VERSION ""

NS_ :

BS_:

BU_: TBox

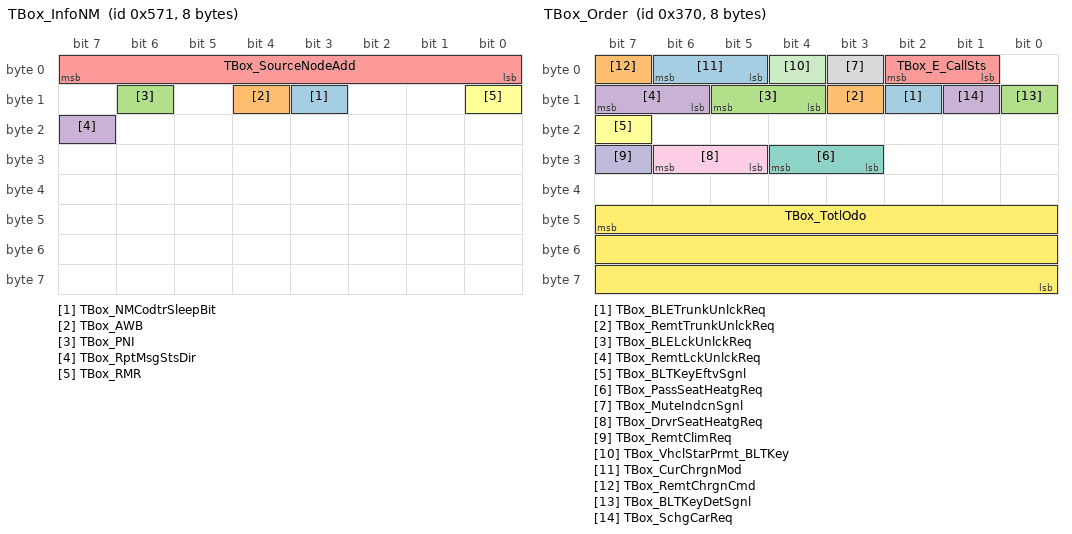
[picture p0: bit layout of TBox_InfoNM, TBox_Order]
BO_ 1393 TBox_InfoNM: 8 TBox
 SG_ TBox_NMCodtrSleepBit : 11|1@0+ (1,0) [0|1] "" HU,AMP,CGW
 SG_ TBox_AWB : 12|1@0+ (1,0) [0|1] "" HU,AMP,CGW
 SG_ TBox_PNI : 14|1@0+ (1,0) [0|1] "" HU,AMP,CGW
 SG_ TBox_RptMsgStsDir : 23|1@0+ (1,0) [0|1] "" Vector__XXX
 SG_ TBox_SourceNodeAdd : 7|8@0+ (1,0) [113|113] "" HU,AMP,CGW
 SG_ TBox_RMR : 8|1@0+ (1,0) [0|1] "" HU,AMP,CGW

BO_ 880 TBox_Order: 8 TBox
 SG_ TBox_BLETrunkUnlckReq : 10|1@0+ (1,0) [0|1] "" CGW
 SG_ TBox_RemtTrunkUnlckReq : 11|1@0+ (1,0) [0|1] "" CGW
 SG_ TBox_BLELckUnlckReq : 13|2@0+ (1,0) [0|3] "" CGW
 SG_ TBox_RemtLckUnlckReq : 15|2@0+ (1,0) [0|3] "" CGW
 SG_ TBox_E_CallSts : 2|2@0+ (1,0) [0|3] "" HU,CGW
 SG_ TBox_BLTKeyEftvSgnl : 23|1@0+ (1,0) [0|1] "" CGW
 SG_ TBox_PassSeatHeatgReq : 28|2@0+ (1,0) [0|3] "" CGW
 SG_ TBox_MuteIndcnSgnl : 3|1@0+ (1,0) [0|1] "" HU,CGW
 SG_ TBox_DrvrSeatHeatgReq : 30|2@0+ (1,0) [0|3] "" CGW
 SG_ TBox_RemtClimReq : 31|1@0+ (1,0) [0|1] "" CGW
 SG_ TBox_VhclStarPrmt_BLTKey : 4|1@0+ (1,0) [0|1] "" CGW
 SG_ TBox_TotlOdo : 47|24@0+ (0.1,0) [0|999999.9] "km" HU,CGW
 SG_ TBox_CurChrgnMod : 6|2@0+ (1,0) [0|3] "" HU,CGW
 SG_ TBox_RemtChrgnCmd : 7|1@0+ (1,0) [0|1] "" CGW
 SG_ TBox_BLTKeyDetSgnl : 8|1@0+ (1,0) [0|1] "" CGW
 SG_ TBox_SchgCarReq : 9|1@0+ (1,0) [0|1] "" CGW

BO_ 15 ACU_CrshInd: 8 CGW
 SG_ ACU_CrshActv : 7|3@0+ (1,0) [0|7] "" TBox

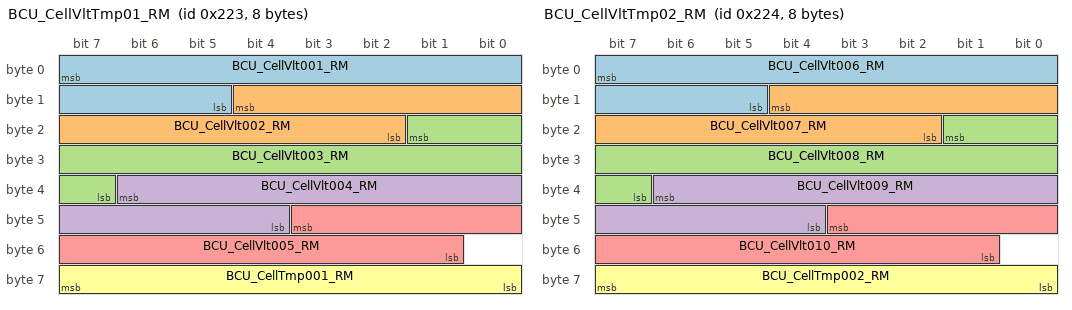
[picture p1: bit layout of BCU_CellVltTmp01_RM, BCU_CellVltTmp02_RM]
BO_ 547 BCU_CellVltTmp01_RM: 8 CGW
 SG_ BCU_CellVlt001_RM : 7|11@0+ (0.01,0) [0|18] "V" TBox
 SG_ BCU_CellVlt002_RM : 12|11@0+ (0.01,0) [0|18] "V" TBox
 SG_ BCU_CellVlt003_RM : 17|11@0+ (0.01,0) [0|18] "V" TBox
 SG_ BCU_CellVlt004_RM : 38|11@0+ (0.01,0) [0|18] "V" TBox
 SG_ BCU_CellVlt005_RM : 43|11@0+ (0.01,0) [0|18] "V" TBox
 SG_ BCU_CellTmp001_RM : 63|8@0+ (1,-40) [-40|120] "℃" TBox

BO_ 548 BCU_CellVltTmp02_RM: 8 CGW
 SG_ BCU_CellVlt006_RM : 7|11@0+ (0.01,0) [0|18] "V" TBox
 SG_ BCU_CellVlt007_RM : 12|11@0+ (0.01,0) [0|18] "V" TBox
 SG_ BCU_CellVlt008_RM : 17|11@0+ (0.01,0) [0|18] "V" TBox
 SG_ BCU_CellVlt009_RM : 38|11@0+ (0.01,0) [0|18] "V" TBox
 SG_ BCU_CellVlt010_RM : 43|11@0+ (0.01,0) [0|18] "V" TBox
 SG_ BCU_CellTmp002_RM : 63|8@0+ (1,-40) [-40|120] "℃" TBox

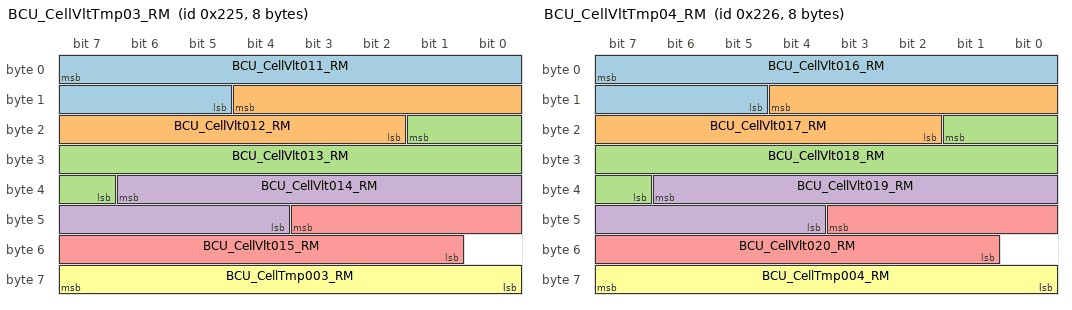
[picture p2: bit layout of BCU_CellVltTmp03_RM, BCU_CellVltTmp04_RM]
BO_ 549 BCU_CellVltTmp03_RM: 8 CGW
 SG_ BCU_CellVlt011_RM : 7|11@0+ (0.01,0) [0|18] "V" TBox
 SG_ BCU_CellVlt012_RM : 12|11@0+ (0.01,0) [0|18] "V" TBox
 SG_ BCU_CellVlt013_RM : 17|11@0+ (0.01,0) [0|18] "V" TBox
 SG_ BCU_CellVlt014_RM : 38|11@0+ (0.01,0) [0|18] "V" TBox
 SG_ BCU_CellVlt015_RM : 43|11@0+ (0.01,0) [0|18] "V" TBox
 SG_ BCU_CellTmp003_RM : 63|8@0+ (1,-40) [-40|120] "℃" TBox

BO_ 550 BCU_CellVltTmp04_RM: 8 CGW
 SG_ BCU_CellVlt016_RM : 7|11@0+ (0.01,0) [0|18] "V" TBox
 SG_ BCU_CellVlt017_RM : 12|11@0+ (0.01,0) [0|18] "V" TBox
 SG_ BCU_CellVlt018_RM : 17|11@0+ (0.01,0) [0|18] "V" TBox
 SG_ BCU_CellVlt019_RM : 38|11@0+ (0.01,0) [0|18] "V" TBox
 SG_ BCU_CellVlt020_RM : 43|11@0+ (0.01,0) [0|18] "V" TBox
 SG_ BCU_CellTmp004_RM : 63|8@0+ (1,-40) [-40|120] "℃" TBox

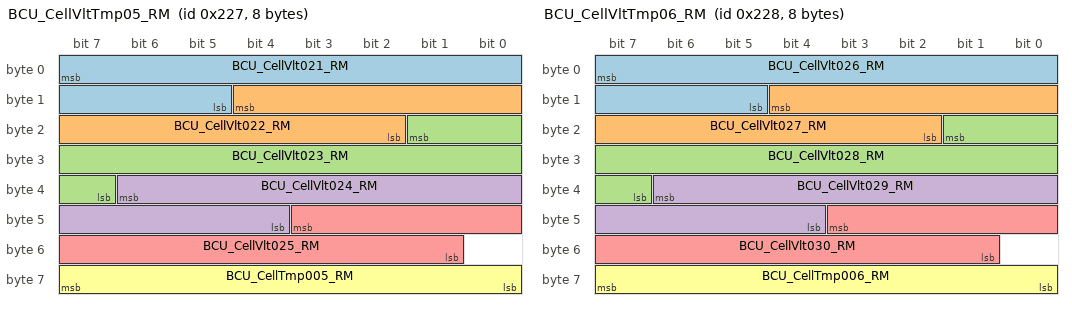
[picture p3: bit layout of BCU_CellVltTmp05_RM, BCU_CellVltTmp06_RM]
BO_ 551 BCU_CellVltTmp05_RM: 8 CGW
 SG_ BCU_CellVlt021_RM : 7|11@0+ (0.01,0) [0|18] "V" TBox
 SG_ BCU_CellVlt022_RM : 12|11@0+ (0.01,0) [0|18] "V" TBox
 SG_ BCU_CellVlt023_RM : 17|11@0+ (0.01,0) [0|18] "V" TBox
 SG_ BCU_CellVlt024_RM : 38|11@0+ (0.01,0) [0|18] "V" TBox
 SG_ BCU_CellVlt025_RM : 43|11@0+ (0.01,0) [0|18] "V" TBox
 SG_ BCU_CellTmp005_RM : 63|8@0+ (1,-40) [-40|120] "℃" TBox

BO_ 552 BCU_CellVltTmp06_RM: 8 CGW
 SG_ BCU_CellVlt026_RM : 7|11@0+ (0.01,0) [0|18] "V" TBox
 SG_ BCU_CellVlt027_RM : 12|11@0+ (0.01,0) [0|18] "V" TBox
 SG_ BCU_CellVlt028_RM : 17|11@0+ (0.01,0) [0|18] "V" TBox
 SG_ BCU_CellVlt029_RM : 38|11@0+ (0.01,0) [0|18] "V" TBox
 SG_ BCU_CellVlt030_RM : 43|11@0+ (0.01,0) [0|18] "V" TBox
 SG_ BCU_CellTmp006_RM : 63|8@0+ (1,-40) [-40|120] "℃" TBox

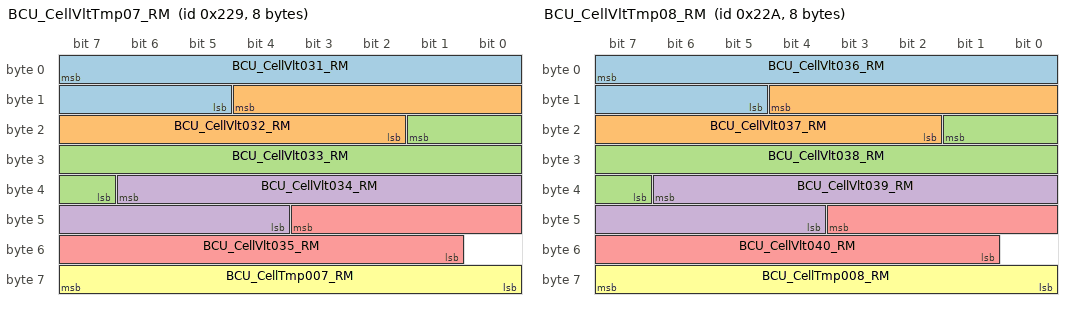
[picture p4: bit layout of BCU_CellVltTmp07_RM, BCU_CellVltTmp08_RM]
BO_ 553 BCU_CellVltTmp07_RM: 8 CGW
 SG_ BCU_CellVlt031_RM : 7|11@0+ (0.01,0) [0|18] "V" TBox
 SG_ BCU_CellVlt032_RM : 12|11@0+ (0.01,0) [0|18] "V" TBox
 SG_ BCU_CellVlt033_RM : 17|11@0+ (0.01,0) [0|18] "V" TBox
 SG_ BCU_CellVlt034_RM : 38|11@0+ (0.01,0) [0|18] "V" TBox
 SG_ BCU_CellVlt035_RM : 43|11@0+ (0.01,0) [0|18] "V" TBox
 SG_ BCU_CellTmp007_RM : 63|8@0+ (1,-40) [-40|120] "℃" TBox

BO_ 554 BCU_CellVltTmp08_RM: 8 CGW
 SG_ BCU_CellVlt036_RM : 7|11@0+ (0.01,0) [0|18] "V" TBox
 SG_ BCU_CellVlt037_RM : 12|11@0+ (0.01,0) [0|18] "V" TBox
 SG_ BCU_CellVlt038_RM : 17|11@0+ (0.01,0) [0|18] "V" TBox
 SG_ BCU_CellVlt039_RM : 38|11@0+ (0.01,0) [0|18] "V" TBox
 SG_ BCU_CellVlt040_RM : 43|11@0+ (0.01,0) [0|18] "V" TBox
 SG_ BCU_CellTmp008_RM : 63|8@0+ (1,-40) [-40|120] "℃" TBox

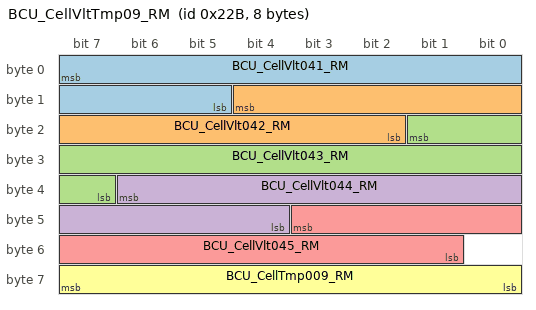
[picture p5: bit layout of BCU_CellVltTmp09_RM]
BO_ 555 BCU_CellVltTmp09_RM: 8 CGW
 SG_ BCU_CellVlt041_RM : 7|11@0+ (0.01,0) [0|18] "V" TBox
 SG_ BCU_CellVlt042_RM : 12|11@0+ (0.01,0) [0|18] "V" TBox
 SG_ BCU_CellVlt043_RM : 17|11@0+ (0.01,0) [0|18] "V" TBox
 SG_ BCU_CellVlt044_RM : 38|11@0+ (0.01,0) [0|18] "V" TBox
 SG_ BCU_CellVlt045_RM : 43|11@0+ (0.01,0) [0|18] "V" TBox
 SG_ BCU_CellTmp009_RM : 63|8@0+ (1,-40) [-40|120] "℃" TBox

CM_ " ";

CM_ SG_ 880 TBox_BLETrunkUnlckReq "TBox_BLETrunkUnlockReq 
蓝牙后备箱解锁";
CM_ SG_ 880 TBox_RemtTrunkUnlckReq "TBox_RemoteTrunkUnlockReq 
远程后备箱解锁";
CM_ SG_ 880 TBox_BLELckUnlckReq "TBox_BLELockUnlockReq 
蓝牙解闭锁请求";
CM_ SG_ 880 TBox_RemtLckUnlckReq "TBox_RemoteLockUnlckReq 
远程解闭锁请求";
CM_ SG_ 880 TBox_E_CallSts "TBox_EmergencyCallStatus
一键呼叫通话状态";
CM_ SG_ 880 TBox_BLTKeyEftvSgnl "TBox_BLTKeyEffectiveSignal
蓝牙钥匙有效信号";
CM_ SG_ 880 TBox_PassSeatHeatgReq "TBox_PassengerSeatHeatingReq
副驾座椅加热请求";
CM_ SG_ 880 TBox_MuteIndcnSgnl "TBox_MuteIndicationSignal
静音指示信号";
CM_ SG_ 880 TBox_DrvrSeatHeatgReq "TBox_DriverSeatHeatingReq
主驾座椅加热请求";
CM_ SG_ 880 TBox_RemtClimReq "Remote Climate Request
远程空调功能请求";
CM_ SG_ 880 TBox_VhclStarPrmt_BLTKey "Vehicle Start Permission Through BLT Key
BLT钥匙启动车辆许可信号";
CM_ SG_ 880 TBox_TotlOdo "TBox_TotalOdometer
总里程";
CM_ SG_ 880 TBox_CurChrgnMod "Current Charging Mode
当前充电模式信号";
CM_ SG_ 880 TBox_RemtChrgnCmd "TBox_RemoteChargingCmd
远程充电指令";
CM_ SG_ 880 TBox_BLTKeyDetSgnl "TBox_BLTKeyDetecteSignal
蓝牙钥匙监测信号";
CM_ SG_ 880 TBox_SchgCarReq "TBox_SearchingCarReq
寻车请求";
CM_ SG_ 1393 TBox_NMCodtrSleepBit "NM Coordinator Sleep Bit
网络管理协调睡眠指示位";
CM_ SG_ 1393 TBox_AWB "Active wakeup bit
主动唤醒指示位";
CM_ SG_ 1393 TBox_PNI "Partial netwark information bit 
局部网络指示位";
CM_ SG_ 1393 TBox_RptMsgStsDir "Repeat message State Direction
重复报文状态指示位";
CM_ SG_ 1393 TBox_SourceNodeAdd "Source Node Address
原节点地址";
CM_ SG_ 1393 TBox_RMR "Repeat message request
重复报文请求";
CM_ SG_ 547 BCU_CellVlt001_RM "Cell voltage 001
单体电压001";
CM_ SG_ 547 BCU_CellVlt002_RM "Cell voltage 002
单体电压002";
CM_ SG_ 547 BCU_CellVlt003_RM "Cell voltage 003
单体电压003";
CM_ SG_ 547 BCU_CellVlt004_RM "Cell voltage 004
单体电压004";
CM_ SG_ 547 BCU_CellVlt005_RM "Cell voltage 005
单体电压005";
CM_ SG_ 547 BCU_CellTmp001_RM "Cell temperature001
单体温度001";
CM_ SG_ 548 BCU_CellVlt006_RM "Cell voltage 006
单体电压006";
CM_ SG_ 548 BCU_CellVlt007_RM "Cell voltage 007
单体电压007";
CM_ SG_ 548 BCU_CellVlt008_RM "Cell voltage 008
单体电压008";
CM_ SG_ 548 BCU_CellVlt009_RM "Cell voltage 009
单体电压009";
CM_ SG_ 548 BCU_CellVlt010_RM "Cell voltage 010
单体电压010";
CM_ SG_ 548 BCU_CellTmp002_RM "Cell temperature 002
单体温度002";
CM_ SG_ 549 BCU_CellVlt011_RM "Cell voltage 011
单体电压011";
CM_ SG_ 549 BCU_CellVlt012_RM "Cell voltage 012
单体电压012";
CM_ SG_ 549 BCU_CellVlt013_RM "Cell voltage 013
单体电压013";
CM_ SG_ 549 BCU_CellVlt014_RM "Cell voltage 014
单体电压014";
CM_ SG_ 549 BCU_CellVlt015_RM "Cell voltage 015
单体电压015";
CM_ SG_ 549 BCU_CellTmp003_RM "Cell temperature 003
单体温度003";
CM_ SG_ 550 BCU_CellVlt016_RM "Cell voltage 016
单体电压016";
CM_ SG_ 550 BCU_CellVlt017_RM "Cell voltage 017
单体电压017";
CM_ SG_ 550 BCU_CellVlt018_RM "Cell voltage 018
单体电压018";
CM_ SG_ 550 BCU_CellVlt019_RM "Cell voltage 019
单体电压019";
CM_ SG_ 550 BCU_CellVlt020_RM "Cell voltage 020
单体电压020";
CM_ SG_ 550 BCU_CellTmp004_RM "Cell temperature 004
单体温度004";
CM_ SG_ 551 BCU_CellVlt021_RM "Cell voltage 021
单体电压021";
CM_ SG_ 551 BCU_CellVlt022_RM "Cell voltage 022
单体电压022";
CM_ SG_ 551 BCU_CellVlt023_RM "Cell voltage 023
单体电压023";
CM_ SG_ 551 BCU_CellVlt024_RM "Cell voltage 024
单体电压024";
CM_ SG_ 551 BCU_CellVlt025_RM "Cell voltage 025
单体电压025";
CM_ SG_ 551 BCU_CellTmp005_RM "Cell temperature 005
单体温度005";
CM_ SG_ 552 BCU_CellVlt026_RM "Cell voltage 026
单体电压026";
CM_ SG_ 552 BCU_CellVlt027_RM "Cell voltage 0267
单体电压027";
CM_ SG_ 552 BCU_CellVlt028_RM "Cell voltage 028
单体电压028";
CM_ SG_ 552 BCU_CellVlt029_RM "Cell voltage 029
单体电压029";
CM_ SG_ 552 BCU_CellVlt030_RM "Cell voltage 030
单体电压030";
CM_ SG_ 552 BCU_CellTmp006_RM "Cell temperature 006
单体温度006";
CM_ SG_ 553 BCU_CellVlt031_RM "Cell voltage 031
单体电压031";
CM_ SG_ 553 BCU_CellVlt032_RM "Cell voltage 032
单体电压032";
CM_ SG_ 553 BCU_CellVlt033_RM "Cell voltage 033
单体电压033";
CM_ SG_ 553 BCU_CellVlt034_RM "Cell voltage 034
单体电压034";
CM_ SG_ 553 BCU_CellVlt035_RM "Cell voltage 035
单体电压035";
CM_ SG_ 553 BCU_CellTmp007_RM "Cell temperature 007
单体温度007";
CM_ SG_ 554 BCU_CellVlt036_RM "Cell voltage 036
单体电压036";
CM_ SG_ 554 BCU_CellVlt037_RM "Cell voltage 037
单体电压037";
CM_ SG_ 554 BCU_CellVlt038_RM "Cell voltage 038
单体电压038";
CM_ SG_ 554 BCU_CellVlt039_RM "Cell voltage 0369
单体电压039";
CM_ SG_ 554 BCU_CellVlt040_RM "Cell voltage 040
单体电压040";
CM_ SG_ 554 BCU_CellTmp008_RM "Cell temperature 008
单体温度008";
CM_ SG_ 555 BCU_CellVlt041_RM "Cell voltage 041
单体电压041";
CM_ SG_ 555 BCU_CellVlt042_RM "Cell voltage 042
单体电压042";
CM_ SG_ 555 BCU_CellVlt043_RM "Cell voltage 043
单体电压043";
CM_ SG_ 555 BCU_CellVlt044_RM "Cell voltage 044
单体电压044";
CM_ SG_ 555 BCU_CellVlt045_RM "Cell voltage 045
单体电压045";
CM_ SG_ 555 BCU_CellTmp009_RM "Cell temperature 009
单体温度009";
CM_ SG_ 15 ACU_CrshActv "Crash Active";

BA_DEF_ BO_  "NmMessage" ENUM "No","Yes";
BA_DEF_ BO_  "GenMsgSendType" ENUM  "Cycle","CA","CE","Event","NotUsed","NotUsed","NotUsed","IfActive","NoMsgSendType","NotUsed";
BA_DEF_ BO_  "GenMsgCycleTime" INT 0 0;
BA_DEF_ SG_  "GenSigSendType" ENUM  "Cycle","OnChange","OnWrite","IfActive","OnChangeWithRepetition","OnWriteWithRepetition","IfActiveWithRepetition";
BA_DEF_ SG_  "GenSigStartValue" INT 0 0;
BA_DEF_ BO_  "GenMsgCycleTimeFast" INT 0 0;
BA_DEF_ BO_  "GenMsgNrOfRepetition" INT 0 0;
BA_DEF_ BO_  "GenMsgDelayTime" INT 0 0;
BA_DEF_  "DBName" STRING ;
BA_DEF_ BO_  "VFrameFormat" ENUM  "StandardCAN","ExtendedCAN","reserved","reserved","reserved","reserved","reserved","reserved","reserved","reserved","reserved","reserved","reserved","reserved","StandardCAN_FD","ExtendedCAN_FD";
BA_DEF_ BU_  "NodeLayerModules" STRING ;
BA_DEF_ BO_  "GenMsgCycleTimeActive" INT 0 500;
BA_DEF_ BU_  "NmNode" ENUM  "Not","Yes";
BA_DEF_  "NmBaseAddress" HEX 1280 1535;
BA_DEF_ BO_  "GenMsgStartDelayTime" INT 0 500;
BA_DEF_  "BusType" STRING ;

BA_DEF_DEF_  "NmMessage" "No";
BA_DEF_DEF_  "GenMsgSendType" "Cycle";
BA_DEF_DEF_  "GenMsgCycleTime" 0;
BA_DEF_DEF_  "GenSigSendType" "Cycle";
BA_DEF_DEF_  "GenSigStartValue" 0;
BA_DEF_DEF_  "GenMsgCycleTimeFast" 0;
BA_DEF_DEF_  "GenMsgNrOfRepetition" 0;
BA_DEF_DEF_  "GenMsgDelayTime" 0;
BA_DEF_DEF_  "DBName" "";
BA_DEF_DEF_  "VFrameFormat" "StandardCAN";
BA_DEF_DEF_  "NodeLayerModules" "oseknm01.dll,osek_tp.dll,CANoeILNLVector.dll";
BA_DEF_DEF_  "GenMsgCycleTimeActive" 100;
BA_DEF_DEF_  "NmNode" "Not";
BA_DEF_DEF_  "NmBaseAddress" 1280;
BA_DEF_DEF_  "GenMsgStartDelayTime" 200;
BA_DEF_DEF_  "BusType" "CAN";
BA_ "DBName" "Info";
BA_ "NmMessage" BO_ 1393 1;
BA_ "GenMsgSendType" BO_ 1393 2;
BA_ "GenMsgCycleTime" BO_ 1393 500;
BA_ "GenMsgCycleTimeFast" BO_ 1393 10;
BA_ "GenMsgNrOfRepetition" BO_ 1393 5;
BA_ "GenSigSendType" SG_ 1393 TBox_AWB 5;
BA_ "GenSigStartValue" SG_ 1393 TBox_SourceNodeAdd 113;
BA_ "GenSigSendType" SG_ 1393 TBox_RMR 5;
BA_ "GenMsgSendType" BO_ 880 2;
BA_ "GenMsgCycleTime" BO_ 880 50;
BA_ "GenMsgCycleTimeFast" BO_ 880 10;
BA_ "GenMsgNrOfRepetition" BO_ 880 3;
BA_ "GenSigSendType" SG_ 880 TBox_TotlOdo 2;
BA_ "GenMsgSendType" BO_ 15 2;
BA_ "GenMsgCycleTime" BO_ 15 1000;
BA_ "GenMsgCycleTimeFast" BO_ 15 20;
BA_ "GenMsgNrOfRepetition" BO_ 15 100;
BA_ "GenMsgDelayTime" BO_ 15 10;
BA_ "GenSigSendType" SG_ 15 ACU_CrshActv 4;
BA_ "GenMsgCycleTime" BO_ 547 1000;
BA_ "GenSigStartValue" SG_ 547 BCU_CellTmp001_RM 40;
BA_ "GenMsgCycleTime" BO_ 548 1000;
BA_ "GenSigStartValue" SG_ 548 BCU_CellTmp002_RM 40;
BA_ "GenMsgCycleTime" BO_ 549 1000;
BA_ "GenSigStartValue" SG_ 549 BCU_CellTmp003_RM 40;
BA_ "GenMsgCycleTime" BO_ 550 1000;
BA_ "GenSigStartValue" SG_ 550 BCU_CellTmp004_RM 40;
BA_ "GenMsgCycleTime" BO_ 551 1000;
BA_ "GenSigStartValue" SG_ 551 BCU_CellTmp005_RM 40;
BA_ "GenMsgCycleTime" BO_ 552 1000;
BA_ "GenSigStartValue" SG_ 552 BCU_CellTmp006_RM 40;
BA_ "GenMsgCycleTime" BO_ 553 1000;
BA_ "GenSigStartValue" SG_ 553 BCU_CellTmp007_RM 40;
BA_ "GenMsgCycleTime" BO_ 554 1000;
BA_ "GenSigStartValue" SG_ 554 BCU_CellTmp008_RM 40;
BA_ "GenMsgCycleTime" BO_ 555 1000;
BA_ "GenSigStartValue" SG_ 555 BCU_CellTmp009_RM 40;
VAL_ 880 TBox_BLETrunkUnlckReq 1 "Request Unlock" 0 "No Request" ;
VAL_ 880 TBox_RemtTrunkUnlckReq 1 "Request Unlock" 0 "No Request" ;
VAL_ 880 TBox_BLELckUnlckReq 3 "Reserved" 2 "Request Unlock" 1 "Request lock" 0 "No Request" ;
VAL_ 880 TBox_RemtLckUnlckReq 3 "Reserved" 2 "Request Unlock" 1 "Request lock" 0 "No Request" ;
VAL_ 880 TBox_E_CallSts 3 "Hang up" 2 "Call connection" 1 "Dialing" 0 "No request" ;
VAL_ 880 TBox_BLTKeyEftvSgnl 1 "Effective Key" 0 "Noneffective Key" ;
VAL_ 880 TBox_PassSeatHeatgReq 3 "Reserved" 2 "Passenger Seat Heating off" 1 "Passenger Seat Heating on" 0 "No Request" ;
VAL_ 880 TBox_MuteIndcnSgnl 1 "Request Muting" 0 "No Request" ;
VAL_ 880 TBox_DrvrSeatHeatgReq 3 "Reserved" 2 "Driver Seat Heating off" 1 "Driver Seat Heating on" 0 "No Request" ;
VAL_ 880 TBox_RemtClimReq 1 "Request" 0 "Not Request" ;
VAL_ 880 TBox_VhclStarPrmt_BLTKey 1 "Permission" 0 "Not Permission" ;
VAL_ 880 TBox_TotlOdo 16777215 "Invalid" ;
VAL_ 880 TBox_CurChrgnMod 3 "Reserved" 2 "Reserved" 1 "Remote Charging Mode" 0 "Normal Charging Mode" ;
VAL_ 880 TBox_RemtChrgnCmd 1 "Allowed charging" 0 "Not allowed charging" ;
VAL_ 880 TBox_BLTKeyDetSgnl 1 "Detected Key" 0 "Not Detected Key" ;
VAL_ 880 TBox_SchgCarReq 1 "Request Searching Car" 0 "No Request" ;
VAL_ 1393 TBox_NMCodtrSleepBit 1 "Synch Shutdwn Req by codtr" 0 "Synch Shutdwn NotReq by codtr" ;
VAL_ 1393 TBox_AWB 1 "Active wakeup" 0 "Passive wakeup" ;
VAL_ 1393 TBox_PNI 1 "Contain PNI" 0 "Contain no PNI" ;
VAL_ 1393 TBox_RptMsgStsDir 1 "On Repeat message State" 0 "Not on Repeat message State" ;
VAL_ 1393 TBox_RMR 1 "Rpt Msg state req" 0 "Rpt Msg state not req" ;
VAL_ 547 BCU_CellVlt001_RM 2047 "Invalid" 2046 "Invalid" 2045 "Invalid" 2044 "Invalid" 2043 "Invalid" 2042 "Invalid" 2041 "Invalid" 2040 "Invalid" 2039 "Invalid" 2038 "Invalid" 2037 "Invalid" 2036 "Invalid" 2035 "Invalid" 2034 "Invalid" 2033 "Invalid" 2032 "Invalid" 2031 "Invalid" 2030 "Invalid" 2029 "Invalid" 2028 "Invalid" 2027 "Invalid" 2026 "Invalid" 2025 "Invalid" 2024 "Invalid" 2023 "Invalid" 2022 "Invalid" 2021 "Invalid" 2020 "Invalid" 2019 "Invalid" 2018 "Invalid" 2017 "Invalid" 2016 "Invalid" 2015 "Invalid" 2014 "Invalid" 2013 "Invalid" 2012 "Invalid" 2011 "Invalid" 2010 "Invalid" 2009 "Invalid" 2008 "Invalid" 2007 "Invalid" 2006 "Invalid" 2005 "Invalid" 2004 "Invalid" 2003 "Invalid" 2002 "Invalid" 2001 "Invalid" 2000 "Invalid" 1999 "Invalid" 1998 "Invalid" 1997 "Invalid" 1996 "Invalid" 1995 "Invalid" 1994 "Invalid" 1993 "Invalid" 1992 "Invalid" 1991 "Invalid" 1990 "Invalid" 1989 "Invalid" 1988 "Invalid" 1987 "Invalid" 1986 "Invalid" 1985 "Invalid" 1984 "Invalid" 1983 "Invalid" 1982 "Invalid" 1981 "Invalid" 1980 "Invalid" 1979 "Invalid" 1978 "Invalid" 1977 "Invalid" 1976 "Invalid" 1975 "Invalid" 1974 "Invalid" 1973 "Invalid" 1972 "Invalid" 1971 "Invalid" 1970 "Invalid" 1969 "Invalid" 1968 "Invalid" 1967 "Invalid" 1966 "Invalid" 1965 "Invalid" 1964 "Invalid" 1963 "Invalid" 1962 "Invalid" 1961 "Invalid" 1960 "Invalid" 1959 "Invalid" 1958 "Invalid" 1957 "Invalid" 1956 "Invalid" 1955 "Invalid" 1954 "Invalid" 1953 "Invalid" 1952 "Invalid" 1951 "Invalid" 1950 "Invalid" 1949 "Invalid" 1948 "Invalid" 1947 "Invalid" 1946 "Invalid" 1945 "Invalid" 1944 "Invalid" 1943 "Invalid" 1942 "Invalid" 1941 "Invalid" 1940 "Invalid" 1939 "Invalid" 1938 "Invalid" 1937 "Invalid" 1936 "Invalid" 1935 "Invalid" 1934 "Invalid" 1933 "Invalid" 1932 "Invalid" 1931 "Invalid" 1930 "Invalid" 1929 "Invalid" 1928 "Invalid" 1927 "Invalid" 1926 "Invalid" 1925 "Invalid" 1924 "Invalid" 1923 "Invalid" 1922 "Invalid" 1921 "Invalid" 1920 "Invalid" 1919 "Invalid" 1918 "Invalid" 1917 "Invalid" 1916 "Invalid" 1915 "Invalid" 1914 "Invalid" 1913 "Invalid" 1912 "Invalid" 1911 "Invalid" 1910 "Invalid" 1909 "Invalid" 1908 "Invalid" 1907 "Invalid" 1906 "Invalid" 1905 "Invalid" 1904 "Invalid" 1903 "Invalid" 1902 "Invalid" 1901 "Invalid" 1900 "Invalid" 1899 "Invalid" 1898 "Invalid" 1897 "Invalid" 1896 "Invalid" 1895 "Invalid" 1894 "Invalid" 1893 "Invalid" 1892 "Invalid" 1891 "Invalid" 1890 "Invalid" 1889 "Invalid" 1888 "Invalid" 1887 "Invalid" 1886 "Invalid" 1885 "Invalid" 1884 "Invalid" 1883 "Invalid" 1882 "Invalid" 1881 "Invalid" 1880 "Invalid" 1879 "Invalid" 1878 "Invalid" 1877 "Invalid" 1876 "Invalid" 1875 "Invalid" 1874 "Invalid" 1873 "Invalid" 1872 "Invalid" 1871 "Invalid" 1870 "Invalid" 1869 "Invalid" 1868 "Invalid" 1867 "Invalid" 1866 "Invalid" 1865 "Invalid" 1864 "Invalid" 1863 "Invalid" 1862 "Invalid" 1861 "Invalid" 1860 "Invalid" 1859 "Invalid" 1858 "Invalid" 1857 "Invalid" 1856 "Invalid" 1855 "Invalid" 1854 "Invalid" 1853 "Invalid" 1852 "Invalid" 1851 "Invalid" 1850 "Invalid" 1849 "Invalid" 1848 "Invalid" 1847 "Invalid" 1846 "Invalid" 1845 "Invalid" 1844 "Invalid" 1843 "Invalid" 1842 "Invalid" 1841 "Invalid" 1840 "Invalid" 1839 "Invalid" 1838 "Invalid" 1837 "Invalid" 1836 "Invalid" 1835 "Invalid" 1834 "Invalid" 1833 "Invalid" 1832 "Invalid" 1831 "Invalid" 1830 "Invalid" 1829 "Invalid" 1828 "Invalid" 1827 "Invalid" 1826 "Invalid" 1825 "Invalid" 1824 "Invalid" 1823 "Invalid" 1822 "Invalid" 1821 "Invalid" 1820 "Invalid" 1819 "Invalid" 1818 "Invalid" 1817 "Invalid" 1816 "Invalid" 1815 "Invalid" 1814 "Invalid" 1813 "Invalid" 1812 "Invalid" 1811 "Invalid" 1810 "Invalid" 1809 "Invalid" 1808 "Invalid" 1807 "Invalid" 1806 "Invalid" 1805 "Invalid" 1804 "Invalid" 1803 "Invalid" 1802 "Invalid" 1801 "Invalid" ;
VAL_ 547 BCU_CellVlt002_RM 2047 "Invalid" 2046 "Invalid" 2045 "Invalid" 2044 "Invalid" 2043 "Invalid" 2042 "Invalid" 2041 "Invalid" 2040 "Invalid" 2039 "Invalid" 2038 "Invalid" 2037 "Invalid" 2036 "Invalid" 2035 "Invalid" 2034 "Invalid" 2033 "Invalid" 2032 "Invalid" 2031 "Invalid" 2030 "Invalid" 2029 "Invalid" 2028 "Invalid" 2027 "Invalid" 2026 "Invalid" 2025 "Invalid" 2024 "Invalid" 2023 "Invalid" 2022 "Invalid" 2021 "Invalid" 2020 "Invalid" 2019 "Invalid" 2018 "Invalid" 2017 "Invalid" 2016 "Invalid" 2015 "Invalid" 2014 "Invalid" 2013 "Invalid" 2012 "Invalid" 2011 "Invalid" 2010 "Invalid" 2009 "Invalid" 2008 "Invalid" 2007 "Invalid" 2006 "Invalid" 2005 "Invalid" 2004 "Invalid" 2003 "Invalid" 2002 "Invalid" 2001 "Invalid" 2000 "Invalid" 1999 "Invalid" 1998 "Invalid" 1997 "Invalid" 1996 "Invalid" 1995 "Invalid" 1994 "Invalid" 1993 "Invalid" 1992 "Invalid" 1991 "Invalid" 1990 "Invalid" 1989 "Invalid" 1988 "Invalid" 1987 "Invalid" 1986 "Invalid" 1985 "Invalid" 1984 "Invalid" 1983 "Invalid" 1982 "Invalid" 1981 "Invalid" 1980 "Invalid" 1979 "Invalid" 1978 "Invalid" 1977 "Invalid" 1976 "Invalid" 1975 "Invalid" 1974 "Invalid" 1973 "Invalid" 1972 "Invalid" 1971 "Invalid" 1970 "Invalid" 1969 "Invalid" 1968 "Invalid" 1967 "Invalid" 1966 "Invalid" 1965 "Invalid" 1964 "Invalid" 1963 "Invalid" 1962 "Invalid" 1961 "Invalid" 1960 "Invalid" 1959 "Invalid" 1958 "Invalid" 1957 "Invalid" 1956 "Invalid" 1955 "Invalid" 1954 "Invalid" 1953 "Invalid" 1952 "Invalid" 1951 "Invalid" 1950 "Invalid" 1949 "Invalid" 1948 "Invalid" 1947 "Invalid" 1946 "Invalid" 1945 "Invalid" 1944 "Invalid" 1943 "Invalid" 1942 "Invalid" 1941 "Invalid" 1940 "Invalid" 1939 "Invalid" 1938 "Invalid" 1937 "Invalid" 1936 "Invalid" 1935 "Invalid" 1934 "Invalid" 1933 "Invalid" 1932 "Invalid" 1931 "Invalid" 1930 "Invalid" 1929 "Invalid" 1928 "Invalid" 1927 "Invalid" 1926 "Invalid" 1925 "Invalid" 1924 "Invalid" 1923 "Invalid" 1922 "Invalid" 1921 "Invalid" 1920 "Invalid" 1919 "Invalid" 1918 "Invalid" 1917 "Invalid" 1916 "Invalid" 1915 "Invalid" 1914 "Invalid" 1913 "Invalid" 1912 "Invalid" 1911 "Invalid" 1910 "Invalid" 1909 "Invalid" 1908 "Invalid" 1907 "Invalid" 1906 "Invalid" 1905 "Invalid" 1904 "Invalid" 1903 "Invalid" 1902 "Invalid" 1901 "Invalid" 1900 "Invalid" 1899 "Invalid" 1898 "Invalid" 1897 "Invalid" 1896 "Invalid" 1895 "Invalid" 1894 "Invalid" 1893 "Invalid" 1892 "Invalid" 1891 "Invalid" 1890 "Invalid" 1889 "Invalid" 1888 "Invalid" 1887 "Invalid" 1886 "Invalid" 1885 "Invalid" 1884 "Invalid" 1883 "Invalid" 1882 "Invalid" 1881 "Invalid" 1880 "Invalid" 1879 "Invalid" 1878 "Invalid" 1877 "Invalid" 1876 "Invalid" 1875 "Invalid" 1874 "Invalid" 1873 "Invalid" 1872 "Invalid" 1871 "Invalid" 1870 "Invalid" 1869 "Invalid" 1868 "Invalid" 1867 "Invalid" 1866 "Invalid" 1865 "Invalid" 1864 "Invalid" 1863 "Invalid" 1862 "Invalid" 1861 "Invalid" 1860 "Invalid" 1859 "Invalid" 1858 "Invalid" 1857 "Invalid" 1856 "Invalid" 1855 "Invalid" 1854 "Invalid" 1853 "Invalid" 1852 "Invalid" 1851 "Invalid" 1850 "Invalid" 1849 "Invalid" 1848 "Invalid" 1847 "Invalid" 1846 "Invalid" 1845 "Invalid" 1844 "Invalid" 1843 "Invalid" 1842 "Invalid" 1841 "Invalid" 1840 "Invalid" 1839 "Invalid" 1838 "Invalid" 1837 "Invalid" 1836 "Invalid" 1835 "Invalid" 1834 "Invalid" 1833 "Invalid" 1832 "Invalid" 1831 "Invalid" 1830 "Invalid" 1829 "Invalid" 1828 "Invalid" 1827 "Invalid" 1826 "Invalid" 1825 "Invalid" 1824 "Invalid" 1823 "Invalid" 1822 "Invalid" 1821 "Invalid" 1820 "Invalid" 1819 "Invalid" 1818 "Invalid" 1817 "Invalid" 1816 "Invalid" 1815 "Invalid" 1814 "Invalid" 1813 "Invalid" 1812 "Invalid" 1811 "Invalid" 1810 "Invalid" 1809 "Invalid" 1808 "Invalid" 1807 "Invalid" 1806 "Invalid" 1805 "Invalid" 1804 "Invalid" 1803 "Invalid" 1802 "Invalid" 1801 "Invalid" ;
VAL_ 547 BCU_CellVlt003_RM 2047 "Invalid" 2046 "Invalid" 2045 "Invalid" 2044 "Invalid" 2043 "Invalid" 2042 "Invalid" 2041 "Invalid" 2040 "Invalid" 2039 "Invalid" 2038 "Invalid" 2037 "Invalid" 2036 "Invalid" 2035 "Invalid" 2034 "Invalid" 2033 "Invalid" 2032 "Invalid" 2031 "Invalid" 2030 "Invalid" 2029 "Invalid" 2028 "Invalid" 2027 "Invalid" 2026 "Invalid" 2025 "Invalid" 2024 "Invalid" 2023 "Invalid" 2022 "Invalid" 2021 "Invalid" 2020 "Invalid" 2019 "Invalid" 2018 "Invalid" 2017 "Invalid" 2016 "Invalid" 2015 "Invalid" 2014 "Invalid" 2013 "Invalid" 2012 "Invalid" 2011 "Invalid" 2010 "Invalid" 2009 "Invalid" 2008 "Invalid" 2007 "Invalid" 2006 "Invalid" 2005 "Invalid" 2004 "Invalid" 2003 "Invalid" 2002 "Invalid" 2001 "Invalid" 2000 "Invalid" 1999 "Invalid" 1998 "Invalid" 1997 "Invalid" 1996 "Invalid" 1995 "Invalid" 1994 "Invalid" 1993 "Invalid" 1992 "Invalid" 1991 "Invalid" 1990 "Invalid" 1989 "Invalid" 1988 "Invalid" 1987 "Invalid" 1986 "Invalid" 1985 "Invalid" 1984 "Invalid" 1983 "Invalid" 1982 "Invalid" 1981 "Invalid" 1980 "Invalid" 1979 "Invalid" 1978 "Invalid" 1977 "Invalid" 1976 "Invalid" 1975 "Invalid" 1974 "Invalid" 1973 "Invalid" 1972 "Invalid" 1971 "Invalid" 1970 "Invalid" 1969 "Invalid" 1968 "Invalid" 1967 "Invalid" 1966 "Invalid" 1965 "Invalid" 1964 "Invalid" 1963 "Invalid" 1962 "Invalid" 1961 "Invalid" 1960 "Invalid" 1959 "Invalid" 1958 "Invalid" 1957 "Invalid" 1956 "Invalid" 1955 "Invalid" 1954 "Invalid" 1953 "Invalid" 1952 "Invalid" 1951 "Invalid" 1950 "Invalid" 1949 "Invalid" 1948 "Invalid" 1947 "Invalid" 1946 "Invalid" 1945 "Invalid" 1944 "Invalid" 1943 "Invalid" 1942 "Invalid" 1941 "Invalid" 1940 "Invalid" 1939 "Invalid" 1938 "Invalid" 1937 "Invalid" 1936 "Invalid" 1935 "Invalid" 1934 "Invalid" 1933 "Invalid" 1932 "Invalid" 1931 "Invalid" 1930 "Invalid" 1929 "Invalid" 1928 "Invalid" 1927 "Invalid" 1926 "Invalid" 1925 "Invalid" 1924 "Invalid" 1923 "Invalid" 1922 "Invalid" 1921 "Invalid" 1920 "Invalid" 1919 "Invalid" 1918 "Invalid" 1917 "Invalid" 1916 "Invalid" 1915 "Invalid" 1914 "Invalid" 1913 "Invalid" 1912 "Invalid" 1911 "Invalid" 1910 "Invalid" 1909 "Invalid" 1908 "Invalid" 1907 "Invalid" 1906 "Invalid" 1905 "Invalid" 1904 "Invalid" 1903 "Invalid" 1902 "Invalid" 1901 "Invalid" 1900 "Invalid" 1899 "Invalid" 1898 "Invalid" 1897 "Invalid" 1896 "Invalid" 1895 "Invalid" 1894 "Invalid" 1893 "Invalid" 1892 "Invalid" 1891 "Invalid" 1890 "Invalid" 1889 "Invalid" 1888 "Invalid" 1887 "Invalid" 1886 "Invalid" 1885 "Invalid" 1884 "Invalid" 1883 "Invalid" 1882 "Invalid" 1881 "Invalid" 1880 "Invalid" 1879 "Invalid" 1878 "Invalid" 1877 "Invalid" 1876 "Invalid" 1875 "Invalid" 1874 "Invalid" 1873 "Invalid" 1872 "Invalid" 1871 "Invalid" 1870 "Invalid" 1869 "Invalid" 1868 "Invalid" 1867 "Invalid" 1866 "Invalid" 1865 "Invalid" 1864 "Invalid" 1863 "Invalid" 1862 "Invalid" 1861 "Invalid" 1860 "Invalid" 1859 "Invalid" 1858 "Invalid" 1857 "Invalid" 1856 "Invalid" 1855 "Invalid" 1854 "Invalid" 1853 "Invalid" 1852 "Invalid" 1851 "Invalid" 1850 "Invalid" 1849 "Invalid" 1848 "Invalid" 1847 "Invalid" 1846 "Invalid" 1845 "Invalid" 1844 "Invalid" 1843 "Invalid" 1842 "Invalid" 1841 "Invalid" 1840 "Invalid" 1839 "Invalid" 1838 "Invalid" 1837 "Invalid" 1836 "Invalid" 1835 "Invalid" 1834 "Invalid" 1833 "Invalid" 1832 "Invalid" 1831 "Invalid" 1830 "Invalid" 1829 "Invalid" 1828 "Invalid" 1827 "Invalid" 1826 "Invalid" 1825 "Invalid" 1824 "Invalid" 1823 "Invalid" 1822 "Invalid" 1821 "Invalid" 1820 "Invalid" 1819 "Invalid" 1818 "Invalid" 1817 "Invalid" 1816 "Invalid" 1815 "Invalid" 1814 "Invalid" 1813 "Invalid" 1812 "Invalid" 1811 "Invalid" 1810 "Invalid" 1809 "Invalid" 1808 "Invalid" 1807 "Invalid" 1806 "Invalid" 1805 "Invalid" 1804 "Invalid" 1803 "Invalid" 1802 "Invalid" 1801 "Invalid" ;
VAL_ 547 BCU_CellVlt004_RM 2047 "Invalid" 2046 "Invalid" 2045 "Invalid" 2044 "Invalid" 2043 "Invalid" 2042 "Invalid" 2041 "Invalid" 2040 "Invalid" 2039 "Invalid" 2038 "Invalid" 2037 "Invalid" 2036 "Invalid" 2035 "Invalid" 2034 "Invalid" 2033 "Invalid" 2032 "Invalid" 2031 "Invalid" 2030 "Invalid" 2029 "Invalid" 2028 "Invalid" 2027 "Invalid" 2026 "Invalid" 2025 "Invalid" 2024 "Invalid" 2023 "Invalid" 2022 "Invalid" 2021 "Invalid" 2020 "Invalid" 2019 "Invalid" 2018 "Invalid" 2017 "Invalid" 2016 "Invalid" 2015 "Invalid" 2014 "Invalid" 2013 "Invalid" 2012 "Invalid" 2011 "Invalid" 2010 "Invalid" 2009 "Invalid" 2008 "Invalid" 2007 "Invalid" 2006 "Invalid" 2005 "Invalid" 2004 "Invalid" 2003 "Invalid" 2002 "Invalid" 2001 "Invalid" 2000 "Invalid" 1999 "Invalid" 1998 "Invalid" 1997 "Invalid" 1996 "Invalid" 1995 "Invalid" 1994 "Invalid" 1993 "Invalid" 1992 "Invalid" 1991 "Invalid" 1990 "Invalid" 1989 "Invalid" 1988 "Invalid" 1987 "Invalid" 1986 "Invalid" 1985 "Invalid" 1984 "Invalid" 1983 "Invalid" 1982 "Invalid" 1981 "Invalid" 1980 "Invalid" 1979 "Invalid" 1978 "Invalid" 1977 "Invalid" 1976 "Invalid" 1975 "Invalid" 1974 "Invalid" 1973 "Invalid" 1972 "Invalid" 1971 "Invalid" 1970 "Invalid" 1969 "Invalid" 1968 "Invalid" 1967 "Invalid" 1966 "Invalid" 1965 "Invalid" 1964 "Invalid" 1963 "Invalid" 1962 "Invalid" 1961 "Invalid" 1960 "Invalid" 1959 "Invalid" 1958 "Invalid" 1957 "Invalid" 1956 "Invalid" 1955 "Invalid" 1954 "Invalid" 1953 "Invalid" 1952 "Invalid" 1951 "Invalid" 1950 "Invalid" 1949 "Invalid" 1948 "Invalid" 1947 "Invalid" 1946 "Invalid" 1945 "Invalid" 1944 "Invalid" 1943 "Invalid" 1942 "Invalid" 1941 "Invalid" 1940 "Invalid" 1939 "Invalid" 1938 "Invalid" 1937 "Invalid" 1936 "Invalid" 1935 "Invalid" 1934 "Invalid" 1933 "Invalid" 1932 "Invalid" 1931 "Invalid" 1930 "Invalid" 1929 "Invalid" 1928 "Invalid" 1927 "Invalid" 1926 "Invalid" 1925 "Invalid" 1924 "Invalid" 1923 "Invalid" 1922 "Invalid" 1921 "Invalid" 1920 "Invalid" 1919 "Invalid" 1918 "Invalid" 1917 "Invalid" 1916 "Invalid" 1915 "Invalid" 1914 "Invalid" 1913 "Invalid" 1912 "Invalid" 1911 "Invalid" 1910 "Invalid" 1909 "Invalid" 1908 "Invalid" 1907 "Invalid" 1906 "Invalid" 1905 "Invalid" 1904 "Invalid" 1903 "Invalid" 1902 "Invalid" 1901 "Invalid" 1900 "Invalid" 1899 "Invalid" 1898 "Invalid" 1897 "Invalid" 1896 "Invalid" 1895 "Invalid" 1894 "Invalid" 1893 "Invalid" 1892 "Invalid" 1891 "Invalid" 1890 "Invalid" 1889 "Invalid" 1888 "Invalid" 1887 "Invalid" 1886 "Invalid" 1885 "Invalid" 1884 "Invalid" 1883 "Invalid" 1882 "Invalid" 1881 "Invalid" 1880 "Invalid" 1879 "Invalid" 1878 "Invalid" 1877 "Invalid" 1876 "Invalid" 1875 "Invalid" 1874 "Invalid" 1873 "Invalid" 1872 "Invalid" 1871 "Invalid" 1870 "Invalid" 1869 "Invalid" 1868 "Invalid" 1867 "Invalid" 1866 "Invalid" 1865 "Invalid" 1864 "Invalid" 1863 "Invalid" 1862 "Invalid" 1861 "Invalid" 1860 "Invalid" 1859 "Invalid" 1858 "Invalid" 1857 "Invalid" 1856 "Invalid" 1855 "Invalid" 1854 "Invalid" 1853 "Invalid" 1852 "Invalid" 1851 "Invalid" 1850 "Invalid" 1849 "Invalid" 1848 "Invalid" 1847 "Invalid" 1846 "Invalid" 1845 "Invalid" 1844 "Invalid" 1843 "Invalid" 1842 "Invalid" 1841 "Invalid" 1840 "Invalid" 1839 "Invalid" 1838 "Invalid" 1837 "Invalid" 1836 "Invalid" 1835 "Invalid" 1834 "Invalid" 1833 "Invalid" 1832 "Invalid" 1831 "Invalid" 1830 "Invalid" 1829 "Invalid" 1828 "Invalid" 1827 "Invalid" 1826 "Invalid" 1825 "Invalid" 1824 "Invalid" 1823 "Invalid" 1822 "Invalid" 1821 "Invalid" 1820 "Invalid" 1819 "Invalid" 1818 "Invalid" 1817 "Invalid" 1816 "Invalid" 1815 "Invalid" 1814 "Invalid" 1813 "Invalid" 1812 "Invalid" 1811 "Invalid" 1810 "Invalid" 1809 "Invalid" 1808 "Invalid" 1807 "Invalid" 1806 "Invalid" 1805 "Invalid" 1804 "Invalid" 1803 "Invalid" 1802 "Invalid" 1801 "Invalid" ;
VAL_ 547 BCU_CellVlt005_RM 2047 "Invalid" 2046 "Invalid" 2045 "Invalid" 2044 "Invalid" 2043 "Invalid" 2042 "Invalid" 2041 "Invalid" 2040 "Invalid" 2039 "Invalid" 2038 "Invalid" 2037 "Invalid" 2036 "Invalid" 2035 "Invalid" 2034 "Invalid" 2033 "Invalid" 2032 "Invalid" 2031 "Invalid" 2030 "Invalid" 2029 "Invalid" 2028 "Invalid" 2027 "Invalid" 2026 "Invalid" 2025 "Invalid" 2024 "Invalid" 2023 "Invalid" 2022 "Invalid" 2021 "Invalid" 2020 "Invalid" 2019 "Invalid" 2018 "Invalid" 2017 "Invalid" 2016 "Invalid" 2015 "Invalid" 2014 "Invalid" 2013 "Invalid" 2012 "Invalid" 2011 "Invalid" 2010 "Invalid" 2009 "Invalid" 2008 "Invalid" 2007 "Invalid" 2006 "Invalid" 2005 "Invalid" 2004 "Invalid" 2003 "Invalid" 2002 "Invalid" 2001 "Invalid" 2000 "Invalid" 1999 "Invalid" 1998 "Invalid" 1997 "Invalid" 1996 "Invalid" 1995 "Invalid" 1994 "Invalid" 1993 "Invalid" 1992 "Invalid" 1991 "Invalid" 1990 "Invalid" 1989 "Invalid" 1988 "Invalid" 1987 "Invalid" 1986 "Invalid" 1985 "Invalid" 1984 "Invalid" 1983 "Invalid" 1982 "Invalid" 1981 "Invalid" 1980 "Invalid" 1979 "Invalid" 1978 "Invalid" 1977 "Invalid" 1976 "Invalid" 1975 "Invalid" 1974 "Invalid" 1973 "Invalid" 1972 "Invalid" 1971 "Invalid" 1970 "Invalid" 1969 "Invalid" 1968 "Invalid" 1967 "Invalid" 1966 "Invalid" 1965 "Invalid" 1964 "Invalid" 1963 "Invalid" 1962 "Invalid" 1961 "Invalid" 1960 "Invalid" 1959 "Invalid" 1958 "Invalid" 1957 "Invalid" 1956 "Invalid" 1955 "Invalid" 1954 "Invalid" 1953 "Invalid" 1952 "Invalid" 1951 "Invalid" 1950 "Invalid" 1949 "Invalid" 1948 "Invalid" 1947 "Invalid" 1946 "Invalid" 1945 "Invalid" 1944 "Invalid" 1943 "Invalid" 1942 "Invalid" 1941 "Invalid" 1940 "Invalid" 1939 "Invalid" 1938 "Invalid" 1937 "Invalid" 1936 "Invalid" 1935 "Invalid" 1934 "Invalid" 1933 "Invalid" 1932 "Invalid" 1931 "Invalid" 1930 "Invalid" 1929 "Invalid" 1928 "Invalid" 1927 "Invalid" 1926 "Invalid" 1925 "Invalid" 1924 "Invalid" 1923 "Invalid" 1922 "Invalid" 1921 "Invalid" 1920 "Invalid" 1919 "Invalid" 1918 "Invalid" 1917 "Invalid" 1916 "Invalid" 1915 "Invalid" 1914 "Invalid" 1913 "Invalid" 1912 "Invalid" 1911 "Invalid" 1910 "Invalid" 1909 "Invalid" 1908 "Invalid" 1907 "Invalid" 1906 "Invalid" 1905 "Invalid" 1904 "Invalid" 1903 "Invalid" 1902 "Invalid" 1901 "Invalid" 1900 "Invalid" 1899 "Invalid" 1898 "Invalid" 1897 "Invalid" 1896 "Invalid" 1895 "Invalid" 1894 "Invalid" 1893 "Invalid" 1892 "Invalid" 1891 "Invalid" 1890 "Invalid" 1889 "Invalid" 1888 "Invalid" 1887 "Invalid" 1886 "Invalid" 1885 "Invalid" 1884 "Invalid" 1883 "Invalid" 1882 "Invalid" 1881 "Invalid" 1880 "Invalid" 1879 "Invalid" 1878 "Invalid" 1877 "Invalid" 1876 "Invalid" 1875 "Invalid" 1874 "Invalid" 1873 "Invalid" 1872 "Invalid" 1871 "Invalid" 1870 "Invalid" 1869 "Invalid" 1868 "Invalid" 1867 "Invalid" 1866 "Invalid" 1865 "Invalid" 1864 "Invalid" 1863 "Invalid" 1862 "Invalid" 1861 "Invalid" 1860 "Invalid" 1859 "Invalid" 1858 "Invalid" 1857 "Invalid" 1856 "Invalid" 1855 "Invalid" 1854 "Invalid" 1853 "Invalid" 1852 "Invalid" 1851 "Invalid" 1850 "Invalid" 1849 "Invalid" 1848 "Invalid" 1847 "Invalid" 1846 "Invalid" 1845 "Invalid" 1844 "Invalid" 1843 "Invalid" 1842 "Invalid" 1841 "Invalid" 1840 "Invalid" 1839 "Invalid" 1838 "Invalid" 1837 "Invalid" 1836 "Invalid" 1835 "Invalid" 1834 "Invalid" 1833 "Invalid" 1832 "Invalid" 1831 "Invalid" 1830 "Invalid" 1829 "Invalid" 1828 "Invalid" 1827 "Invalid" 1826 "Invalid" 1825 "Invalid" 1824 "Invalid" 1823 "Invalid" 1822 "Invalid" 1821 "Invalid" 1820 "Invalid" 1819 "Invalid" 1818 "Invalid" 1817 "Invalid" 1816 "Invalid" 1815 "Invalid" 1814 "Invalid" 1813 "Invalid" 1812 "Invalid" 1811 "Invalid" 1810 "Invalid" 1809 "Invalid" 1808 "Invalid" 1807 "Invalid" 1806 "Invalid" 1805 "Invalid" 1804 "Invalid" 1803 "Invalid" 1802 "Invalid" 1801 "Invalid" ;
VAL_ 547 BCU_CellTmp001_RM 255 "Invalid" 254 "Invalid" 253 "Invalid" 252 "Invalid" 251 "Invalid" 250 "Invalid" 249 "Invalid" 248 "Invalid" 247 "Invalid" 246 "Invalid" 245 "Invalid" 244 "Invalid" 243 "Invalid" 242 "Invalid" 241 "Invalid" 240 "Invalid" 239 "Invalid" 238 "Invalid" 237 "Invalid" 236 "Invalid" 235 "Invalid" 234 "Invalid" 233 "Invalid" 232 "Invalid" 231 "Invalid" 230 "Invalid" 229 "Invalid" 228 "Invalid" 227 "Invalid" 226 "Invalid" 225 "Invalid" 224 "Invalid" 223 "Invalid" 222 "Invalid" 221 "Invalid" 220 "Invalid" 219 "Invalid" 218 "Invalid" 217 "Invalid" 216 "Invalid" 215 "Invalid" 214 "Invalid" 213 "Invalid" 212 "Invalid" 211 "Invalid" 210 "Invalid" 209 "Invalid" 208 "Invalid" 207 "Invalid" 206 "Invalid" 205 "Invalid" 204 "Invalid" 203 "Invalid" 202 "Invalid" 201 "Invalid" 200 "Invalid" 199 "Invalid" 198 "Invalid" 197 "Invalid" 196 "Invalid" 195 "Invalid" 194 "Invalid" 193 "Invalid" 192 "Invalid" 191 "Invalid" 190 "Invalid" 189 "Invalid" 188 "Invalid" 187 "Invalid" 186 "Invalid" 185 "Invalid" 184 "Invalid" 183 "Invalid" 182 "Invalid" 181 "Invalid" 180 "Invalid" 179 "Invalid" 178 "Invalid" 177 "Invalid" 176 "Invalid" 175 "Invalid" 174 "Invalid" 173 "Invalid" 172 "Invalid" 171 "Invalid" 170 "Invalid" 169 "Invalid" 168 "Invalid" 167 "Invalid" 166 "Invalid" 165 "Invalid" 164 "Invalid" 163 "Invalid" 162 "Invalid" 161 "Invalid" ;
VAL_ 548 BCU_CellVlt006_RM 2047 "Invalid" 2046 "Invalid" 2045 "Invalid" 2044 "Invalid" 2043 "Invalid" 2042 "Invalid" 2041 "Invalid" 2040 "Invalid" 2039 "Invalid" 2038 "Invalid" 2037 "Invalid" 2036 "Invalid" 2035 "Invalid" 2034 "Invalid" 2033 "Invalid" 2032 "Invalid" 2031 "Invalid" 2030 "Invalid" 2029 "Invalid" 2028 "Invalid" 2027 "Invalid" 2026 "Invalid" 2025 "Invalid" 2024 "Invalid" 2023 "Invalid" 2022 "Invalid" 2021 "Invalid" 2020 "Invalid" 2019 "Invalid" 2018 "Invalid" 2017 "Invalid" 2016 "Invalid" 2015 "Invalid" 2014 "Invalid" 2013 "Invalid" 2012 "Invalid" 2011 "Invalid" 2010 "Invalid" 2009 "Invalid" 2008 "Invalid" 2007 "Invalid" 2006 "Invalid" 2005 "Invalid" 2004 "Invalid" 2003 "Invalid" 2002 "Invalid" 2001 "Invalid" 2000 "Invalid" 1999 "Invalid" 1998 "Invalid" 1997 "Invalid" 1996 "Invalid" 1995 "Invalid" 1994 "Invalid" 1993 "Invalid" 1992 "Invalid" 1991 "Invalid" 1990 "Invalid" 1989 "Invalid" 1988 "Invalid" 1987 "Invalid" 1986 "Invalid" 1985 "Invalid" 1984 "Invalid" 1983 "Invalid" 1982 "Invalid" 1981 "Invalid" 1980 "Invalid" 1979 "Invalid" 1978 "Invalid" 1977 "Invalid" 1976 "Invalid" 1975 "Invalid" 1974 "Invalid" 1973 "Invalid" 1972 "Invalid" 1971 "Invalid" 1970 "Invalid" 1969 "Invalid" 1968 "Invalid" 1967 "Invalid" 1966 "Invalid" 1965 "Invalid" 1964 "Invalid" 1963 "Invalid" 1962 "Invalid" 1961 "Invalid" 1960 "Invalid" 1959 "Invalid" 1958 "Invalid" 1957 "Invalid" 1956 "Invalid" 1955 "Invalid" 1954 "Invalid" 1953 "Invalid" 1952 "Invalid" 1951 "Invalid" 1950 "Invalid" 1949 "Invalid" 1948 "Invalid" 1947 "Invalid" 1946 "Invalid" 1945 "Invalid" 1944 "Invalid" 1943 "Invalid" 1942 "Invalid" 1941 "Invalid" 1940 "Invalid" 1939 "Invalid" 1938 "Invalid" 1937 "Invalid" 1936 "Invalid" 1935 "Invalid" 1934 "Invalid" 1933 "Invalid" 1932 "Invalid" 1931 "Invalid" 1930 "Invalid" 1929 "Invalid" 1928 "Invalid" 1927 "Invalid" 1926 "Invalid" 1925 "Invalid" 1924 "Invalid" 1923 "Invalid" 1922 "Invalid" 1921 "Invalid" 1920 "Invalid" 1919 "Invalid" 1918 "Invalid" 1917 "Invalid" 1916 "Invalid" 1915 "Invalid" 1914 "Invalid" 1913 "Invalid" 1912 "Invalid" 1911 "Invalid" 1910 "Invalid" 1909 "Invalid" 1908 "Invalid" 1907 "Invalid" 1906 "Invalid" 1905 "Invalid" 1904 "Invalid" 1903 "Invalid" 1902 "Invalid" 1901 "Invalid" 1900 "Invalid" 1899 "Invalid" 1898 "Invalid" 1897 "Invalid" 1896 "Invalid" 1895 "Invalid" 1894 "Invalid" 1893 "Invalid" 1892 "Invalid" 1891 "Invalid" 1890 "Invalid" 1889 "Invalid" 1888 "Invalid" 1887 "Invalid" 1886 "Invalid" 1885 "Invalid" 1884 "Invalid" 1883 "Invalid" 1882 "Invalid" 1881 "Invalid" 1880 "Invalid" 1879 "Invalid" 1878 "Invalid" 1877 "Invalid" 1876 "Invalid" 1875 "Invalid" 1874 "Invalid" 1873 "Invalid" 1872 "Invalid" 1871 "Invalid" 1870 "Invalid" 1869 "Invalid" 1868 "Invalid" 1867 "Invalid" 1866 "Invalid" 1865 "Invalid" 1864 "Invalid" 1863 "Invalid" 1862 "Invalid" 1861 "Invalid" 1860 "Invalid" 1859 "Invalid" 1858 "Invalid" 1857 "Invalid" 1856 "Invalid" 1855 "Invalid" 1854 "Invalid" 1853 "Invalid" 1852 "Invalid" 1851 "Invalid" 1850 "Invalid" 1849 "Invalid" 1848 "Invalid" 1847 "Invalid" 1846 "Invalid" 1845 "Invalid" 1844 "Invalid" 1843 "Invalid" 1842 "Invalid" 1841 "Invalid" 1840 "Invalid" 1839 "Invalid" 1838 "Invalid" 1837 "Invalid" 1836 "Invalid" 1835 "Invalid" 1834 "Invalid" 1833 "Invalid" 1832 "Invalid" 1831 "Invalid" 1830 "Invalid" 1829 "Invalid" 1828 "Invalid" 1827 "Invalid" 1826 "Invalid" 1825 "Invalid" 1824 "Invalid" 1823 "Invalid" 1822 "Invalid" 1821 "Invalid" 1820 "Invalid" 1819 "Invalid" 1818 "Invalid" 1817 "Invalid" 1816 "Invalid" 1815 "Invalid" 1814 "Invalid" 1813 "Invalid" 1812 "Invalid" 1811 "Invalid" 1810 "Invalid" 1809 "Invalid" 1808 "Invalid" 1807 "Invalid" 1806 "Invalid" 1805 "Invalid" 1804 "Invalid" 1803 "Invalid" 1802 "Invalid" 1801 "Invalid" ;
VAL_ 548 BCU_CellVlt007_RM 2047 "Invalid" 2046 "Invalid" 2045 "Invalid" 2044 "Invalid" 2043 "Invalid" 2042 "Invalid" 2041 "Invalid" 2040 "Invalid" 2039 "Invalid" 2038 "Invalid" 2037 "Invalid" 2036 "Invalid" 2035 "Invalid" 2034 "Invalid" 2033 "Invalid" 2032 "Invalid" 2031 "Invalid" 2030 "Invalid" 2029 "Invalid" 2028 "Invalid" 2027 "Invalid" 2026 "Invalid" 2025 "Invalid" 2024 "Invalid" 2023 "Invalid" 2022 "Invalid" 2021 "Invalid" 2020 "Invalid" 2019 "Invalid" 2018 "Invalid" 2017 "Invalid" 2016 "Invalid" 2015 "Invalid" 2014 "Invalid" 2013 "Invalid" 2012 "Invalid" 2011 "Invalid" 2010 "Invalid" 2009 "Invalid" 2008 "Invalid" 2007 "Invalid" 2006 "Invalid" 2005 "Invalid" 2004 "Invalid" 2003 "Invalid" 2002 "Invalid" 2001 "Invalid" 2000 "Invalid" 1999 "Invalid" 1998 "Invalid" 1997 "Invalid" 1996 "Invalid" 1995 "Invalid" 1994 "Invalid" 1993 "Invalid" 1992 "Invalid" 1991 "Invalid" 1990 "Invalid" 1989 "Invalid" 1988 "Invalid" 1987 "Invalid" 1986 "Invalid" 1985 "Invalid" 1984 "Invalid" 1983 "Invalid" 1982 "Invalid" 1981 "Invalid" 1980 "Invalid" 1979 "Invalid" 1978 "Invalid" 1977 "Invalid" 1976 "Invalid" 1975 "Invalid" 1974 "Invalid" 1973 "Invalid" 1972 "Invalid" 1971 "Invalid" 1970 "Invalid" 1969 "Invalid" 1968 "Invalid" 1967 "Invalid" 1966 "Invalid" 1965 "Invalid" 1964 "Invalid" 1963 "Invalid" 1962 "Invalid" 1961 "Invalid" 1960 "Invalid" 1959 "Invalid" 1958 "Invalid" 1957 "Invalid" 1956 "Invalid" 1955 "Invalid" 1954 "Invalid" 1953 "Invalid" 1952 "Invalid" 1951 "Invalid" 1950 "Invalid" 1949 "Invalid" 1948 "Invalid" 1947 "Invalid" 1946 "Invalid" 1945 "Invalid" 1944 "Invalid" 1943 "Invalid" 1942 "Invalid" 1941 "Invalid" 1940 "Invalid" 1939 "Invalid" 1938 "Invalid" 1937 "Invalid" 1936 "Invalid" 1935 "Invalid" 1934 "Invalid" 1933 "Invalid" 1932 "Invalid" 1931 "Invalid" 1930 "Invalid" 1929 "Invalid" 1928 "Invalid" 1927 "Invalid" 1926 "Invalid" 1925 "Invalid" 1924 "Invalid" 1923 "Invalid" 1922 "Invalid" 1921 "Invalid" 1920 "Invalid" 1919 "Invalid" 1918 "Invalid" 1917 "Invalid" 1916 "Invalid" 1915 "Invalid" 1914 "Invalid" 1913 "Invalid" 1912 "Invalid" 1911 "Invalid" 1910 "Invalid" 1909 "Invalid" 1908 "Invalid" 1907 "Invalid" 1906 "Invalid" 1905 "Invalid" 1904 "Invalid" 1903 "Invalid" 1902 "Invalid" 1901 "Invalid" 1900 "Invalid" 1899 "Invalid" 1898 "Invalid" 1897 "Invalid" 1896 "Invalid" 1895 "Invalid" 1894 "Invalid" 1893 "Invalid" 1892 "Invalid" 1891 "Invalid" 1890 "Invalid" 1889 "Invalid" 1888 "Invalid" 1887 "Invalid" 1886 "Invalid" 1885 "Invalid" 1884 "Invalid" 1883 "Invalid" 1882 "Invalid" 1881 "Invalid" 1880 "Invalid" 1879 "Invalid" 1878 "Invalid" 1877 "Invalid" 1876 "Invalid" 1875 "Invalid" 1874 "Invalid" 1873 "Invalid" 1872 "Invalid" 1871 "Invalid" 1870 "Invalid" 1869 "Invalid" 1868 "Invalid" 1867 "Invalid" 1866 "Invalid" 1865 "Invalid" 1864 "Invalid" 1863 "Invalid" 1862 "Invalid" 1861 "Invalid" 1860 "Invalid" 1859 "Invalid" 1858 "Invalid" 1857 "Invalid" 1856 "Invalid" 1855 "Invalid" 1854 "Invalid" 1853 "Invalid" 1852 "Invalid" 1851 "Invalid" 1850 "Invalid" 1849 "Invalid" 1848 "Invalid" 1847 "Invalid" 1846 "Invalid" 1845 "Invalid" 1844 "Invalid" 1843 "Invalid" 1842 "Invalid" 1841 "Invalid" 1840 "Invalid" 1839 "Invalid" 1838 "Invalid" 1837 "Invalid" 1836 "Invalid" 1835 "Invalid" 1834 "Invalid" 1833 "Invalid" 1832 "Invalid" 1831 "Invalid" 1830 "Invalid" 1829 "Invalid" 1828 "Invalid" 1827 "Invalid" 1826 "Invalid" 1825 "Invalid" 1824 "Invalid" 1823 "Invalid" 1822 "Invalid" 1821 "Invalid" 1820 "Invalid" 1819 "Invalid" 1818 "Invalid" 1817 "Invalid" 1816 "Invalid" 1815 "Invalid" 1814 "Invalid" 1813 "Invalid" 1812 "Invalid" 1811 "Invalid" 1810 "Invalid" 1809 "Invalid" 1808 "Invalid" 1807 "Invalid" 1806 "Invalid" 1805 "Invalid" 1804 "Invalid" 1803 "Invalid" 1802 "Invalid" 1801 "Invalid" ;
VAL_ 548 BCU_CellVlt008_RM 2047 "Invalid" 2046 "Invalid" 2045 "Invalid" 2044 "Invalid" 2043 "Invalid" 2042 "Invalid" 2041 "Invalid" 2040 "Invalid" 2039 "Invalid" 2038 "Invalid" 2037 "Invalid" 2036 "Invalid" 2035 "Invalid" 2034 "Invalid" 2033 "Invalid" 2032 "Invalid" 2031 "Invalid" 2030 "Invalid" 2029 "Invalid" 2028 "Invalid" 2027 "Invalid" 2026 "Invalid" 2025 "Invalid" 2024 "Invalid" 2023 "Invalid" 2022 "Invalid" 2021 "Invalid" 2020 "Invalid" 2019 "Invalid" 2018 "Invalid" 2017 "Invalid" 2016 "Invalid" 2015 "Invalid" 2014 "Invalid" 2013 "Invalid" 2012 "Invalid" 2011 "Invalid" 2010 "Invalid" 2009 "Invalid" 2008 "Invalid" 2007 "Invalid" 2006 "Invalid" 2005 "Invalid" 2004 "Invalid" 2003 "Invalid" 2002 "Invalid" 2001 "Invalid" 2000 "Invalid" 1999 "Invalid" 1998 "Invalid" 1997 "Invalid" 1996 "Invalid" 1995 "Invalid" 1994 "Invalid" 1993 "Invalid" 1992 "Invalid" 1991 "Invalid" 1990 "Invalid" 1989 "Invalid" 1988 "Invalid" 1987 "Invalid" 1986 "Invalid" 1985 "Invalid" 1984 "Invalid" 1983 "Invalid" 1982 "Invalid" 1981 "Invalid" 1980 "Invalid" 1979 "Invalid" 1978 "Invalid" 1977 "Invalid" 1976 "Invalid" 1975 "Invalid" 1974 "Invalid" 1973 "Invalid" 1972 "Invalid" 1971 "Invalid" 1970 "Invalid" 1969 "Invalid" 1968 "Invalid" 1967 "Invalid" 1966 "Invalid" 1965 "Invalid" 1964 "Invalid" 1963 "Invalid" 1962 "Invalid" 1961 "Invalid" 1960 "Invalid" 1959 "Invalid" 1958 "Invalid" 1957 "Invalid" 1956 "Invalid" 1955 "Invalid" 1954 "Invalid" 1953 "Invalid" 1952 "Invalid" 1951 "Invalid" 1950 "Invalid" 1949 "Invalid" 1948 "Invalid" 1947 "Invalid" 1946 "Invalid" 1945 "Invalid" 1944 "Invalid" 1943 "Invalid" 1942 "Invalid" 1941 "Invalid" 1940 "Invalid" 1939 "Invalid" 1938 "Invalid" 1937 "Invalid" 1936 "Invalid" 1935 "Invalid" 1934 "Invalid" 1933 "Invalid" 1932 "Invalid" 1931 "Invalid" 1930 "Invalid" 1929 "Invalid" 1928 "Invalid" 1927 "Invalid" 1926 "Invalid" 1925 "Invalid" 1924 "Invalid" 1923 "Invalid" 1922 "Invalid" 1921 "Invalid" 1920 "Invalid" 1919 "Invalid" 1918 "Invalid" 1917 "Invalid" 1916 "Invalid" 1915 "Invalid" 1914 "Invalid" 1913 "Invalid" 1912 "Invalid" 1911 "Invalid" 1910 "Invalid" 1909 "Invalid" 1908 "Invalid" 1907 "Invalid" 1906 "Invalid" 1905 "Invalid" 1904 "Invalid" 1903 "Invalid" 1902 "Invalid" 1901 "Invalid" 1900 "Invalid" 1899 "Invalid" 1898 "Invalid" 1897 "Invalid" 1896 "Invalid" 1895 "Invalid" 1894 "Invalid" 1893 "Invalid" 1892 "Invalid" 1891 "Invalid" 1890 "Invalid" 1889 "Invalid" 1888 "Invalid" 1887 "Invalid" 1886 "Invalid" 1885 "Invalid" 1884 "Invalid" 1883 "Invalid" 1882 "Invalid" 1881 "Invalid" 1880 "Invalid" 1879 "Invalid" 1878 "Invalid" 1877 "Invalid" 1876 "Invalid" 1875 "Invalid" 1874 "Invalid" 1873 "Invalid" 1872 "Invalid" 1871 "Invalid" 1870 "Invalid" 1869 "Invalid" 1868 "Invalid" 1867 "Invalid" 1866 "Invalid" 1865 "Invalid" 1864 "Invalid" 1863 "Invalid" 1862 "Invalid" 1861 "Invalid" 1860 "Invalid" 1859 "Invalid" 1858 "Invalid" 1857 "Invalid" 1856 "Invalid" 1855 "Invalid" 1854 "Invalid" 1853 "Invalid" 1852 "Invalid" 1851 "Invalid" 1850 "Invalid" 1849 "Invalid" 1848 "Invalid" 1847 "Invalid" 1846 "Invalid" 1845 "Invalid" 1844 "Invalid" 1843 "Invalid" 1842 "Invalid" 1841 "Invalid" 1840 "Invalid" 1839 "Invalid" 1838 "Invalid" 1837 "Invalid" 1836 "Invalid" 1835 "Invalid" 1834 "Invalid" 1833 "Invalid" 1832 "Invalid" 1831 "Invalid" 1830 "Invalid" 1829 "Invalid" 1828 "Invalid" 1827 "Invalid" 1826 "Invalid" 1825 "Invalid" 1824 "Invalid" 1823 "Invalid" 1822 "Invalid" 1821 "Invalid" 1820 "Invalid" 1819 "Invalid" 1818 "Invalid" 1817 "Invalid" 1816 "Invalid" 1815 "Invalid" 1814 "Invalid" 1813 "Invalid" 1812 "Invalid" 1811 "Invalid" 1810 "Invalid" 1809 "Invalid" 1808 "Invalid" 1807 "Invalid" 1806 "Invalid" 1805 "Invalid" 1804 "Invalid" 1803 "Invalid" 1802 "Invalid" 1801 "Invalid" ;
VAL_ 548 BCU_CellVlt009_RM 2047 "Invalid" 2046 "Invalid" 2045 "Invalid" 2044 "Invalid" 2043 "Invalid" 2042 "Invalid" 2041 "Invalid" 2040 "Invalid" 2039 "Invalid" 2038 "Invalid" 2037 "Invalid" 2036 "Invalid" 2035 "Invalid" 2034 "Invalid" 2033 "Invalid" 2032 "Invalid" 2031 "Invalid" 2030 "Invalid" 2029 "Invalid" 2028 "Invalid" 2027 "Invalid" 2026 "Invalid" 2025 "Invalid" 2024 "Invalid" 2023 "Invalid" 2022 "Invalid" 2021 "Invalid" 2020 "Invalid" 2019 "Invalid" 2018 "Invalid" 2017 "Invalid" 2016 "Invalid" 2015 "Invalid" 2014 "Invalid" 2013 "Invalid" 2012 "Invalid" 2011 "Invalid" 2010 "Invalid" 2009 "Invalid" 2008 "Invalid" 2007 "Invalid" 2006 "Invalid" 2005 "Invalid" 2004 "Invalid" 2003 "Invalid" 2002 "Invalid" 2001 "Invalid" 2000 "Invalid" 1999 "Invalid" 1998 "Invalid" 1997 "Invalid" 1996 "Invalid" 1995 "Invalid" 1994 "Invalid" 1993 "Invalid" 1992 "Invalid" 1991 "Invalid" 1990 "Invalid" 1989 "Invalid" 1988 "Invalid" 1987 "Invalid" 1986 "Invalid" 1985 "Invalid" 1984 "Invalid" 1983 "Invalid" 1982 "Invalid" 1981 "Invalid" 1980 "Invalid" 1979 "Invalid" 1978 "Invalid" 1977 "Invalid" 1976 "Invalid" 1975 "Invalid" 1974 "Invalid" 1973 "Invalid" 1972 "Invalid" 1971 "Invalid" 1970 "Invalid" 1969 "Invalid" 1968 "Invalid" 1967 "Invalid" 1966 "Invalid" 1965 "Invalid" 1964 "Invalid" 1963 "Invalid" 1962 "Invalid" 1961 "Invalid" 1960 "Invalid" 1959 "Invalid" 1958 "Invalid" 1957 "Invalid" 1956 "Invalid" 1955 "Invalid" 1954 "Invalid" 1953 "Invalid" 1952 "Invalid" 1951 "Invalid" 1950 "Invalid" 1949 "Invalid" 1948 "Invalid" 1947 "Invalid" 1946 "Invalid" 1945 "Invalid" 1944 "Invalid" 1943 "Invalid" 1942 "Invalid" 1941 "Invalid" 1940 "Invalid" 1939 "Invalid" 1938 "Invalid" 1937 "Invalid" 1936 "Invalid" 1935 "Invalid" 1934 "Invalid" 1933 "Invalid" 1932 "Invalid" 1931 "Invalid" 1930 "Invalid" 1929 "Invalid" 1928 "Invalid" 1927 "Invalid" 1926 "Invalid" 1925 "Invalid" 1924 "Invalid" 1923 "Invalid" 1922 "Invalid" 1921 "Invalid" 1920 "Invalid" 1919 "Invalid" 1918 "Invalid" 1917 "Invalid" 1916 "Invalid" 1915 "Invalid" 1914 "Invalid" 1913 "Invalid" 1912 "Invalid" 1911 "Invalid" 1910 "Invalid" 1909 "Invalid" 1908 "Invalid" 1907 "Invalid" 1906 "Invalid" 1905 "Invalid" 1904 "Invalid" 1903 "Invalid" 1902 "Invalid" 1901 "Invalid" 1900 "Invalid" 1899 "Invalid" 1898 "Invalid" 1897 "Invalid" 1896 "Invalid" 1895 "Invalid" 1894 "Invalid" 1893 "Invalid" 1892 "Invalid" 1891 "Invalid" 1890 "Invalid" 1889 "Invalid" 1888 "Invalid" 1887 "Invalid" 1886 "Invalid" 1885 "Invalid" 1884 "Invalid" 1883 "Invalid" 1882 "Invalid" 1881 "Invalid" 1880 "Invalid" 1879 "Invalid" 1878 "Invalid" 1877 "Invalid" 1876 "Invalid" 1875 "Invalid" 1874 "Invalid" 1873 "Invalid" 1872 "Invalid" 1871 "Invalid" 1870 "Invalid" 1869 "Invalid" 1868 "Invalid" 1867 "Invalid" 1866 "Invalid" 1865 "Invalid" 1864 "Invalid" 1863 "Invalid" 1862 "Invalid" 1861 "Invalid" 1860 "Invalid" 1859 "Invalid" 1858 "Invalid" 1857 "Invalid" 1856 "Invalid" 1855 "Invalid" 1854 "Invalid" 1853 "Invalid" 1852 "Invalid" 1851 "Invalid" 1850 "Invalid" 1849 "Invalid" 1848 "Invalid" 1847 "Invalid" 1846 "Invalid" 1845 "Invalid" 1844 "Invalid" 1843 "Invalid" 1842 "Invalid" 1841 "Invalid" 1840 "Invalid" 1839 "Invalid" 1838 "Invalid" 1837 "Invalid" 1836 "Invalid" 1835 "Invalid" 1834 "Invalid" 1833 "Invalid" 1832 "Invalid" 1831 "Invalid" 1830 "Invalid" 1829 "Invalid" 1828 "Invalid" 1827 "Invalid" 1826 "Invalid" 1825 "Invalid" 1824 "Invalid" 1823 "Invalid" 1822 "Invalid" 1821 "Invalid" 1820 "Invalid" 1819 "Invalid" 1818 "Invalid" 1817 "Invalid" 1816 "Invalid" 1815 "Invalid" 1814 "Invalid" 1813 "Invalid" 1812 "Invalid" 1811 "Invalid" 1810 "Invalid" 1809 "Invalid" 1808 "Invalid" 1807 "Invalid" 1806 "Invalid" 1805 "Invalid" 1804 "Invalid" 1803 "Invalid" 1802 "Invalid" 1801 "Invalid" ;
VAL_ 548 BCU_CellVlt010_RM 2047 "Invalid" 2046 "Invalid" 2045 "Invalid" 2044 "Invalid" 2043 "Invalid" 2042 "Invalid" 2041 "Invalid" 2040 "Invalid" 2039 "Invalid" 2038 "Invalid" 2037 "Invalid" 2036 "Invalid" 2035 "Invalid" 2034 "Invalid" 2033 "Invalid" 2032 "Invalid" 2031 "Invalid" 2030 "Invalid" 2029 "Invalid" 2028 "Invalid" 2027 "Invalid" 2026 "Invalid" 2025 "Invalid" 2024 "Invalid" 2023 "Invalid" 2022 "Invalid" 2021 "Invalid" 2020 "Invalid" 2019 "Invalid" 2018 "Invalid" 2017 "Invalid" 2016 "Invalid" 2015 "Invalid" 2014 "Invalid" 2013 "Invalid" 2012 "Invalid" 2011 "Invalid" 2010 "Invalid" 2009 "Invalid" 2008 "Invalid" 2007 "Invalid" 2006 "Invalid" 2005 "Invalid" 2004 "Invalid" 2003 "Invalid" 2002 "Invalid" 2001 "Invalid" 2000 "Invalid" 1999 "Invalid" 1998 "Invalid" 1997 "Invalid" 1996 "Invalid" 1995 "Invalid" 1994 "Invalid" 1993 "Invalid" 1992 "Invalid" 1991 "Invalid" 1990 "Invalid" 1989 "Invalid" 1988 "Invalid" 1987 "Invalid" 1986 "Invalid" 1985 "Invalid" 1984 "Invalid" 1983 "Invalid" 1982 "Invalid" 1981 "Invalid" 1980 "Invalid" 1979 "Invalid" 1978 "Invalid" 1977 "Invalid" 1976 "Invalid" 1975 "Invalid" 1974 "Invalid" 1973 "Invalid" 1972 "Invalid" 1971 "Invalid" 1970 "Invalid" 1969 "Invalid" 1968 "Invalid" 1967 "Invalid" 1966 "Invalid" 1965 "Invalid" 1964 "Invalid" 1963 "Invalid" 1962 "Invalid" 1961 "Invalid" 1960 "Invalid" 1959 "Invalid" 1958 "Invalid" 1957 "Invalid" 1956 "Invalid" 1955 "Invalid" 1954 "Invalid" 1953 "Invalid" 1952 "Invalid" 1951 "Invalid" 1950 "Invalid" 1949 "Invalid" 1948 "Invalid" 1947 "Invalid" 1946 "Invalid" 1945 "Invalid" 1944 "Invalid" 1943 "Invalid" 1942 "Invalid" 1941 "Invalid" 1940 "Invalid" 1939 "Invalid" 1938 "Invalid" 1937 "Invalid" 1936 "Invalid" 1935 "Invalid" 1934 "Invalid" 1933 "Invalid" 1932 "Invalid" 1931 "Invalid" 1930 "Invalid" 1929 "Invalid" 1928 "Invalid" 1927 "Invalid" 1926 "Invalid" 1925 "Invalid" 1924 "Invalid" 1923 "Invalid" 1922 "Invalid" 1921 "Invalid" 1920 "Invalid" 1919 "Invalid" 1918 "Invalid" 1917 "Invalid" 1916 "Invalid" 1915 "Invalid" 1914 "Invalid" 1913 "Invalid" 1912 "Invalid" 1911 "Invalid" 1910 "Invalid" 1909 "Invalid" 1908 "Invalid" 1907 "Invalid" 1906 "Invalid" 1905 "Invalid" 1904 "Invalid" 1903 "Invalid" 1902 "Invalid" 1901 "Invalid" 1900 "Invalid" 1899 "Invalid" 1898 "Invalid" 1897 "Invalid" 1896 "Invalid" 1895 "Invalid" 1894 "Invalid" 1893 "Invalid" 1892 "Invalid" 1891 "Invalid" 1890 "Invalid" 1889 "Invalid" 1888 "Invalid" 1887 "Invalid" 1886 "Invalid" 1885 "Invalid" 1884 "Invalid" 1883 "Invalid" 1882 "Invalid" 1881 "Invalid" 1880 "Invalid" 1879 "Invalid" 1878 "Invalid" 1877 "Invalid" 1876 "Invalid" 1875 "Invalid" 1874 "Invalid" 1873 "Invalid" 1872 "Invalid" 1871 "Invalid" 1870 "Invalid" 1869 "Invalid" 1868 "Invalid" 1867 "Invalid" 1866 "Invalid" 1865 "Invalid" 1864 "Invalid" 1863 "Invalid" 1862 "Invalid" 1861 "Invalid" 1860 "Invalid" 1859 "Invalid" 1858 "Invalid" 1857 "Invalid" 1856 "Invalid" 1855 "Invalid" 1854 "Invalid" 1853 "Invalid" 1852 "Invalid" 1851 "Invalid" 1850 "Invalid" 1849 "Invalid" 1848 "Invalid" 1847 "Invalid" 1846 "Invalid" 1845 "Invalid" 1844 "Invalid" 1843 "Invalid" 1842 "Invalid" 1841 "Invalid" 1840 "Invalid" 1839 "Invalid" 1838 "Invalid" 1837 "Invalid" 1836 "Invalid" 1835 "Invalid" 1834 "Invalid" 1833 "Invalid" 1832 "Invalid" 1831 "Invalid" 1830 "Invalid" 1829 "Invalid" 1828 "Invalid" 1827 "Invalid" 1826 "Invalid" 1825 "Invalid" 1824 "Invalid" 1823 "Invalid" 1822 "Invalid" 1821 "Invalid" 1820 "Invalid" 1819 "Invalid" 1818 "Invalid" 1817 "Invalid" 1816 "Invalid" 1815 "Invalid" 1814 "Invalid" 1813 "Invalid" 1812 "Invalid" 1811 "Invalid" 1810 "Invalid" 1809 "Invalid" 1808 "Invalid" 1807 "Invalid" 1806 "Invalid" 1805 "Invalid" 1804 "Invalid" 1803 "Invalid" 1802 "Invalid" 1801 "Invalid" ;
VAL_ 548 BCU_CellTmp002_RM 255 "Invalid" 254 "Invalid" 253 "Invalid" 252 "Invalid" 251 "Invalid" 250 "Invalid" 249 "Invalid" 248 "Invalid" 247 "Invalid" 246 "Invalid" 245 "Invalid" 244 "Invalid" 243 "Invalid" 242 "Invalid" 241 "Invalid" 240 "Invalid" 239 "Invalid" 238 "Invalid" 237 "Invalid" 236 "Invalid" 235 "Invalid" 234 "Invalid" 233 "Invalid" 232 "Invalid" 231 "Invalid" 230 "Invalid" 229 "Invalid" 228 "Invalid" 227 "Invalid" 226 "Invalid" 225 "Invalid" 224 "Invalid" 223 "Invalid" 222 "Invalid" 221 "Invalid" 220 "Invalid" 219 "Invalid" 218 "Invalid" 217 "Invalid" 216 "Invalid" 215 "Invalid" 214 "Invalid" 213 "Invalid" 212 "Invalid" 211 "Invalid" 210 "Invalid" 209 "Invalid" 208 "Invalid" 207 "Invalid" 206 "Invalid" 205 "Invalid" 204 "Invalid" 203 "Invalid" 202 "Invalid" 201 "Invalid" 200 "Invalid" 199 "Invalid" 198 "Invalid" 197 "Invalid" 196 "Invalid" 195 "Invalid" 194 "Invalid" 193 "Invalid" 192 "Invalid" 191 "Invalid" 190 "Invalid" 189 "Invalid" 188 "Invalid" 187 "Invalid" 186 "Invalid" 185 "Invalid" 184 "Invalid" 183 "Invalid" 182 "Invalid" 181 "Invalid" 180 "Invalid" 179 "Invalid" 178 "Invalid" 177 "Invalid" 176 "Invalid" 175 "Invalid" 174 "Invalid" 173 "Invalid" 172 "Invalid" 171 "Invalid" 170 "Invalid" 169 "Invalid" 168 "Invalid" 167 "Invalid" 166 "Invalid" 165 "Invalid" 164 "Invalid" 163 "Invalid" 162 "Invalid" 161 "Invalid" ;
VAL_ 549 BCU_CellVlt011_RM 2047 "Invalid" 2046 "Invalid" 2045 "Invalid" 2044 "Invalid" 2043 "Invalid" 2042 "Invalid" 2041 "Invalid" 2040 "Invalid" 2039 "Invalid" 2038 "Invalid" 2037 "Invalid" 2036 "Invalid" 2035 "Invalid" 2034 "Invalid" 2033 "Invalid" 2032 "Invalid" 2031 "Invalid" 2030 "Invalid" 2029 "Invalid" 2028 "Invalid" 2027 "Invalid" 2026 "Invalid" 2025 "Invalid" 2024 "Invalid" 2023 "Invalid" 2022 "Invalid" 2021 "Invalid" 2020 "Invalid" 2019 "Invalid" 2018 "Invalid" 2017 "Invalid" 2016 "Invalid" 2015 "Invalid" 2014 "Invalid" 2013 "Invalid" 2012 "Invalid" 2011 "Invalid" 2010 "Invalid" 2009 "Invalid" 2008 "Invalid" 2007 "Invalid" 2006 "Invalid" 2005 "Invalid" 2004 "Invalid" 2003 "Invalid" 2002 "Invalid" 2001 "Invalid" 2000 "Invalid" 1999 "Invalid" 1998 "Invalid" 1997 "Invalid" 1996 "Invalid" 1995 "Invalid" 1994 "Invalid" 1993 "Invalid" 1992 "Invalid" 1991 "Invalid" 1990 "Invalid" 1989 "Invalid" 1988 "Invalid" 1987 "Invalid" 1986 "Invalid" 1985 "Invalid" 1984 "Invalid" 1983 "Invalid" 1982 "Invalid" 1981 "Invalid" 1980 "Invalid" 1979 "Invalid" 1978 "Invalid" 1977 "Invalid" 1976 "Invalid" 1975 "Invalid" 1974 "Invalid" 1973 "Invalid" 1972 "Invalid" 1971 "Invalid" 1970 "Invalid" 1969 "Invalid" 1968 "Invalid" 1967 "Invalid" 1966 "Invalid" 1965 "Invalid" 1964 "Invalid" 1963 "Invalid" 1962 "Invalid" 1961 "Invalid" 1960 "Invalid" 1959 "Invalid" 1958 "Invalid" 1957 "Invalid" 1956 "Invalid" 1955 "Invalid" 1954 "Invalid" 1953 "Invalid" 1952 "Invalid" 1951 "Invalid" 1950 "Invalid" 1949 "Invalid" 1948 "Invalid" 1947 "Invalid" 1946 "Invalid" 1945 "Invalid" 1944 "Invalid" 1943 "Invalid" 1942 "Invalid" 1941 "Invalid" 1940 "Invalid" 1939 "Invalid" 1938 "Invalid" 1937 "Invalid" 1936 "Invalid" 1935 "Invalid" 1934 "Invalid" 1933 "Invalid" 1932 "Invalid" 1931 "Invalid" 1930 "Invalid" 1929 "Invalid" 1928 "Invalid" 1927 "Invalid" 1926 "Invalid" 1925 "Invalid" 1924 "Invalid" 1923 "Invalid" 1922 "Invalid" 1921 "Invalid" 1920 "Invalid" 1919 "Invalid" 1918 "Invalid" 1917 "Invalid" 1916 "Invalid" 1915 "Invalid" 1914 "Invalid" 1913 "Invalid" 1912 "Invalid" 1911 "Invalid" 1910 "Invalid" 1909 "Invalid" 1908 "Invalid" 1907 "Invalid" 1906 "Invalid" 1905 "Invalid" 1904 "Invalid" 1903 "Invalid" 1902 "Invalid" 1901 "Invalid" 1900 "Invalid" 1899 "Invalid" 1898 "Invalid" 1897 "Invalid" 1896 "Invalid" 1895 "Invalid" 1894 "Invalid" 1893 "Invalid" 1892 "Invalid" 1891 "Invalid" 1890 "Invalid" 1889 "Invalid" 1888 "Invalid" 1887 "Invalid" 1886 "Invalid" 1885 "Invalid" 1884 "Invalid" 1883 "Invalid" 1882 "Invalid" 1881 "Invalid" 1880 "Invalid" 1879 "Invalid" 1878 "Invalid" 1877 "Invalid" 1876 "Invalid" 1875 "Invalid" 1874 "Invalid" 1873 "Invalid" 1872 "Invalid" 1871 "Invalid" 1870 "Invalid" 1869 "Invalid" 1868 "Invalid" 1867 "Invalid" 1866 "Invalid" 1865 "Invalid" 1864 "Invalid" 1863 "Invalid" 1862 "Invalid" 1861 "Invalid" 1860 "Invalid" 1859 "Invalid" 1858 "Invalid" 1857 "Invalid" 1856 "Invalid" 1855 "Invalid" 1854 "Invalid" 1853 "Invalid" 1852 "Invalid" 1851 "Invalid" 1850 "Invalid" 1849 "Invalid" 1848 "Invalid" 1847 "Invalid" 1846 "Invalid" 1845 "Invalid" 1844 "Invalid" 1843 "Invalid" 1842 "Invalid" 1841 "Invalid" 1840 "Invalid" 1839 "Invalid" 1838 "Invalid" 1837 "Invalid" 1836 "Invalid" 1835 "Invalid" 1834 "Invalid" 1833 "Invalid" 1832 "Invalid" 1831 "Invalid" 1830 "Invalid" 1829 "Invalid" 1828 "Invalid" 1827 "Invalid" 1826 "Invalid" 1825 "Invalid" 1824 "Invalid" 1823 "Invalid" 1822 "Invalid" 1821 "Invalid" 1820 "Invalid" 1819 "Invalid" 1818 "Invalid" 1817 "Invalid" 1816 "Invalid" 1815 "Invalid" 1814 "Invalid" 1813 "Invalid" 1812 "Invalid" 1811 "Invalid" 1810 "Invalid" 1809 "Invalid" 1808 "Invalid" 1807 "Invalid" 1806 "Invalid" 1805 "Invalid" 1804 "Invalid" 1803 "Invalid" 1802 "Invalid" 1801 "Invalid" ;
VAL_ 549 BCU_CellVlt012_RM 2047 "Invalid" 2046 "Invalid" 2045 "Invalid" 2044 "Invalid" 2043 "Invalid" 2042 "Invalid" 2041 "Invalid" 2040 "Invalid" 2039 "Invalid" 2038 "Invalid" 2037 "Invalid" 2036 "Invalid" 2035 "Invalid" 2034 "Invalid" 2033 "Invalid" 2032 "Invalid" 2031 "Invalid" 2030 "Invalid" 2029 "Invalid" 2028 "Invalid" 2027 "Invalid" 2026 "Invalid" 2025 "Invalid" 2024 "Invalid" 2023 "Invalid" 2022 "Invalid" 2021 "Invalid" 2020 "Invalid" 2019 "Invalid" 2018 "Invalid" 2017 "Invalid" 2016 "Invalid" 2015 "Invalid" 2014 "Invalid" 2013 "Invalid" 2012 "Invalid" 2011 "Invalid" 2010 "Invalid" 2009 "Invalid" 2008 "Invalid" 2007 "Invalid" 2006 "Invalid" 2005 "Invalid" 2004 "Invalid" 2003 "Invalid" 2002 "Invalid" 2001 "Invalid" 2000 "Invalid" 1999 "Invalid" 1998 "Invalid" 1997 "Invalid" 1996 "Invalid" 1995 "Invalid" 1994 "Invalid" 1993 "Invalid" 1992 "Invalid" 1991 "Invalid" 1990 "Invalid" 1989 "Invalid" 1988 "Invalid" 1987 "Invalid" 1986 "Invalid" 1985 "Invalid" 1984 "Invalid" 1983 "Invalid" 1982 "Invalid" 1981 "Invalid" 1980 "Invalid" 1979 "Invalid" 1978 "Invalid" 1977 "Invalid" 1976 "Invalid" 1975 "Invalid" 1974 "Invalid" 1973 "Invalid" 1972 "Invalid" 1971 "Invalid" 1970 "Invalid" 1969 "Invalid" 1968 "Invalid" 1967 "Invalid" 1966 "Invalid" 1965 "Invalid" 1964 "Invalid" 1963 "Invalid" 1962 "Invalid" 1961 "Invalid" 1960 "Invalid" 1959 "Invalid" 1958 "Invalid" 1957 "Invalid" 1956 "Invalid" 1955 "Invalid" 1954 "Invalid" 1953 "Invalid" 1952 "Invalid" 1951 "Invalid" 1950 "Invalid" 1949 "Invalid" 1948 "Invalid" 1947 "Invalid" 1946 "Invalid" 1945 "Invalid" 1944 "Invalid" 1943 "Invalid" 1942 "Invalid" 1941 "Invalid" 1940 "Invalid" 1939 "Invalid" 1938 "Invalid" 1937 "Invalid" 1936 "Invalid" 1935 "Invalid" 1934 "Invalid" 1933 "Invalid" 1932 "Invalid" 1931 "Invalid" 1930 "Invalid" 1929 "Invalid" 1928 "Invalid" 1927 "Invalid" 1926 "Invalid" 1925 "Invalid" 1924 "Invalid" 1923 "Invalid" 1922 "Invalid" 1921 "Invalid" 1920 "Invalid" 1919 "Invalid" 1918 "Invalid" 1917 "Invalid" 1916 "Invalid" 1915 "Invalid" 1914 "Invalid" 1913 "Invalid" 1912 "Invalid" 1911 "Invalid" 1910 "Invalid" 1909 "Invalid" 1908 "Invalid" 1907 "Invalid" 1906 "Invalid" 1905 "Invalid" 1904 "Invalid" 1903 "Invalid" 1902 "Invalid" 1901 "Invalid" 1900 "Invalid" 1899 "Invalid" 1898 "Invalid" 1897 "Invalid" 1896 "Invalid" 1895 "Invalid" 1894 "Invalid" 1893 "Invalid" 1892 "Invalid" 1891 "Invalid" 1890 "Invalid" 1889 "Invalid" 1888 "Invalid" 1887 "Invalid" 1886 "Invalid" 1885 "Invalid" 1884 "Invalid" 1883 "Invalid" 1882 "Invalid" 1881 "Invalid" 1880 "Invalid" 1879 "Invalid" 1878 "Invalid" 1877 "Invalid" 1876 "Invalid" 1875 "Invalid" 1874 "Invalid" 1873 "Invalid" 1872 "Invalid" 1871 "Invalid" 1870 "Invalid" 1869 "Invalid" 1868 "Invalid" 1867 "Invalid" 1866 "Invalid" 1865 "Invalid" 1864 "Invalid" 1863 "Invalid" 1862 "Invalid" 1861 "Invalid" 1860 "Invalid" 1859 "Invalid" 1858 "Invalid" 1857 "Invalid" 1856 "Invalid" 1855 "Invalid" 1854 "Invalid" 1853 "Invalid" 1852 "Invalid" 1851 "Invalid" 1850 "Invalid" 1849 "Invalid" 1848 "Invalid" 1847 "Invalid" 1846 "Invalid" 1845 "Invalid" 1844 "Invalid" 1843 "Invalid" 1842 "Invalid" 1841 "Invalid" 1840 "Invalid" 1839 "Invalid" 1838 "Invalid" 1837 "Invalid" 1836 "Invalid" 1835 "Invalid" 1834 "Invalid" 1833 "Invalid" 1832 "Invalid" 1831 "Invalid" 1830 "Invalid" 1829 "Invalid" 1828 "Invalid" 1827 "Invalid" 1826 "Invalid" 1825 "Invalid" 1824 "Invalid" 1823 "Invalid" 1822 "Invalid" 1821 "Invalid" 1820 "Invalid" 1819 "Invalid" 1818 "Invalid" 1817 "Invalid" 1816 "Invalid" 1815 "Invalid" 1814 "Invalid" 1813 "Invalid" 1812 "Invalid" 1811 "Invalid" 1810 "Invalid" 1809 "Invalid" 1808 "Invalid" 1807 "Invalid" 1806 "Invalid" 1805 "Invalid" 1804 "Invalid" 1803 "Invalid" 1802 "Invalid" 1801 "Invalid" ;
VAL_ 549 BCU_CellVlt013_RM 2047 "Invalid" 2046 "Invalid" 2045 "Invalid" 2044 "Invalid" 2043 "Invalid" 2042 "Invalid" 2041 "Invalid" 2040 "Invalid" 2039 "Invalid" 2038 "Invalid" 2037 "Invalid" 2036 "Invalid" 2035 "Invalid" 2034 "Invalid" 2033 "Invalid" 2032 "Invalid" 2031 "Invalid" 2030 "Invalid" 2029 "Invalid" 2028 "Invalid" 2027 "Invalid" 2026 "Invalid" 2025 "Invalid" 2024 "Invalid" 2023 "Invalid" 2022 "Invalid" 2021 "Invalid" 2020 "Invalid" 2019 "Invalid" 2018 "Invalid" 2017 "Invalid" 2016 "Invalid" 2015 "Invalid" 2014 "Invalid" 2013 "Invalid" 2012 "Invalid" 2011 "Invalid" 2010 "Invalid" 2009 "Invalid" 2008 "Invalid" 2007 "Invalid" 2006 "Invalid" 2005 "Invalid" 2004 "Invalid" 2003 "Invalid" 2002 "Invalid" 2001 "Invalid" 2000 "Invalid" 1999 "Invalid" 1998 "Invalid" 1997 "Invalid" 1996 "Invalid" 1995 "Invalid" 1994 "Invalid" 1993 "Invalid" 1992 "Invalid" 1991 "Invalid" 1990 "Invalid" 1989 "Invalid" 1988 "Invalid" 1987 "Invalid" 1986 "Invalid" 1985 "Invalid" 1984 "Invalid" 1983 "Invalid" 1982 "Invalid" 1981 "Invalid" 1980 "Invalid" 1979 "Invalid" 1978 "Invalid" 1977 "Invalid" 1976 "Invalid" 1975 "Invalid" 1974 "Invalid" 1973 "Invalid" 1972 "Invalid" 1971 "Invalid" 1970 "Invalid" 1969 "Invalid" 1968 "Invalid" 1967 "Invalid" 1966 "Invalid" 1965 "Invalid" 1964 "Invalid" 1963 "Invalid" 1962 "Invalid" 1961 "Invalid" 1960 "Invalid" 1959 "Invalid" 1958 "Invalid" 1957 "Invalid" 1956 "Invalid" 1955 "Invalid" 1954 "Invalid" 1953 "Invalid" 1952 "Invalid" 1951 "Invalid" 1950 "Invalid" 1949 "Invalid" 1948 "Invalid" 1947 "Invalid" 1946 "Invalid" 1945 "Invalid" 1944 "Invalid" 1943 "Invalid" 1942 "Invalid" 1941 "Invalid" 1940 "Invalid" 1939 "Invalid" 1938 "Invalid" 1937 "Invalid" 1936 "Invalid" 1935 "Invalid" 1934 "Invalid" 1933 "Invalid" 1932 "Invalid" 1931 "Invalid" 1930 "Invalid" 1929 "Invalid" 1928 "Invalid" 1927 "Invalid" 1926 "Invalid" 1925 "Invalid" 1924 "Invalid" 1923 "Invalid" 1922 "Invalid" 1921 "Invalid" 1920 "Invalid" 1919 "Invalid" 1918 "Invalid" 1917 "Invalid" 1916 "Invalid" 1915 "Invalid" 1914 "Invalid" 1913 "Invalid" 1912 "Invalid" 1911 "Invalid" 1910 "Invalid" 1909 "Invalid" 1908 "Invalid" 1907 "Invalid" 1906 "Invalid" 1905 "Invalid" 1904 "Invalid" 1903 "Invalid" 1902 "Invalid" 1901 "Invalid" 1900 "Invalid" 1899 "Invalid" 1898 "Invalid" 1897 "Invalid" 1896 "Invalid" 1895 "Invalid" 1894 "Invalid" 1893 "Invalid" 1892 "Invalid" 1891 "Invalid" 1890 "Invalid" 1889 "Invalid" 1888 "Invalid" 1887 "Invalid" 1886 "Invalid" 1885 "Invalid" 1884 "Invalid" 1883 "Invalid" 1882 "Invalid" 1881 "Invalid" 1880 "Invalid" 1879 "Invalid" 1878 "Invalid" 1877 "Invalid" 1876 "Invalid" 1875 "Invalid" 1874 "Invalid" 1873 "Invalid" 1872 "Invalid" 1871 "Invalid" 1870 "Invalid" 1869 "Invalid" 1868 "Invalid" 1867 "Invalid" 1866 "Invalid" 1865 "Invalid" 1864 "Invalid" 1863 "Invalid" 1862 "Invalid" 1861 "Invalid" 1860 "Invalid" 1859 "Invalid" 1858 "Invalid" 1857 "Invalid" 1856 "Invalid" 1855 "Invalid" 1854 "Invalid" 1853 "Invalid" 1852 "Invalid" 1851 "Invalid" 1850 "Invalid" 1849 "Invalid" 1848 "Invalid" 1847 "Invalid" 1846 "Invalid" 1845 "Invalid" 1844 "Invalid" 1843 "Invalid" 1842 "Invalid" 1841 "Invalid" 1840 "Invalid" 1839 "Invalid" 1838 "Invalid" 1837 "Invalid" 1836 "Invalid" 1835 "Invalid" 1834 "Invalid" 1833 "Invalid" 1832 "Invalid" 1831 "Invalid" 1830 "Invalid" 1829 "Invalid" 1828 "Invalid" 1827 "Invalid" 1826 "Invalid" 1825 "Invalid" 1824 "Invalid" 1823 "Invalid" 1822 "Invalid" 1821 "Invalid" 1820 "Invalid" 1819 "Invalid" 1818 "Invalid" 1817 "Invalid" 1816 "Invalid" 1815 "Invalid" 1814 "Invalid" 1813 "Invalid" 1812 "Invalid" 1811 "Invalid" 1810 "Invalid" 1809 "Invalid" 1808 "Invalid" 1807 "Invalid" 1806 "Invalid" 1805 "Invalid" 1804 "Invalid" 1803 "Invalid" 1802 "Invalid" 1801 "Invalid" ;
VAL_ 549 BCU_CellVlt014_RM 2047 "Invalid" 2046 "Invalid" 2045 "Invalid" 2044 "Invalid" 2043 "Invalid" 2042 "Invalid" 2041 "Invalid" 2040 "Invalid" 2039 "Invalid" 2038 "Invalid" 2037 "Invalid" 2036 "Invalid" 2035 "Invalid" 2034 "Invalid" 2033 "Invalid" 2032 "Invalid" 2031 "Invalid" 2030 "Invalid" 2029 "Invalid" 2028 "Invalid" 2027 "Invalid" 2026 "Invalid" 2025 "Invalid" 2024 "Invalid" 2023 "Invalid" 2022 "Invalid" 2021 "Invalid" 2020 "Invalid" 2019 "Invalid" 2018 "Invalid" 2017 "Invalid" 2016 "Invalid" 2015 "Invalid" 2014 "Invalid" 2013 "Invalid" 2012 "Invalid" 2011 "Invalid" 2010 "Invalid" 2009 "Invalid" 2008 "Invalid" 2007 "Invalid" 2006 "Invalid" 2005 "Invalid" 2004 "Invalid" 2003 "Invalid" 2002 "Invalid" 2001 "Invalid" 2000 "Invalid" 1999 "Invalid" 1998 "Invalid" 1997 "Invalid" 1996 "Invalid" 1995 "Invalid" 1994 "Invalid" 1993 "Invalid" 1992 "Invalid" 1991 "Invalid" 1990 "Invalid" 1989 "Invalid" 1988 "Invalid" 1987 "Invalid" 1986 "Invalid" 1985 "Invalid" 1984 "Invalid" 1983 "Invalid" 1982 "Invalid" 1981 "Invalid" 1980 "Invalid" 1979 "Invalid" 1978 "Invalid" 1977 "Invalid" 1976 "Invalid" 1975 "Invalid" 1974 "Invalid" 1973 "Invalid" 1972 "Invalid" 1971 "Invalid" 1970 "Invalid" 1969 "Invalid" 1968 "Invalid" 1967 "Invalid" 1966 "Invalid" 1965 "Invalid" 1964 "Invalid" 1963 "Invalid" 1962 "Invalid" 1961 "Invalid" 1960 "Invalid" 1959 "Invalid" 1958 "Invalid" 1957 "Invalid" 1956 "Invalid" 1955 "Invalid" 1954 "Invalid" 1953 "Invalid" 1952 "Invalid" 1951 "Invalid" 1950 "Invalid" 1949 "Invalid" 1948 "Invalid" 1947 "Invalid" 1946 "Invalid" 1945 "Invalid" 1944 "Invalid" 1943 "Invalid" 1942 "Invalid" 1941 "Invalid" 1940 "Invalid" 1939 "Invalid" 1938 "Invalid" 1937 "Invalid" 1936 "Invalid" 1935 "Invalid" 1934 "Invalid" 1933 "Invalid" 1932 "Invalid" 1931 "Invalid" 1930 "Invalid" 1929 "Invalid" 1928 "Invalid" 1927 "Invalid" 1926 "Invalid" 1925 "Invalid" 1924 "Invalid" 1923 "Invalid" 1922 "Invalid" 1921 "Invalid" 1920 "Invalid" 1919 "Invalid" 1918 "Invalid" 1917 "Invalid" 1916 "Invalid" 1915 "Invalid" 1914 "Invalid" 1913 "Invalid" 1912 "Invalid" 1911 "Invalid" 1910 "Invalid" 1909 "Invalid" 1908 "Invalid" 1907 "Invalid" 1906 "Invalid" 1905 "Invalid" 1904 "Invalid" 1903 "Invalid" 1902 "Invalid" 1901 "Invalid" 1900 "Invalid" 1899 "Invalid" 1898 "Invalid" 1897 "Invalid" 1896 "Invalid" 1895 "Invalid" 1894 "Invalid" 1893 "Invalid" 1892 "Invalid" 1891 "Invalid" 1890 "Invalid" 1889 "Invalid" 1888 "Invalid" 1887 "Invalid" 1886 "Invalid" 1885 "Invalid" 1884 "Invalid" 1883 "Invalid" 1882 "Invalid" 1881 "Invalid" 1880 "Invalid" 1879 "Invalid" 1878 "Invalid" 1877 "Invalid" 1876 "Invalid" 1875 "Invalid" 1874 "Invalid" 1873 "Invalid" 1872 "Invalid" 1871 "Invalid" 1870 "Invalid" 1869 "Invalid" 1868 "Invalid" 1867 "Invalid" 1866 "Invalid" 1865 "Invalid" 1864 "Invalid" 1863 "Invalid" 1862 "Invalid" 1861 "Invalid" 1860 "Invalid" 1859 "Invalid" 1858 "Invalid" 1857 "Invalid" 1856 "Invalid" 1855 "Invalid" 1854 "Invalid" 1853 "Invalid" 1852 "Invalid" 1851 "Invalid" 1850 "Invalid" 1849 "Invalid" 1848 "Invalid" 1847 "Invalid" 1846 "Invalid" 1845 "Invalid" 1844 "Invalid" 1843 "Invalid" 1842 "Invalid" 1841 "Invalid" 1840 "Invalid" 1839 "Invalid" 1838 "Invalid" 1837 "Invalid" 1836 "Invalid" 1835 "Invalid" 1834 "Invalid" 1833 "Invalid" 1832 "Invalid" 1831 "Invalid" 1830 "Invalid" 1829 "Invalid" 1828 "Invalid" 1827 "Invalid" 1826 "Invalid" 1825 "Invalid" 1824 "Invalid" 1823 "Invalid" 1822 "Invalid" 1821 "Invalid" 1820 "Invalid" 1819 "Invalid" 1818 "Invalid" 1817 "Invalid" 1816 "Invalid" 1815 "Invalid" 1814 "Invalid" 1813 "Invalid" 1812 "Invalid" 1811 "Invalid" 1810 "Invalid" 1809 "Invalid" 1808 "Invalid" 1807 "Invalid" 1806 "Invalid" 1805 "Invalid" 1804 "Invalid" 1803 "Invalid" 1802 "Invalid" 1801 "Invalid" ;
VAL_ 549 BCU_CellVlt015_RM 2047 "Invalid" 2046 "Invalid" 2045 "Invalid" 2044 "Invalid" 2043 "Invalid" 2042 "Invalid" 2041 "Invalid" 2040 "Invalid" 2039 "Invalid" 2038 "Invalid" 2037 "Invalid" 2036 "Invalid" 2035 "Invalid" 2034 "Invalid" 2033 "Invalid" 2032 "Invalid" 2031 "Invalid" 2030 "Invalid" 2029 "Invalid" 2028 "Invalid" 2027 "Invalid" 2026 "Invalid" 2025 "Invalid" 2024 "Invalid" 2023 "Invalid" 2022 "Invalid" 2021 "Invalid" 2020 "Invalid" 2019 "Invalid" 2018 "Invalid" 2017 "Invalid" 2016 "Invalid" 2015 "Invalid" 2014 "Invalid" 2013 "Invalid" 2012 "Invalid" 2011 "Invalid" 2010 "Invalid" 2009 "Invalid" 2008 "Invalid" 2007 "Invalid" 2006 "Invalid" 2005 "Invalid" 2004 "Invalid" 2003 "Invalid" 2002 "Invalid" 2001 "Invalid" 2000 "Invalid" 1999 "Invalid" 1998 "Invalid" 1997 "Invalid" 1996 "Invalid" 1995 "Invalid" 1994 "Invalid" 1993 "Invalid" 1992 "Invalid" 1991 "Invalid" 1990 "Invalid" 1989 "Invalid" 1988 "Invalid" 1987 "Invalid" 1986 "Invalid" 1985 "Invalid" 1984 "Invalid" 1983 "Invalid" 1982 "Invalid" 1981 "Invalid" 1980 "Invalid" 1979 "Invalid" 1978 "Invalid" 1977 "Invalid" 1976 "Invalid" 1975 "Invalid" 1974 "Invalid" 1973 "Invalid" 1972 "Invalid" 1971 "Invalid" 1970 "Invalid" 1969 "Invalid" 1968 "Invalid" 1967 "Invalid" 1966 "Invalid" 1965 "Invalid" 1964 "Invalid" 1963 "Invalid" 1962 "Invalid" 1961 "Invalid" 1960 "Invalid" 1959 "Invalid" 1958 "Invalid" 1957 "Invalid" 1956 "Invalid" 1955 "Invalid" 1954 "Invalid" 1953 "Invalid" 1952 "Invalid" 1951 "Invalid" 1950 "Invalid" 1949 "Invalid" 1948 "Invalid" 1947 "Invalid" 1946 "Invalid" 1945 "Invalid" 1944 "Invalid" 1943 "Invalid" 1942 "Invalid" 1941 "Invalid" 1940 "Invalid" 1939 "Invalid" 1938 "Invalid" 1937 "Invalid" 1936 "Invalid" 1935 "Invalid" 1934 "Invalid" 1933 "Invalid" 1932 "Invalid" 1931 "Invalid" 1930 "Invalid" 1929 "Invalid" 1928 "Invalid" 1927 "Invalid" 1926 "Invalid" 1925 "Invalid" 1924 "Invalid" 1923 "Invalid" 1922 "Invalid" 1921 "Invalid" 1920 "Invalid" 1919 "Invalid" 1918 "Invalid" 1917 "Invalid" 1916 "Invalid" 1915 "Invalid" 1914 "Invalid" 1913 "Invalid" 1912 "Invalid" 1911 "Invalid" 1910 "Invalid" 1909 "Invalid" 1908 "Invalid" 1907 "Invalid" 1906 "Invalid" 1905 "Invalid" 1904 "Invalid" 1903 "Invalid" 1902 "Invalid" 1901 "Invalid" 1900 "Invalid" 1899 "Invalid" 1898 "Invalid" 1897 "Invalid" 1896 "Invalid" 1895 "Invalid" 1894 "Invalid" 1893 "Invalid" 1892 "Invalid" 1891 "Invalid" 1890 "Invalid" 1889 "Invalid" 1888 "Invalid" 1887 "Invalid" 1886 "Invalid" 1885 "Invalid" 1884 "Invalid" 1883 "Invalid" 1882 "Invalid" 1881 "Invalid" 1880 "Invalid" 1879 "Invalid" 1878 "Invalid" 1877 "Invalid" 1876 "Invalid" 1875 "Invalid" 1874 "Invalid" 1873 "Invalid" 1872 "Invalid" 1871 "Invalid" 1870 "Invalid" 1869 "Invalid" 1868 "Invalid" 1867 "Invalid" 1866 "Invalid" 1865 "Invalid" 1864 "Invalid" 1863 "Invalid" 1862 "Invalid" 1861 "Invalid" 1860 "Invalid" 1859 "Invalid" 1858 "Invalid" 1857 "Invalid" 1856 "Invalid" 1855 "Invalid" 1854 "Invalid" 1853 "Invalid" 1852 "Invalid" 1851 "Invalid" 1850 "Invalid" 1849 "Invalid" 1848 "Invalid" 1847 "Invalid" 1846 "Invalid" 1845 "Invalid" 1844 "Invalid" 1843 "Invalid" 1842 "Invalid" 1841 "Invalid" 1840 "Invalid" 1839 "Invalid" 1838 "Invalid" 1837 "Invalid" 1836 "Invalid" 1835 "Invalid" 1834 "Invalid" 1833 "Invalid" 1832 "Invalid" 1831 "Invalid" 1830 "Invalid" 1829 "Invalid" 1828 "Invalid" 1827 "Invalid" 1826 "Invalid" 1825 "Invalid" 1824 "Invalid" 1823 "Invalid" 1822 "Invalid" 1821 "Invalid" 1820 "Invalid" 1819 "Invalid" 1818 "Invalid" 1817 "Invalid" 1816 "Invalid" 1815 "Invalid" 1814 "Invalid" 1813 "Invalid" 1812 "Invalid" 1811 "Invalid" 1810 "Invalid" 1809 "Invalid" 1808 "Invalid" 1807 "Invalid" 1806 "Invalid" 1805 "Invalid" 1804 "Invalid" 1803 "Invalid" 1802 "Invalid" 1801 "Invalid" ;
VAL_ 549 BCU_CellTmp003_RM 255 "Invalid" 254 "Invalid" 253 "Invalid" 252 "Invalid" 251 "Invalid" 250 "Invalid" 249 "Invalid" 248 "Invalid" 247 "Invalid" 246 "Invalid" 245 "Invalid" 244 "Invalid" 243 "Invalid" 242 "Invalid" 241 "Invalid" 240 "Invalid" 239 "Invalid" 238 "Invalid" 237 "Invalid" 236 "Invalid" 235 "Invalid" 234 "Invalid" 233 "Invalid" 232 "Invalid" 231 "Invalid" 230 "Invalid" 229 "Invalid" 228 "Invalid" 227 "Invalid" 226 "Invalid" 225 "Invalid" 224 "Invalid" 223 "Invalid" 222 "Invalid" 221 "Invalid" 220 "Invalid" 219 "Invalid" 218 "Invalid" 217 "Invalid" 216 "Invalid" 215 "Invalid" 214 "Invalid" 213 "Invalid" 212 "Invalid" 211 "Invalid" 210 "Invalid" 209 "Invalid" 208 "Invalid" 207 "Invalid" 206 "Invalid" 205 "Invalid" 204 "Invalid" 203 "Invalid" 202 "Invalid" 201 "Invalid" 200 "Invalid" 199 "Invalid" 198 "Invalid" 197 "Invalid" 196 "Invalid" 195 "Invalid" 194 "Invalid" 193 "Invalid" 192 "Invalid" 191 "Invalid" 190 "Invalid" 189 "Invalid" 188 "Invalid" 187 "Invalid" 186 "Invalid" 185 "Invalid" 184 "Invalid" 183 "Invalid" 182 "Invalid" 181 "Invalid" 180 "Invalid" 179 "Invalid" 178 "Invalid" 177 "Invalid" 176 "Invalid" 175 "Invalid" 174 "Invalid" 173 "Invalid" 172 "Invalid" 171 "Invalid" 170 "Invalid" 169 "Invalid" 168 "Invalid" 167 "Invalid" 166 "Invalid" 165 "Invalid" 164 "Invalid" 163 "Invalid" 162 "Invalid" 161 "Invalid" ;
VAL_ 550 BCU_CellVlt016_RM 2047 "Invalid" 2046 "Invalid" 2045 "Invalid" 2044 "Invalid" 2043 "Invalid" 2042 "Invalid" 2041 "Invalid" 2040 "Invalid" 2039 "Invalid" 2038 "Invalid" 2037 "Invalid" 2036 "Invalid" 2035 "Invalid" 2034 "Invalid" 2033 "Invalid" 2032 "Invalid" 2031 "Invalid" 2030 "Invalid" 2029 "Invalid" 2028 "Invalid" 2027 "Invalid" 2026 "Invalid" 2025 "Invalid" 2024 "Invalid" 2023 "Invalid" 2022 "Invalid" 2021 "Invalid" 2020 "Invalid" 2019 "Invalid" 2018 "Invalid" 2017 "Invalid" 2016 "Invalid" 2015 "Invalid" 2014 "Invalid" 2013 "Invalid" 2012 "Invalid" 2011 "Invalid" 2010 "Invalid" 2009 "Invalid" 2008 "Invalid" 2007 "Invalid" 2006 "Invalid" 2005 "Invalid" 2004 "Invalid" 2003 "Invalid" 2002 "Invalid" 2001 "Invalid" 2000 "Invalid" 1999 "Invalid" 1998 "Invalid" 1997 "Invalid" 1996 "Invalid" 1995 "Invalid" 1994 "Invalid" 1993 "Invalid" 1992 "Invalid" 1991 "Invalid" 1990 "Invalid" 1989 "Invalid" 1988 "Invalid" 1987 "Invalid" 1986 "Invalid" 1985 "Invalid" 1984 "Invalid" 1983 "Invalid" 1982 "Invalid" 1981 "Invalid" 1980 "Invalid" 1979 "Invalid" 1978 "Invalid" 1977 "Invalid" 1976 "Invalid" 1975 "Invalid" 1974 "Invalid" 1973 "Invalid" 1972 "Invalid" 1971 "Invalid" 1970 "Invalid" 1969 "Invalid" 1968 "Invalid" 1967 "Invalid" 1966 "Invalid" 1965 "Invalid" 1964 "Invalid" 1963 "Invalid" 1962 "Invalid" 1961 "Invalid" 1960 "Invalid" 1959 "Invalid" 1958 "Invalid" 1957 "Invalid" 1956 "Invalid" 1955 "Invalid" 1954 "Invalid" 1953 "Invalid" 1952 "Invalid" 1951 "Invalid" 1950 "Invalid" 1949 "Invalid" 1948 "Invalid" 1947 "Invalid" 1946 "Invalid" 1945 "Invalid" 1944 "Invalid" 1943 "Invalid" 1942 "Invalid" 1941 "Invalid" 1940 "Invalid" 1939 "Invalid" 1938 "Invalid" 1937 "Invalid" 1936 "Invalid" 1935 "Invalid" 1934 "Invalid" 1933 "Invalid" 1932 "Invalid" 1931 "Invalid" 1930 "Invalid" 1929 "Invalid" 1928 "Invalid" 1927 "Invalid" 1926 "Invalid" 1925 "Invalid" 1924 "Invalid" 1923 "Invalid" 1922 "Invalid" 1921 "Invalid" 1920 "Invalid" 1919 "Invalid" 1918 "Invalid" 1917 "Invalid" 1916 "Invalid" 1915 "Invalid" 1914 "Invalid" 1913 "Invalid" 1912 "Invalid" 1911 "Invalid" 1910 "Invalid" 1909 "Invalid" 1908 "Invalid" 1907 "Invalid" 1906 "Invalid" 1905 "Invalid" 1904 "Invalid" 1903 "Invalid" 1902 "Invalid" 1901 "Invalid" 1900 "Invalid" 1899 "Invalid" 1898 "Invalid" 1897 "Invalid" 1896 "Invalid" 1895 "Invalid" 1894 "Invalid" 1893 "Invalid" 1892 "Invalid" 1891 "Invalid" 1890 "Invalid" 1889 "Invalid" 1888 "Invalid" 1887 "Invalid" 1886 "Invalid" 1885 "Invalid" 1884 "Invalid" 1883 "Invalid" 1882 "Invalid" 1881 "Invalid" 1880 "Invalid" 1879 "Invalid" 1878 "Invalid" 1877 "Invalid" 1876 "Invalid" 1875 "Invalid" 1874 "Invalid" 1873 "Invalid" 1872 "Invalid" 1871 "Invalid" 1870 "Invalid" 1869 "Invalid" 1868 "Invalid" 1867 "Invalid" 1866 "Invalid" 1865 "Invalid" 1864 "Invalid" 1863 "Invalid" 1862 "Invalid" 1861 "Invalid" 1860 "Invalid" 1859 "Invalid" 1858 "Invalid" 1857 "Invalid" 1856 "Invalid" 1855 "Invalid" 1854 "Invalid" 1853 "Invalid" 1852 "Invalid" 1851 "Invalid" 1850 "Invalid" 1849 "Invalid" 1848 "Invalid" 1847 "Invalid" 1846 "Invalid" 1845 "Invalid" 1844 "Invalid" 1843 "Invalid" 1842 "Invalid" 1841 "Invalid" 1840 "Invalid" 1839 "Invalid" 1838 "Invalid" 1837 "Invalid" 1836 "Invalid" 1835 "Invalid" 1834 "Invalid" 1833 "Invalid" 1832 "Invalid" 1831 "Invalid" 1830 "Invalid" 1829 "Invalid" 1828 "Invalid" 1827 "Invalid" 1826 "Invalid" 1825 "Invalid" 1824 "Invalid" 1823 "Invalid" 1822 "Invalid" 1821 "Invalid" 1820 "Invalid" 1819 "Invalid" 1818 "Invalid" 1817 "Invalid" 1816 "Invalid" 1815 "Invalid" 1814 "Invalid" 1813 "Invalid" 1812 "Invalid" 1811 "Invalid" 1810 "Invalid" 1809 "Invalid" 1808 "Invalid" 1807 "Invalid" 1806 "Invalid" 1805 "Invalid" 1804 "Invalid" 1803 "Invalid" 1802 "Invalid" 1801 "Invalid" ;
VAL_ 550 BCU_CellVlt017_RM 2047 "Invalid" 2046 "Invalid" 2045 "Invalid" 2044 "Invalid" 2043 "Invalid" 2042 "Invalid" 2041 "Invalid" 2040 "Invalid" 2039 "Invalid" 2038 "Invalid" 2037 "Invalid" 2036 "Invalid" 2035 "Invalid" 2034 "Invalid" 2033 "Invalid" 2032 "Invalid" 2031 "Invalid" 2030 "Invalid" 2029 "Invalid" 2028 "Invalid" 2027 "Invalid" 2026 "Invalid" 2025 "Invalid" 2024 "Invalid" 2023 "Invalid" 2022 "Invalid" 2021 "Invalid" 2020 "Invalid" 2019 "Invalid" 2018 "Invalid" 2017 "Invalid" 2016 "Invalid" 2015 "Invalid" 2014 "Invalid" 2013 "Invalid" 2012 "Invalid" 2011 "Invalid" 2010 "Invalid" 2009 "Invalid" 2008 "Invalid" 2007 "Invalid" 2006 "Invalid" 2005 "Invalid" 2004 "Invalid" 2003 "Invalid" 2002 "Invalid" 2001 "Invalid" 2000 "Invalid" 1999 "Invalid" 1998 "Invalid" 1997 "Invalid" 1996 "Invalid" 1995 "Invalid" 1994 "Invalid" 1993 "Invalid" 1992 "Invalid" 1991 "Invalid" 1990 "Invalid" 1989 "Invalid" 1988 "Invalid" 1987 "Invalid" 1986 "Invalid" 1985 "Invalid" 1984 "Invalid" 1983 "Invalid" 1982 "Invalid" 1981 "Invalid" 1980 "Invalid" 1979 "Invalid" 1978 "Invalid" 1977 "Invalid" 1976 "Invalid" 1975 "Invalid" 1974 "Invalid" 1973 "Invalid" 1972 "Invalid" 1971 "Invalid" 1970 "Invalid" 1969 "Invalid" 1968 "Invalid" 1967 "Invalid" 1966 "Invalid" 1965 "Invalid" 1964 "Invalid" 1963 "Invalid" 1962 "Invalid" 1961 "Invalid" 1960 "Invalid" 1959 "Invalid" 1958 "Invalid" 1957 "Invalid" 1956 "Invalid" 1955 "Invalid" 1954 "Invalid" 1953 "Invalid" 1952 "Invalid" 1951 "Invalid" 1950 "Invalid" 1949 "Invalid" 1948 "Invalid" 1947 "Invalid" 1946 "Invalid" 1945 "Invalid" 1944 "Invalid" 1943 "Invalid" 1942 "Invalid" 1941 "Invalid" 1940 "Invalid" 1939 "Invalid" 1938 "Invalid" 1937 "Invalid" 1936 "Invalid" 1935 "Invalid" 1934 "Invalid" 1933 "Invalid" 1932 "Invalid" 1931 "Invalid" 1930 "Invalid" 1929 "Invalid" 1928 "Invalid" 1927 "Invalid" 1926 "Invalid" 1925 "Invalid" 1924 "Invalid" 1923 "Invalid" 1922 "Invalid" 1921 "Invalid" 1920 "Invalid" 1919 "Invalid" 1918 "Invalid" 1917 "Invalid" 1916 "Invalid" 1915 "Invalid" 1914 "Invalid" 1913 "Invalid" 1912 "Invalid" 1911 "Invalid" 1910 "Invalid" 1909 "Invalid" 1908 "Invalid" 1907 "Invalid" 1906 "Invalid" 1905 "Invalid" 1904 "Invalid" 1903 "Invalid" 1902 "Invalid" 1901 "Invalid" 1900 "Invalid" 1899 "Invalid" 1898 "Invalid" 1897 "Invalid" 1896 "Invalid" 1895 "Invalid" 1894 "Invalid" 1893 "Invalid" 1892 "Invalid" 1891 "Invalid" 1890 "Invalid" 1889 "Invalid" 1888 "Invalid" 1887 "Invalid" 1886 "Invalid" 1885 "Invalid" 1884 "Invalid" 1883 "Invalid" 1882 "Invalid" 1881 "Invalid" 1880 "Invalid" 1879 "Invalid" 1878 "Invalid" 1877 "Invalid" 1876 "Invalid" 1875 "Invalid" 1874 "Invalid" 1873 "Invalid" 1872 "Invalid" 1871 "Invalid" 1870 "Invalid" 1869 "Invalid" 1868 "Invalid" 1867 "Invalid" 1866 "Invalid" 1865 "Invalid" 1864 "Invalid" 1863 "Invalid" 1862 "Invalid" 1861 "Invalid" 1860 "Invalid" 1859 "Invalid" 1858 "Invalid" 1857 "Invalid" 1856 "Invalid" 1855 "Invalid" 1854 "Invalid" 1853 "Invalid" 1852 "Invalid" 1851 "Invalid" 1850 "Invalid" 1849 "Invalid" 1848 "Invalid" 1847 "Invalid" 1846 "Invalid" 1845 "Invalid" 1844 "Invalid" 1843 "Invalid" 1842 "Invalid" 1841 "Invalid" 1840 "Invalid" 1839 "Invalid" 1838 "Invalid" 1837 "Invalid" 1836 "Invalid" 1835 "Invalid" 1834 "Invalid" 1833 "Invalid" 1832 "Invalid" 1831 "Invalid" 1830 "Invalid" 1829 "Invalid" 1828 "Invalid" 1827 "Invalid" 1826 "Invalid" 1825 "Invalid" 1824 "Invalid" 1823 "Invalid" 1822 "Invalid" 1821 "Invalid" 1820 "Invalid" 1819 "Invalid" 1818 "Invalid" 1817 "Invalid" 1816 "Invalid" 1815 "Invalid" 1814 "Invalid" 1813 "Invalid" 1812 "Invalid" 1811 "Invalid" 1810 "Invalid" 1809 "Invalid" 1808 "Invalid" 1807 "Invalid" 1806 "Invalid" 1805 "Invalid" 1804 "Invalid" 1803 "Invalid" 1802 "Invalid" 1801 "Invalid" ;
VAL_ 550 BCU_CellVlt018_RM 2047 "Invalid" 2046 "Invalid" 2045 "Invalid" 2044 "Invalid" 2043 "Invalid" 2042 "Invalid" 2041 "Invalid" 2040 "Invalid" 2039 "Invalid" 2038 "Invalid" 2037 "Invalid" 2036 "Invalid" 2035 "Invalid" 2034 "Invalid" 2033 "Invalid" 2032 "Invalid" 2031 "Invalid" 2030 "Invalid" 2029 "Invalid" 2028 "Invalid" 2027 "Invalid" 2026 "Invalid" 2025 "Invalid" 2024 "Invalid" 2023 "Invalid" 2022 "Invalid" 2021 "Invalid" 2020 "Invalid" 2019 "Invalid" 2018 "Invalid" 2017 "Invalid" 2016 "Invalid" 2015 "Invalid" 2014 "Invalid" 2013 "Invalid" 2012 "Invalid" 2011 "Invalid" 2010 "Invalid" 2009 "Invalid" 2008 "Invalid" 2007 "Invalid" 2006 "Invalid" 2005 "Invalid" 2004 "Invalid" 2003 "Invalid" 2002 "Invalid" 2001 "Invalid" 2000 "Invalid" 1999 "Invalid" 1998 "Invalid" 1997 "Invalid" 1996 "Invalid" 1995 "Invalid" 1994 "Invalid" 1993 "Invalid" 1992 "Invalid" 1991 "Invalid" 1990 "Invalid" 1989 "Invalid" 1988 "Invalid" 1987 "Invalid" 1986 "Invalid" 1985 "Invalid" 1984 "Invalid" 1983 "Invalid" 1982 "Invalid" 1981 "Invalid" 1980 "Invalid" 1979 "Invalid" 1978 "Invalid" 1977 "Invalid" 1976 "Invalid" 1975 "Invalid" 1974 "Invalid" 1973 "Invalid" 1972 "Invalid" 1971 "Invalid" 1970 "Invalid" 1969 "Invalid" 1968 "Invalid" 1967 "Invalid" 1966 "Invalid" 1965 "Invalid" 1964 "Invalid" 1963 "Invalid" 1962 "Invalid" 1961 "Invalid" 1960 "Invalid" 1959 "Invalid" 1958 "Invalid" 1957 "Invalid" 1956 "Invalid" 1955 "Invalid" 1954 "Invalid" 1953 "Invalid" 1952 "Invalid" 1951 "Invalid" 1950 "Invalid" 1949 "Invalid" 1948 "Invalid" 1947 "Invalid" 1946 "Invalid" 1945 "Invalid" 1944 "Invalid" 1943 "Invalid" 1942 "Invalid" 1941 "Invalid" 1940 "Invalid" 1939 "Invalid" 1938 "Invalid" 1937 "Invalid" 1936 "Invalid" 1935 "Invalid" 1934 "Invalid" 1933 "Invalid" 1932 "Invalid" 1931 "Invalid" 1930 "Invalid" 1929 "Invalid" 1928 "Invalid" 1927 "Invalid" 1926 "Invalid" 1925 "Invalid" 1924 "Invalid" 1923 "Invalid" 1922 "Invalid" 1921 "Invalid" 1920 "Invalid" 1919 "Invalid" 1918 "Invalid" 1917 "Invalid" 1916 "Invalid" 1915 "Invalid" 1914 "Invalid" 1913 "Invalid" 1912 "Invalid" 1911 "Invalid" 1910 "Invalid" 1909 "Invalid" 1908 "Invalid" 1907 "Invalid" 1906 "Invalid" 1905 "Invalid" 1904 "Invalid" 1903 "Invalid" 1902 "Invalid" 1901 "Invalid" 1900 "Invalid" 1899 "Invalid" 1898 "Invalid" 1897 "Invalid" 1896 "Invalid" 1895 "Invalid" 1894 "Invalid" 1893 "Invalid" 1892 "Invalid" 1891 "Invalid" 1890 "Invalid" 1889 "Invalid" 1888 "Invalid" 1887 "Invalid" 1886 "Invalid" 1885 "Invalid" 1884 "Invalid" 1883 "Invalid" 1882 "Invalid" 1881 "Invalid" 1880 "Invalid" 1879 "Invalid" 1878 "Invalid" 1877 "Invalid" 1876 "Invalid" 1875 "Invalid" 1874 "Invalid" 1873 "Invalid" 1872 "Invalid" 1871 "Invalid" 1870 "Invalid" 1869 "Invalid" 1868 "Invalid" 1867 "Invalid" 1866 "Invalid" 1865 "Invalid" 1864 "Invalid" 1863 "Invalid" 1862 "Invalid" 1861 "Invalid" 1860 "Invalid" 1859 "Invalid" 1858 "Invalid" 1857 "Invalid" 1856 "Invalid" 1855 "Invalid" 1854 "Invalid" 1853 "Invalid" 1852 "Invalid" 1851 "Invalid" 1850 "Invalid" 1849 "Invalid" 1848 "Invalid" 1847 "Invalid" 1846 "Invalid" 1845 "Invalid" 1844 "Invalid" 1843 "Invalid" 1842 "Invalid" 1841 "Invalid" 1840 "Invalid" 1839 "Invalid" 1838 "Invalid" 1837 "Invalid" 1836 "Invalid" 1835 "Invalid" 1834 "Invalid" 1833 "Invalid" 1832 "Invalid" 1831 "Invalid" 1830 "Invalid" 1829 "Invalid" 1828 "Invalid" 1827 "Invalid" 1826 "Invalid" 1825 "Invalid" 1824 "Invalid" 1823 "Invalid" 1822 "Invalid" 1821 "Invalid" 1820 "Invalid" 1819 "Invalid" 1818 "Invalid" 1817 "Invalid" 1816 "Invalid" 1815 "Invalid" 1814 "Invalid" 1813 "Invalid" 1812 "Invalid" 1811 "Invalid" 1810 "Invalid" 1809 "Invalid" 1808 "Invalid" 1807 "Invalid" 1806 "Invalid" 1805 "Invalid" 1804 "Invalid" 1803 "Invalid" 1802 "Invalid" 1801 "Invalid" ;
VAL_ 550 BCU_CellVlt019_RM 2047 "Invalid" 2046 "Invalid" 2045 "Invalid" 2044 "Invalid" 2043 "Invalid" 2042 "Invalid" 2041 "Invalid" 2040 "Invalid" 2039 "Invalid" 2038 "Invalid" 2037 "Invalid" 2036 "Invalid" 2035 "Invalid" 2034 "Invalid" 2033 "Invalid" 2032 "Invalid" 2031 "Invalid" 2030 "Invalid" 2029 "Invalid" 2028 "Invalid" 2027 "Invalid" 2026 "Invalid" 2025 "Invalid" 2024 "Invalid" 2023 "Invalid" 2022 "Invalid" 2021 "Invalid" 2020 "Invalid" 2019 "Invalid" 2018 "Invalid" 2017 "Invalid" 2016 "Invalid" 2015 "Invalid" 2014 "Invalid" 2013 "Invalid" 2012 "Invalid" 2011 "Invalid" 2010 "Invalid" 2009 "Invalid" 2008 "Invalid" 2007 "Invalid" 2006 "Invalid" 2005 "Invalid" 2004 "Invalid" 2003 "Invalid" 2002 "Invalid" 2001 "Invalid" 2000 "Invalid" 1999 "Invalid" 1998 "Invalid" 1997 "Invalid" 1996 "Invalid" 1995 "Invalid" 1994 "Invalid" 1993 "Invalid" 1992 "Invalid" 1991 "Invalid" 1990 "Invalid" 1989 "Invalid" 1988 "Invalid" 1987 "Invalid" 1986 "Invalid" 1985 "Invalid" 1984 "Invalid" 1983 "Invalid" 1982 "Invalid" 1981 "Invalid" 1980 "Invalid" 1979 "Invalid" 1978 "Invalid" 1977 "Invalid" 1976 "Invalid" 1975 "Invalid" 1974 "Invalid" 1973 "Invalid" 1972 "Invalid" 1971 "Invalid" 1970 "Invalid" 1969 "Invalid" 1968 "Invalid" 1967 "Invalid" 1966 "Invalid" 1965 "Invalid" 1964 "Invalid" 1963 "Invalid" 1962 "Invalid" 1961 "Invalid" 1960 "Invalid" 1959 "Invalid" 1958 "Invalid" 1957 "Invalid" 1956 "Invalid" 1955 "Invalid" 1954 "Invalid" 1953 "Invalid" 1952 "Invalid" 1951 "Invalid" 1950 "Invalid" 1949 "Invalid" 1948 "Invalid" 1947 "Invalid" 1946 "Invalid" 1945 "Invalid" 1944 "Invalid" 1943 "Invalid" 1942 "Invalid" 1941 "Invalid" 1940 "Invalid" 1939 "Invalid" 1938 "Invalid" 1937 "Invalid" 1936 "Invalid" 1935 "Invalid" 1934 "Invalid" 1933 "Invalid" 1932 "Invalid" 1931 "Invalid" 1930 "Invalid" 1929 "Invalid" 1928 "Invalid" 1927 "Invalid" 1926 "Invalid" 1925 "Invalid" 1924 "Invalid" 1923 "Invalid" 1922 "Invalid" 1921 "Invalid" 1920 "Invalid" 1919 "Invalid" 1918 "Invalid" 1917 "Invalid" 1916 "Invalid" 1915 "Invalid" 1914 "Invalid" 1913 "Invalid" 1912 "Invalid" 1911 "Invalid" 1910 "Invalid" 1909 "Invalid" 1908 "Invalid" 1907 "Invalid" 1906 "Invalid" 1905 "Invalid" 1904 "Invalid" 1903 "Invalid" 1902 "Invalid" 1901 "Invalid" 1900 "Invalid" 1899 "Invalid" 1898 "Invalid" 1897 "Invalid" 1896 "Invalid" 1895 "Invalid" 1894 "Invalid" 1893 "Invalid" 1892 "Invalid" 1891 "Invalid" 1890 "Invalid" 1889 "Invalid" 1888 "Invalid" 1887 "Invalid" 1886 "Invalid" 1885 "Invalid" 1884 "Invalid" 1883 "Invalid" 1882 "Invalid" 1881 "Invalid" 1880 "Invalid" 1879 "Invalid" 1878 "Invalid" 1877 "Invalid" 1876 "Invalid" 1875 "Invalid" 1874 "Invalid" 1873 "Invalid" 1872 "Invalid" 1871 "Invalid" 1870 "Invalid" 1869 "Invalid" 1868 "Invalid" 1867 "Invalid" 1866 "Invalid" 1865 "Invalid" 1864 "Invalid" 1863 "Invalid" 1862 "Invalid" 1861 "Invalid" 1860 "Invalid" 1859 "Invalid" 1858 "Invalid" 1857 "Invalid" 1856 "Invalid" 1855 "Invalid" 1854 "Invalid" 1853 "Invalid" 1852 "Invalid" 1851 "Invalid" 1850 "Invalid" 1849 "Invalid" 1848 "Invalid" 1847 "Invalid" 1846 "Invalid" 1845 "Invalid" 1844 "Invalid" 1843 "Invalid" 1842 "Invalid" 1841 "Invalid" 1840 "Invalid" 1839 "Invalid" 1838 "Invalid" 1837 "Invalid" 1836 "Invalid" 1835 "Invalid" 1834 "Invalid" 1833 "Invalid" 1832 "Invalid" 1831 "Invalid" 1830 "Invalid" 1829 "Invalid" 1828 "Invalid" 1827 "Invalid" 1826 "Invalid" 1825 "Invalid" 1824 "Invalid" 1823 "Invalid" 1822 "Invalid" 1821 "Invalid" 1820 "Invalid" 1819 "Invalid" 1818 "Invalid" 1817 "Invalid" 1816 "Invalid" 1815 "Invalid" 1814 "Invalid" 1813 "Invalid" 1812 "Invalid" 1811 "Invalid" 1810 "Invalid" 1809 "Invalid" 1808 "Invalid" 1807 "Invalid" 1806 "Invalid" 1805 "Invalid" 1804 "Invalid" 1803 "Invalid" 1802 "Invalid" 1801 "Invalid" ;
VAL_ 550 BCU_CellVlt020_RM 2047 "Invalid" 2046 "Invalid" 2045 "Invalid" 2044 "Invalid" 2043 "Invalid" 2042 "Invalid" 2041 "Invalid" 2040 "Invalid" 2039 "Invalid" 2038 "Invalid" 2037 "Invalid" 2036 "Invalid" 2035 "Invalid" 2034 "Invalid" 2033 "Invalid" 2032 "Invalid" 2031 "Invalid" 2030 "Invalid" 2029 "Invalid" 2028 "Invalid" 2027 "Invalid" 2026 "Invalid" 2025 "Invalid" 2024 "Invalid" 2023 "Invalid" 2022 "Invalid" 2021 "Invalid" 2020 "Invalid" 2019 "Invalid" 2018 "Invalid" 2017 "Invalid" 2016 "Invalid" 2015 "Invalid" 2014 "Invalid" 2013 "Invalid" 2012 "Invalid" 2011 "Invalid" 2010 "Invalid" 2009 "Invalid" 2008 "Invalid" 2007 "Invalid" 2006 "Invalid" 2005 "Invalid" 2004 "Invalid" 2003 "Invalid" 2002 "Invalid" 2001 "Invalid" 2000 "Invalid" 1999 "Invalid" 1998 "Invalid" 1997 "Invalid" 1996 "Invalid" 1995 "Invalid" 1994 "Invalid" 1993 "Invalid" 1992 "Invalid" 1991 "Invalid" 1990 "Invalid" 1989 "Invalid" 1988 "Invalid" 1987 "Invalid" 1986 "Invalid" 1985 "Invalid" 1984 "Invalid" 1983 "Invalid" 1982 "Invalid" 1981 "Invalid" 1980 "Invalid" 1979 "Invalid" 1978 "Invalid" 1977 "Invalid" 1976 "Invalid" 1975 "Invalid" 1974 "Invalid" 1973 "Invalid" 1972 "Invalid" 1971 "Invalid" 1970 "Invalid" 1969 "Invalid" 1968 "Invalid" 1967 "Invalid" 1966 "Invalid" 1965 "Invalid" 1964 "Invalid" 1963 "Invalid" 1962 "Invalid" 1961 "Invalid" 1960 "Invalid" 1959 "Invalid" 1958 "Invalid" 1957 "Invalid" 1956 "Invalid" 1955 "Invalid" 1954 "Invalid" 1953 "Invalid" 1952 "Invalid" 1951 "Invalid" 1950 "Invalid" 1949 "Invalid" 1948 "Invalid" 1947 "Invalid" 1946 "Invalid" 1945 "Invalid" 1944 "Invalid" 1943 "Invalid" 1942 "Invalid" 1941 "Invalid" 1940 "Invalid" 1939 "Invalid" 1938 "Invalid" 1937 "Invalid" 1936 "Invalid" 1935 "Invalid" 1934 "Invalid" 1933 "Invalid" 1932 "Invalid" 1931 "Invalid" 1930 "Invalid" 1929 "Invalid" 1928 "Invalid" 1927 "Invalid" 1926 "Invalid" 1925 "Invalid" 1924 "Invalid" 1923 "Invalid" 1922 "Invalid" 1921 "Invalid" 1920 "Invalid" 1919 "Invalid" 1918 "Invalid" 1917 "Invalid" 1916 "Invalid" 1915 "Invalid" 1914 "Invalid" 1913 "Invalid" 1912 "Invalid" 1911 "Invalid" 1910 "Invalid" 1909 "Invalid" 1908 "Invalid" 1907 "Invalid" 1906 "Invalid" 1905 "Invalid" 1904 "Invalid" 1903 "Invalid" 1902 "Invalid" 1901 "Invalid" 1900 "Invalid" 1899 "Invalid" 1898 "Invalid" 1897 "Invalid" 1896 "Invalid" 1895 "Invalid" 1894 "Invalid" 1893 "Invalid" 1892 "Invalid" 1891 "Invalid" 1890 "Invalid" 1889 "Invalid" 1888 "Invalid" 1887 "Invalid" 1886 "Invalid" 1885 "Invalid" 1884 "Invalid" 1883 "Invalid" 1882 "Invalid" 1881 "Invalid" 1880 "Invalid" 1879 "Invalid" 1878 "Invalid" 1877 "Invalid" 1876 "Invalid" 1875 "Invalid" 1874 "Invalid" 1873 "Invalid" 1872 "Invalid" 1871 "Invalid" 1870 "Invalid" 1869 "Invalid" 1868 "Invalid" 1867 "Invalid" 1866 "Invalid" 1865 "Invalid" 1864 "Invalid" 1863 "Invalid" 1862 "Invalid" 1861 "Invalid" 1860 "Invalid" 1859 "Invalid" 1858 "Invalid" 1857 "Invalid" 1856 "Invalid" 1855 "Invalid" 1854 "Invalid" 1853 "Invalid" 1852 "Invalid" 1851 "Invalid" 1850 "Invalid" 1849 "Invalid" 1848 "Invalid" 1847 "Invalid" 1846 "Invalid" 1845 "Invalid" 1844 "Invalid" 1843 "Invalid" 1842 "Invalid" 1841 "Invalid" 1840 "Invalid" 1839 "Invalid" 1838 "Invalid" 1837 "Invalid" 1836 "Invalid" 1835 "Invalid" 1834 "Invalid" 1833 "Invalid" 1832 "Invalid" 1831 "Invalid" 1830 "Invalid" 1829 "Invalid" 1828 "Invalid" 1827 "Invalid" 1826 "Invalid" 1825 "Invalid" 1824 "Invalid" 1823 "Invalid" 1822 "Invalid" 1821 "Invalid" 1820 "Invalid" 1819 "Invalid" 1818 "Invalid" 1817 "Invalid" 1816 "Invalid" 1815 "Invalid" 1814 "Invalid" 1813 "Invalid" 1812 "Invalid" 1811 "Invalid" 1810 "Invalid" 1809 "Invalid" 1808 "Invalid" 1807 "Invalid" 1806 "Invalid" 1805 "Invalid" 1804 "Invalid" 1803 "Invalid" 1802 "Invalid" 1801 "Invalid" ;
VAL_ 550 BCU_CellTmp004_RM 255 "Invalid" 254 "Invalid" 253 "Invalid" 252 "Invalid" 251 "Invalid" 250 "Invalid" 249 "Invalid" 248 "Invalid" 247 "Invalid" 246 "Invalid" 245 "Invalid" 244 "Invalid" 243 "Invalid" 242 "Invalid" 241 "Invalid" 240 "Invalid" 239 "Invalid" 238 "Invalid" 237 "Invalid" 236 "Invalid" 235 "Invalid" 234 "Invalid" 233 "Invalid" 232 "Invalid" 231 "Invalid" 230 "Invalid" 229 "Invalid" 228 "Invalid" 227 "Invalid" 226 "Invalid" 225 "Invalid" 224 "Invalid" 223 "Invalid" 222 "Invalid" 221 "Invalid" 220 "Invalid" 219 "Invalid" 218 "Invalid" 217 "Invalid" 216 "Invalid" 215 "Invalid" 214 "Invalid" 213 "Invalid" 212 "Invalid" 211 "Invalid" 210 "Invalid" 209 "Invalid" 208 "Invalid" 207 "Invalid" 206 "Invalid" 205 "Invalid" 204 "Invalid" 203 "Invalid" 202 "Invalid" 201 "Invalid" 200 "Invalid" 199 "Invalid" 198 "Invalid" 197 "Invalid" 196 "Invalid" 195 "Invalid" 194 "Invalid" 193 "Invalid" 192 "Invalid" 191 "Invalid" 190 "Invalid" 189 "Invalid" 188 "Invalid" 187 "Invalid" 186 "Invalid" 185 "Invalid" 184 "Invalid" 183 "Invalid" 182 "Invalid" 181 "Invalid" 180 "Invalid" 179 "Invalid" 178 "Invalid" 177 "Invalid" 176 "Invalid" 175 "Invalid" 174 "Invalid" 173 "Invalid" 172 "Invalid" 171 "Invalid" 170 "Invalid" 169 "Invalid" 168 "Invalid" 167 "Invalid" 166 "Invalid" 165 "Invalid" 164 "Invalid" 163 "Invalid" 162 "Invalid" 161 "Invalid" ;
VAL_ 551 BCU_CellVlt021_RM 2047 "Invalid" 2046 "Invalid" 2045 "Invalid" 2044 "Invalid" 2043 "Invalid" 2042 "Invalid" 2041 "Invalid" 2040 "Invalid" 2039 "Invalid" 2038 "Invalid" 2037 "Invalid" 2036 "Invalid" 2035 "Invalid" 2034 "Invalid" 2033 "Invalid" 2032 "Invalid" 2031 "Invalid" 2030 "Invalid" 2029 "Invalid" 2028 "Invalid" 2027 "Invalid" 2026 "Invalid" 2025 "Invalid" 2024 "Invalid" 2023 "Invalid" 2022 "Invalid" 2021 "Invalid" 2020 "Invalid" 2019 "Invalid" 2018 "Invalid" 2017 "Invalid" 2016 "Invalid" 2015 "Invalid" 2014 "Invalid" 2013 "Invalid" 2012 "Invalid" 2011 "Invalid" 2010 "Invalid" 2009 "Invalid" 2008 "Invalid" 2007 "Invalid" 2006 "Invalid" 2005 "Invalid" 2004 "Invalid" 2003 "Invalid" 2002 "Invalid" 2001 "Invalid" 2000 "Invalid" 1999 "Invalid" 1998 "Invalid" 1997 "Invalid" 1996 "Invalid" 1995 "Invalid" 1994 "Invalid" 1993 "Invalid" 1992 "Invalid" 1991 "Invalid" 1990 "Invalid" 1989 "Invalid" 1988 "Invalid" 1987 "Invalid" 1986 "Invalid" 1985 "Invalid" 1984 "Invalid" 1983 "Invalid" 1982 "Invalid" 1981 "Invalid" 1980 "Invalid" 1979 "Invalid" 1978 "Invalid" 1977 "Invalid" 1976 "Invalid" 1975 "Invalid" 1974 "Invalid" 1973 "Invalid" 1972 "Invalid" 1971 "Invalid" 1970 "Invalid" 1969 "Invalid" 1968 "Invalid" 1967 "Invalid" 1966 "Invalid" 1965 "Invalid" 1964 "Invalid" 1963 "Invalid" 1962 "Invalid" 1961 "Invalid" 1960 "Invalid" 1959 "Invalid" 1958 "Invalid" 1957 "Invalid" 1956 "Invalid" 1955 "Invalid" 1954 "Invalid" 1953 "Invalid" 1952 "Invalid" 1951 "Invalid" 1950 "Invalid" 1949 "Invalid" 1948 "Invalid" 1947 "Invalid" 1946 "Invalid" 1945 "Invalid" 1944 "Invalid" 1943 "Invalid" 1942 "Invalid" 1941 "Invalid" 1940 "Invalid" 1939 "Invalid" 1938 "Invalid" 1937 "Invalid" 1936 "Invalid" 1935 "Invalid" 1934 "Invalid" 1933 "Invalid" 1932 "Invalid" 1931 "Invalid" 1930 "Invalid" 1929 "Invalid" 1928 "Invalid" 1927 "Invalid" 1926 "Invalid" 1925 "Invalid" 1924 "Invalid" 1923 "Invalid" 1922 "Invalid" 1921 "Invalid" 1920 "Invalid" 1919 "Invalid" 1918 "Invalid" 1917 "Invalid" 1916 "Invalid" 1915 "Invalid" 1914 "Invalid" 1913 "Invalid" 1912 "Invalid" 1911 "Invalid" 1910 "Invalid" 1909 "Invalid" 1908 "Invalid" 1907 "Invalid" 1906 "Invalid" 1905 "Invalid" 1904 "Invalid" 1903 "Invalid" 1902 "Invalid" 1901 "Invalid" 1900 "Invalid" 1899 "Invalid" 1898 "Invalid" 1897 "Invalid" 1896 "Invalid" 1895 "Invalid" 1894 "Invalid" 1893 "Invalid" 1892 "Invalid" 1891 "Invalid" 1890 "Invalid" 1889 "Invalid" 1888 "Invalid" 1887 "Invalid" 1886 "Invalid" 1885 "Invalid" 1884 "Invalid" 1883 "Invalid" 1882 "Invalid" 1881 "Invalid" 1880 "Invalid" 1879 "Invalid" 1878 "Invalid" 1877 "Invalid" 1876 "Invalid" 1875 "Invalid" 1874 "Invalid" 1873 "Invalid" 1872 "Invalid" 1871 "Invalid" 1870 "Invalid" 1869 "Invalid" 1868 "Invalid" 1867 "Invalid" 1866 "Invalid" 1865 "Invalid" 1864 "Invalid" 1863 "Invalid" 1862 "Invalid" 1861 "Invalid" 1860 "Invalid" 1859 "Invalid" 1858 "Invalid" 1857 "Invalid" 1856 "Invalid" 1855 "Invalid" 1854 "Invalid" 1853 "Invalid" 1852 "Invalid" 1851 "Invalid" 1850 "Invalid" 1849 "Invalid" 1848 "Invalid" 1847 "Invalid" 1846 "Invalid" 1845 "Invalid" 1844 "Invalid" 1843 "Invalid" 1842 "Invalid" 1841 "Invalid" 1840 "Invalid" 1839 "Invalid" 1838 "Invalid" 1837 "Invalid" 1836 "Invalid" 1835 "Invalid" 1834 "Invalid" 1833 "Invalid" 1832 "Invalid" 1831 "Invalid" 1830 "Invalid" 1829 "Invalid" 1828 "Invalid" 1827 "Invalid" 1826 "Invalid" 1825 "Invalid" 1824 "Invalid" 1823 "Invalid" 1822 "Invalid" 1821 "Invalid" 1820 "Invalid" 1819 "Invalid" 1818 "Invalid" 1817 "Invalid" 1816 "Invalid" 1815 "Invalid" 1814 "Invalid" 1813 "Invalid" 1812 "Invalid" 1811 "Invalid" 1810 "Invalid" 1809 "Invalid" 1808 "Invalid" 1807 "Invalid" 1806 "Invalid" 1805 "Invalid" 1804 "Invalid" 1803 "Invalid" 1802 "Invalid" 1801 "Invalid" ;
VAL_ 551 BCU_CellVlt022_RM 2047 "Invalid" 2046 "Invalid" 2045 "Invalid" 2044 "Invalid" 2043 "Invalid" 2042 "Invalid" 2041 "Invalid" 2040 "Invalid" 2039 "Invalid" 2038 "Invalid" 2037 "Invalid" 2036 "Invalid" 2035 "Invalid" 2034 "Invalid" 2033 "Invalid" 2032 "Invalid" 2031 "Invalid" 2030 "Invalid" 2029 "Invalid" 2028 "Invalid" 2027 "Invalid" 2026 "Invalid" 2025 "Invalid" 2024 "Invalid" 2023 "Invalid" 2022 "Invalid" 2021 "Invalid" 2020 "Invalid" 2019 "Invalid" 2018 "Invalid" 2017 "Invalid" 2016 "Invalid" 2015 "Invalid" 2014 "Invalid" 2013 "Invalid" 2012 "Invalid" 2011 "Invalid" 2010 "Invalid" 2009 "Invalid" 2008 "Invalid" 2007 "Invalid" 2006 "Invalid" 2005 "Invalid" 2004 "Invalid" 2003 "Invalid" 2002 "Invalid" 2001 "Invalid" 2000 "Invalid" 1999 "Invalid" 1998 "Invalid" 1997 "Invalid" 1996 "Invalid" 1995 "Invalid" 1994 "Invalid" 1993 "Invalid" 1992 "Invalid" 1991 "Invalid" 1990 "Invalid" 1989 "Invalid" 1988 "Invalid" 1987 "Invalid" 1986 "Invalid" 1985 "Invalid" 1984 "Invalid" 1983 "Invalid" 1982 "Invalid" 1981 "Invalid" 1980 "Invalid" 1979 "Invalid" 1978 "Invalid" 1977 "Invalid" 1976 "Invalid" 1975 "Invalid" 1974 "Invalid" 1973 "Invalid" 1972 "Invalid" 1971 "Invalid" 1970 "Invalid" 1969 "Invalid" 1968 "Invalid" 1967 "Invalid" 1966 "Invalid" 1965 "Invalid" 1964 "Invalid" 1963 "Invalid" 1962 "Invalid" 1961 "Invalid" 1960 "Invalid" 1959 "Invalid" 1958 "Invalid" 1957 "Invalid" 1956 "Invalid" 1955 "Invalid" 1954 "Invalid" 1953 "Invalid" 1952 "Invalid" 1951 "Invalid" 1950 "Invalid" 1949 "Invalid" 1948 "Invalid" 1947 "Invalid" 1946 "Invalid" 1945 "Invalid" 1944 "Invalid" 1943 "Invalid" 1942 "Invalid" 1941 "Invalid" 1940 "Invalid" 1939 "Invalid" 1938 "Invalid" 1937 "Invalid" 1936 "Invalid" 1935 "Invalid" 1934 "Invalid" 1933 "Invalid" 1932 "Invalid" 1931 "Invalid" 1930 "Invalid" 1929 "Invalid" 1928 "Invalid" 1927 "Invalid" 1926 "Invalid" 1925 "Invalid" 1924 "Invalid" 1923 "Invalid" 1922 "Invalid" 1921 "Invalid" 1920 "Invalid" 1919 "Invalid" 1918 "Invalid" 1917 "Invalid" 1916 "Invalid" 1915 "Invalid" 1914 "Invalid" 1913 "Invalid" 1912 "Invalid" 1911 "Invalid" 1910 "Invalid" 1909 "Invalid" 1908 "Invalid" 1907 "Invalid" 1906 "Invalid" 1905 "Invalid" 1904 "Invalid" 1903 "Invalid" 1902 "Invalid" 1901 "Invalid" 1900 "Invalid" 1899 "Invalid" 1898 "Invalid" 1897 "Invalid" 1896 "Invalid" 1895 "Invalid" 1894 "Invalid" 1893 "Invalid" 1892 "Invalid" 1891 "Invalid" 1890 "Invalid" 1889 "Invalid" 1888 "Invalid" 1887 "Invalid" 1886 "Invalid" 1885 "Invalid" 1884 "Invalid" 1883 "Invalid" 1882 "Invalid" 1881 "Invalid" 1880 "Invalid" 1879 "Invalid" 1878 "Invalid" 1877 "Invalid" 1876 "Invalid" 1875 "Invalid" 1874 "Invalid" 1873 "Invalid" 1872 "Invalid" 1871 "Invalid" 1870 "Invalid" 1869 "Invalid" 1868 "Invalid" 1867 "Invalid" 1866 "Invalid" 1865 "Invalid" 1864 "Invalid" 1863 "Invalid" 1862 "Invalid" 1861 "Invalid" 1860 "Invalid" 1859 "Invalid" 1858 "Invalid" 1857 "Invalid" 1856 "Invalid" 1855 "Invalid" 1854 "Invalid" 1853 "Invalid" 1852 "Invalid" 1851 "Invalid" 1850 "Invalid" 1849 "Invalid" 1848 "Invalid" 1847 "Invalid" 1846 "Invalid" 1845 "Invalid" 1844 "Invalid" 1843 "Invalid" 1842 "Invalid" 1841 "Invalid" 1840 "Invalid" 1839 "Invalid" 1838 "Invalid" 1837 "Invalid" 1836 "Invalid" 1835 "Invalid" 1834 "Invalid" 1833 "Invalid" 1832 "Invalid" 1831 "Invalid" 1830 "Invalid" 1829 "Invalid" 1828 "Invalid" 1827 "Invalid" 1826 "Invalid" 1825 "Invalid" 1824 "Invalid" 1823 "Invalid" 1822 "Invalid" 1821 "Invalid" 1820 "Invalid" 1819 "Invalid" 1818 "Invalid" 1817 "Invalid" 1816 "Invalid" 1815 "Invalid" 1814 "Invalid" 1813 "Invalid" 1812 "Invalid" 1811 "Invalid" 1810 "Invalid" 1809 "Invalid" 1808 "Invalid" 1807 "Invalid" 1806 "Invalid" 1805 "Invalid" 1804 "Invalid" 1803 "Invalid" 1802 "Invalid" 1801 "Invalid" ;
VAL_ 551 BCU_CellVlt023_RM 2047 "Invalid" 2046 "Invalid" 2045 "Invalid" 2044 "Invalid" 2043 "Invalid" 2042 "Invalid" 2041 "Invalid" 2040 "Invalid" 2039 "Invalid" 2038 "Invalid" 2037 "Invalid" 2036 "Invalid" 2035 "Invalid" 2034 "Invalid" 2033 "Invalid" 2032 "Invalid" 2031 "Invalid" 2030 "Invalid" 2029 "Invalid" 2028 "Invalid" 2027 "Invalid" 2026 "Invalid" 2025 "Invalid" 2024 "Invalid" 2023 "Invalid" 2022 "Invalid" 2021 "Invalid" 2020 "Invalid" 2019 "Invalid" 2018 "Invalid" 2017 "Invalid" 2016 "Invalid" 2015 "Invalid" 2014 "Invalid" 2013 "Invalid" 2012 "Invalid" 2011 "Invalid" 2010 "Invalid" 2009 "Invalid" 2008 "Invalid" 2007 "Invalid" 2006 "Invalid" 2005 "Invalid" 2004 "Invalid" 2003 "Invalid" 2002 "Invalid" 2001 "Invalid" 2000 "Invalid" 1999 "Invalid" 1998 "Invalid" 1997 "Invalid" 1996 "Invalid" 1995 "Invalid" 1994 "Invalid" 1993 "Invalid" 1992 "Invalid" 1991 "Invalid" 1990 "Invalid" 1989 "Invalid" 1988 "Invalid" 1987 "Invalid" 1986 "Invalid" 1985 "Invalid" 1984 "Invalid" 1983 "Invalid" 1982 "Invalid" 1981 "Invalid" 1980 "Invalid" 1979 "Invalid" 1978 "Invalid" 1977 "Invalid" 1976 "Invalid" 1975 "Invalid" 1974 "Invalid" 1973 "Invalid" 1972 "Invalid" 1971 "Invalid" 1970 "Invalid" 1969 "Invalid" 1968 "Invalid" 1967 "Invalid" 1966 "Invalid" 1965 "Invalid" 1964 "Invalid" 1963 "Invalid" 1962 "Invalid" 1961 "Invalid" 1960 "Invalid" 1959 "Invalid" 1958 "Invalid" 1957 "Invalid" 1956 "Invalid" 1955 "Invalid" 1954 "Invalid" 1953 "Invalid" 1952 "Invalid" 1951 "Invalid" 1950 "Invalid" 1949 "Invalid" 1948 "Invalid" 1947 "Invalid" 1946 "Invalid" 1945 "Invalid" 1944 "Invalid" 1943 "Invalid" 1942 "Invalid" 1941 "Invalid" 1940 "Invalid" 1939 "Invalid" 1938 "Invalid" 1937 "Invalid" 1936 "Invalid" 1935 "Invalid" 1934 "Invalid" 1933 "Invalid" 1932 "Invalid" 1931 "Invalid" 1930 "Invalid" 1929 "Invalid" 1928 "Invalid" 1927 "Invalid" 1926 "Invalid" 1925 "Invalid" 1924 "Invalid" 1923 "Invalid" 1922 "Invalid" 1921 "Invalid" 1920 "Invalid" 1919 "Invalid" 1918 "Invalid" 1917 "Invalid" 1916 "Invalid" 1915 "Invalid" 1914 "Invalid" 1913 "Invalid" 1912 "Invalid" 1911 "Invalid" 1910 "Invalid" 1909 "Invalid" 1908 "Invalid" 1907 "Invalid" 1906 "Invalid" 1905 "Invalid" 1904 "Invalid" 1903 "Invalid" 1902 "Invalid" 1901 "Invalid" 1900 "Invalid" 1899 "Invalid" 1898 "Invalid" 1897 "Invalid" 1896 "Invalid" 1895 "Invalid" 1894 "Invalid" 1893 "Invalid" 1892 "Invalid" 1891 "Invalid" 1890 "Invalid" 1889 "Invalid" 1888 "Invalid" 1887 "Invalid" 1886 "Invalid" 1885 "Invalid" 1884 "Invalid" 1883 "Invalid" 1882 "Invalid" 1881 "Invalid" 1880 "Invalid" 1879 "Invalid" 1878 "Invalid" 1877 "Invalid" 1876 "Invalid" 1875 "Invalid" 1874 "Invalid" 1873 "Invalid" 1872 "Invalid" 1871 "Invalid" 1870 "Invalid" 1869 "Invalid" 1868 "Invalid" 1867 "Invalid" 1866 "Invalid" 1865 "Invalid" 1864 "Invalid" 1863 "Invalid" 1862 "Invalid" 1861 "Invalid" 1860 "Invalid" 1859 "Invalid" 1858 "Invalid" 1857 "Invalid" 1856 "Invalid" 1855 "Invalid" 1854 "Invalid" 1853 "Invalid" 1852 "Invalid" 1851 "Invalid" 1850 "Invalid" 1849 "Invalid" 1848 "Invalid" 1847 "Invalid" 1846 "Invalid" 1845 "Invalid" 1844 "Invalid" 1843 "Invalid" 1842 "Invalid" 1841 "Invalid" 1840 "Invalid" 1839 "Invalid" 1838 "Invalid" 1837 "Invalid" 1836 "Invalid" 1835 "Invalid" 1834 "Invalid" 1833 "Invalid" 1832 "Invalid" 1831 "Invalid" 1830 "Invalid" 1829 "Invalid" 1828 "Invalid" 1827 "Invalid" 1826 "Invalid" 1825 "Invalid" 1824 "Invalid" 1823 "Invalid" 1822 "Invalid" 1821 "Invalid" 1820 "Invalid" 1819 "Invalid" 1818 "Invalid" 1817 "Invalid" 1816 "Invalid" 1815 "Invalid" 1814 "Invalid" 1813 "Invalid" 1812 "Invalid" 1811 "Invalid" 1810 "Invalid" 1809 "Invalid" 1808 "Invalid" 1807 "Invalid" 1806 "Invalid" 1805 "Invalid" 1804 "Invalid" 1803 "Invalid" 1802 "Invalid" 1801 "Invalid" ;
VAL_ 551 BCU_CellVlt024_RM 2047 "Invalid" 2046 "Invalid" 2045 "Invalid" 2044 "Invalid" 2043 "Invalid" 2042 "Invalid" 2041 "Invalid" 2040 "Invalid" 2039 "Invalid" 2038 "Invalid" 2037 "Invalid" 2036 "Invalid" 2035 "Invalid" 2034 "Invalid" 2033 "Invalid" 2032 "Invalid" 2031 "Invalid" 2030 "Invalid" 2029 "Invalid" 2028 "Invalid" 2027 "Invalid" 2026 "Invalid" 2025 "Invalid" 2024 "Invalid" 2023 "Invalid" 2022 "Invalid" 2021 "Invalid" 2020 "Invalid" 2019 "Invalid" 2018 "Invalid" 2017 "Invalid" 2016 "Invalid" 2015 "Invalid" 2014 "Invalid" 2013 "Invalid" 2012 "Invalid" 2011 "Invalid" 2010 "Invalid" 2009 "Invalid" 2008 "Invalid" 2007 "Invalid" 2006 "Invalid" 2005 "Invalid" 2004 "Invalid" 2003 "Invalid" 2002 "Invalid" 2001 "Invalid" 2000 "Invalid" 1999 "Invalid" 1998 "Invalid" 1997 "Invalid" 1996 "Invalid" 1995 "Invalid" 1994 "Invalid" 1993 "Invalid" 1992 "Invalid" 1991 "Invalid" 1990 "Invalid" 1989 "Invalid" 1988 "Invalid" 1987 "Invalid" 1986 "Invalid" 1985 "Invalid" 1984 "Invalid" 1983 "Invalid" 1982 "Invalid" 1981 "Invalid" 1980 "Invalid" 1979 "Invalid" 1978 "Invalid" 1977 "Invalid" 1976 "Invalid" 1975 "Invalid" 1974 "Invalid" 1973 "Invalid" 1972 "Invalid" 1971 "Invalid" 1970 "Invalid" 1969 "Invalid" 1968 "Invalid" 1967 "Invalid" 1966 "Invalid" 1965 "Invalid" 1964 "Invalid" 1963 "Invalid" 1962 "Invalid" 1961 "Invalid" 1960 "Invalid" 1959 "Invalid" 1958 "Invalid" 1957 "Invalid" 1956 "Invalid" 1955 "Invalid" 1954 "Invalid" 1953 "Invalid" 1952 "Invalid" 1951 "Invalid" 1950 "Invalid" 1949 "Invalid" 1948 "Invalid" 1947 "Invalid" 1946 "Invalid" 1945 "Invalid" 1944 "Invalid" 1943 "Invalid" 1942 "Invalid" 1941 "Invalid" 1940 "Invalid" 1939 "Invalid" 1938 "Invalid" 1937 "Invalid" 1936 "Invalid" 1935 "Invalid" 1934 "Invalid" 1933 "Invalid" 1932 "Invalid" 1931 "Invalid" 1930 "Invalid" 1929 "Invalid" 1928 "Invalid" 1927 "Invalid" 1926 "Invalid" 1925 "Invalid" 1924 "Invalid" 1923 "Invalid" 1922 "Invalid" 1921 "Invalid" 1920 "Invalid" 1919 "Invalid" 1918 "Invalid" 1917 "Invalid" 1916 "Invalid" 1915 "Invalid" 1914 "Invalid" 1913 "Invalid" 1912 "Invalid" 1911 "Invalid" 1910 "Invalid" 1909 "Invalid" 1908 "Invalid" 1907 "Invalid" 1906 "Invalid" 1905 "Invalid" 1904 "Invalid" 1903 "Invalid" 1902 "Invalid" 1901 "Invalid" 1900 "Invalid" 1899 "Invalid" 1898 "Invalid" 1897 "Invalid" 1896 "Invalid" 1895 "Invalid" 1894 "Invalid" 1893 "Invalid" 1892 "Invalid" 1891 "Invalid" 1890 "Invalid" 1889 "Invalid" 1888 "Invalid" 1887 "Invalid" 1886 "Invalid" 1885 "Invalid" 1884 "Invalid" 1883 "Invalid" 1882 "Invalid" 1881 "Invalid" 1880 "Invalid" 1879 "Invalid" 1878 "Invalid" 1877 "Invalid" 1876 "Invalid" 1875 "Invalid" 1874 "Invalid" 1873 "Invalid" 1872 "Invalid" 1871 "Invalid" 1870 "Invalid" 1869 "Invalid" 1868 "Invalid" 1867 "Invalid" 1866 "Invalid" 1865 "Invalid" 1864 "Invalid" 1863 "Invalid" 1862 "Invalid" 1861 "Invalid" 1860 "Invalid" 1859 "Invalid" 1858 "Invalid" 1857 "Invalid" 1856 "Invalid" 1855 "Invalid" 1854 "Invalid" 1853 "Invalid" 1852 "Invalid" 1851 "Invalid" 1850 "Invalid" 1849 "Invalid" 1848 "Invalid" 1847 "Invalid" 1846 "Invalid" 1845 "Invalid" 1844 "Invalid" 1843 "Invalid" 1842 "Invalid" 1841 "Invalid" 1840 "Invalid" 1839 "Invalid" 1838 "Invalid" 1837 "Invalid" 1836 "Invalid" 1835 "Invalid" 1834 "Invalid" 1833 "Invalid" 1832 "Invalid" 1831 "Invalid" 1830 "Invalid" 1829 "Invalid" 1828 "Invalid" 1827 "Invalid" 1826 "Invalid" 1825 "Invalid" 1824 "Invalid" 1823 "Invalid" 1822 "Invalid" 1821 "Invalid" 1820 "Invalid" 1819 "Invalid" 1818 "Invalid" 1817 "Invalid" 1816 "Invalid" 1815 "Invalid" 1814 "Invalid" 1813 "Invalid" 1812 "Invalid" 1811 "Invalid" 1810 "Invalid" 1809 "Invalid" 1808 "Invalid" 1807 "Invalid" 1806 "Invalid" 1805 "Invalid" 1804 "Invalid" 1803 "Invalid" 1802 "Invalid" 1801 "Invalid" ;
VAL_ 551 BCU_CellVlt025_RM 2047 "Invalid" 2046 "Invalid" 2045 "Invalid" 2044 "Invalid" 2043 "Invalid" 2042 "Invalid" 2041 "Invalid" 2040 "Invalid" 2039 "Invalid" 2038 "Invalid" 2037 "Invalid" 2036 "Invalid" 2035 "Invalid" 2034 "Invalid" 2033 "Invalid" 2032 "Invalid" 2031 "Invalid" 2030 "Invalid" 2029 "Invalid" 2028 "Invalid" 2027 "Invalid" 2026 "Invalid" 2025 "Invalid" 2024 "Invalid" 2023 "Invalid" 2022 "Invalid" 2021 "Invalid" 2020 "Invalid" 2019 "Invalid" 2018 "Invalid" 2017 "Invalid" 2016 "Invalid" 2015 "Invalid" 2014 "Invalid" 2013 "Invalid" 2012 "Invalid" 2011 "Invalid" 2010 "Invalid" 2009 "Invalid" 2008 "Invalid" 2007 "Invalid" 2006 "Invalid" 2005 "Invalid" 2004 "Invalid" 2003 "Invalid" 2002 "Invalid" 2001 "Invalid" 2000 "Invalid" 1999 "Invalid" 1998 "Invalid" 1997 "Invalid" 1996 "Invalid" 1995 "Invalid" 1994 "Invalid" 1993 "Invalid" 1992 "Invalid" 1991 "Invalid" 1990 "Invalid" 1989 "Invalid" 1988 "Invalid" 1987 "Invalid" 1986 "Invalid" 1985 "Invalid" 1984 "Invalid" 1983 "Invalid" 1982 "Invalid" 1981 "Invalid" 1980 "Invalid" 1979 "Invalid" 1978 "Invalid" 1977 "Invalid" 1976 "Invalid" 1975 "Invalid" 1974 "Invalid" 1973 "Invalid" 1972 "Invalid" 1971 "Invalid" 1970 "Invalid" 1969 "Invalid" 1968 "Invalid" 1967 "Invalid" 1966 "Invalid" 1965 "Invalid" 1964 "Invalid" 1963 "Invalid" 1962 "Invalid" 1961 "Invalid" 1960 "Invalid" 1959 "Invalid" 1958 "Invalid" 1957 "Invalid" 1956 "Invalid" 1955 "Invalid" 1954 "Invalid" 1953 "Invalid" 1952 "Invalid" 1951 "Invalid" 1950 "Invalid" 1949 "Invalid" 1948 "Invalid" 1947 "Invalid" 1946 "Invalid" 1945 "Invalid" 1944 "Invalid" 1943 "Invalid" 1942 "Invalid" 1941 "Invalid" 1940 "Invalid" 1939 "Invalid" 1938 "Invalid" 1937 "Invalid" 1936 "Invalid" 1935 "Invalid" 1934 "Invalid" 1933 "Invalid" 1932 "Invalid" 1931 "Invalid" 1930 "Invalid" 1929 "Invalid" 1928 "Invalid" 1927 "Invalid" 1926 "Invalid" 1925 "Invalid" 1924 "Invalid" 1923 "Invalid" 1922 "Invalid" 1921 "Invalid" 1920 "Invalid" 1919 "Invalid" 1918 "Invalid" 1917 "Invalid" 1916 "Invalid" 1915 "Invalid" 1914 "Invalid" 1913 "Invalid" 1912 "Invalid" 1911 "Invalid" 1910 "Invalid" 1909 "Invalid" 1908 "Invalid" 1907 "Invalid" 1906 "Invalid" 1905 "Invalid" 1904 "Invalid" 1903 "Invalid" 1902 "Invalid" 1901 "Invalid" 1900 "Invalid" 1899 "Invalid" 1898 "Invalid" 1897 "Invalid" 1896 "Invalid" 1895 "Invalid" 1894 "Invalid" 1893 "Invalid" 1892 "Invalid" 1891 "Invalid" 1890 "Invalid" 1889 "Invalid" 1888 "Invalid" 1887 "Invalid" 1886 "Invalid" 1885 "Invalid" 1884 "Invalid" 1883 "Invalid" 1882 "Invalid" 1881 "Invalid" 1880 "Invalid" 1879 "Invalid" 1878 "Invalid" 1877 "Invalid" 1876 "Invalid" 1875 "Invalid" 1874 "Invalid" 1873 "Invalid" 1872 "Invalid" 1871 "Invalid" 1870 "Invalid" 1869 "Invalid" 1868 "Invalid" 1867 "Invalid" 1866 "Invalid" 1865 "Invalid" 1864 "Invalid" 1863 "Invalid" 1862 "Invalid" 1861 "Invalid" 1860 "Invalid" 1859 "Invalid" 1858 "Invalid" 1857 "Invalid" 1856 "Invalid" 1855 "Invalid" 1854 "Invalid" 1853 "Invalid" 1852 "Invalid" 1851 "Invalid" 1850 "Invalid" 1849 "Invalid" 1848 "Invalid" 1847 "Invalid" 1846 "Invalid" 1845 "Invalid" 1844 "Invalid" 1843 "Invalid" 1842 "Invalid" 1841 "Invalid" 1840 "Invalid" 1839 "Invalid" 1838 "Invalid" 1837 "Invalid" 1836 "Invalid" 1835 "Invalid" 1834 "Invalid" 1833 "Invalid" 1832 "Invalid" 1831 "Invalid" 1830 "Invalid" 1829 "Invalid" 1828 "Invalid" 1827 "Invalid" 1826 "Invalid" 1825 "Invalid" 1824 "Invalid" 1823 "Invalid" 1822 "Invalid" 1821 "Invalid" 1820 "Invalid" 1819 "Invalid" 1818 "Invalid" 1817 "Invalid" 1816 "Invalid" 1815 "Invalid" 1814 "Invalid" 1813 "Invalid" 1812 "Invalid" 1811 "Invalid" 1810 "Invalid" 1809 "Invalid" 1808 "Invalid" 1807 "Invalid" 1806 "Invalid" 1805 "Invalid" 1804 "Invalid" 1803 "Invalid" 1802 "Invalid" 1801 "Invalid" ;
VAL_ 551 BCU_CellTmp005_RM 255 "Invalid" 254 "Invalid" 253 "Invalid" 252 "Invalid" 251 "Invalid" 250 "Invalid" 249 "Invalid" 248 "Invalid" 247 "Invalid" 246 "Invalid" 245 "Invalid" 244 "Invalid" 243 "Invalid" 242 "Invalid" 241 "Invalid" 240 "Invalid" 239 "Invalid" 238 "Invalid" 237 "Invalid" 236 "Invalid" 235 "Invalid" 234 "Invalid" 233 "Invalid" 232 "Invalid" 231 "Invalid" 230 "Invalid" 229 "Invalid" 228 "Invalid" 227 "Invalid" 226 "Invalid" 225 "Invalid" 224 "Invalid" 223 "Invalid" 222 "Invalid" 221 "Invalid" 220 "Invalid" 219 "Invalid" 218 "Invalid" 217 "Invalid" 216 "Invalid" 215 "Invalid" 214 "Invalid" 213 "Invalid" 212 "Invalid" 211 "Invalid" 210 "Invalid" 209 "Invalid" 208 "Invalid" 207 "Invalid" 206 "Invalid" 205 "Invalid" 204 "Invalid" 203 "Invalid" 202 "Invalid" 201 "Invalid" 200 "Invalid" 199 "Invalid" 198 "Invalid" 197 "Invalid" 196 "Invalid" 195 "Invalid" 194 "Invalid" 193 "Invalid" 192 "Invalid" 191 "Invalid" 190 "Invalid" 189 "Invalid" 188 "Invalid" 187 "Invalid" 186 "Invalid" 185 "Invalid" 184 "Invalid" 183 "Invalid" 182 "Invalid" 181 "Invalid" 180 "Invalid" 179 "Invalid" 178 "Invalid" 177 "Invalid" 176 "Invalid" 175 "Invalid" 174 "Invalid" 173 "Invalid" 172 "Invalid" 171 "Invalid" 170 "Invalid" 169 "Invalid" 168 "Invalid" 167 "Invalid" 166 "Invalid" 165 "Invalid" 164 "Invalid" 163 "Invalid" 162 "Invalid" 161 "Invalid" ;
VAL_ 552 BCU_CellVlt026_RM 2047 "Invalid" 2046 "Invalid" 2045 "Invalid" 2044 "Invalid" 2043 "Invalid" 2042 "Invalid" 2041 "Invalid" 2040 "Invalid" 2039 "Invalid" 2038 "Invalid" 2037 "Invalid" 2036 "Invalid" 2035 "Invalid" 2034 "Invalid" 2033 "Invalid" 2032 "Invalid" 2031 "Invalid" 2030 "Invalid" 2029 "Invalid" 2028 "Invalid" 2027 "Invalid" 2026 "Invalid" 2025 "Invalid" 2024 "Invalid" 2023 "Invalid" 2022 "Invalid" 2021 "Invalid" 2020 "Invalid" 2019 "Invalid" 2018 "Invalid" 2017 "Invalid" 2016 "Invalid" 2015 "Invalid" 2014 "Invalid" 2013 "Invalid" 2012 "Invalid" 2011 "Invalid" 2010 "Invalid" 2009 "Invalid" 2008 "Invalid" 2007 "Invalid" 2006 "Invalid" 2005 "Invalid" 2004 "Invalid" 2003 "Invalid" 2002 "Invalid" 2001 "Invalid" 2000 "Invalid" 1999 "Invalid" 1998 "Invalid" 1997 "Invalid" 1996 "Invalid" 1995 "Invalid" 1994 "Invalid" 1993 "Invalid" 1992 "Invalid" 1991 "Invalid" 1990 "Invalid" 1989 "Invalid" 1988 "Invalid" 1987 "Invalid" 1986 "Invalid" 1985 "Invalid" 1984 "Invalid" 1983 "Invalid" 1982 "Invalid" 1981 "Invalid" 1980 "Invalid" 1979 "Invalid" 1978 "Invalid" 1977 "Invalid" 1976 "Invalid" 1975 "Invalid" 1974 "Invalid" 1973 "Invalid" 1972 "Invalid" 1971 "Invalid" 1970 "Invalid" 1969 "Invalid" 1968 "Invalid" 1967 "Invalid" 1966 "Invalid" 1965 "Invalid" 1964 "Invalid" 1963 "Invalid" 1962 "Invalid" 1961 "Invalid" 1960 "Invalid" 1959 "Invalid" 1958 "Invalid" 1957 "Invalid" 1956 "Invalid" 1955 "Invalid" 1954 "Invalid" 1953 "Invalid" 1952 "Invalid" 1951 "Invalid" 1950 "Invalid" 1949 "Invalid" 1948 "Invalid" 1947 "Invalid" 1946 "Invalid" 1945 "Invalid" 1944 "Invalid" 1943 "Invalid" 1942 "Invalid" 1941 "Invalid" 1940 "Invalid" 1939 "Invalid" 1938 "Invalid" 1937 "Invalid" 1936 "Invalid" 1935 "Invalid" 1934 "Invalid" 1933 "Invalid" 1932 "Invalid" 1931 "Invalid" 1930 "Invalid" 1929 "Invalid" 1928 "Invalid" 1927 "Invalid" 1926 "Invalid" 1925 "Invalid" 1924 "Invalid" 1923 "Invalid" 1922 "Invalid" 1921 "Invalid" 1920 "Invalid" 1919 "Invalid" 1918 "Invalid" 1917 "Invalid" 1916 "Invalid" 1915 "Invalid" 1914 "Invalid" 1913 "Invalid" 1912 "Invalid" 1911 "Invalid" 1910 "Invalid" 1909 "Invalid" 1908 "Invalid" 1907 "Invalid" 1906 "Invalid" 1905 "Invalid" 1904 "Invalid" 1903 "Invalid" 1902 "Invalid" 1901 "Invalid" 1900 "Invalid" 1899 "Invalid" 1898 "Invalid" 1897 "Invalid" 1896 "Invalid" 1895 "Invalid" 1894 "Invalid" 1893 "Invalid" 1892 "Invalid" 1891 "Invalid" 1890 "Invalid" 1889 "Invalid" 1888 "Invalid" 1887 "Invalid" 1886 "Invalid" 1885 "Invalid" 1884 "Invalid" 1883 "Invalid" 1882 "Invalid" 1881 "Invalid" 1880 "Invalid" 1879 "Invalid" 1878 "Invalid" 1877 "Invalid" 1876 "Invalid" 1875 "Invalid" 1874 "Invalid" 1873 "Invalid" 1872 "Invalid" 1871 "Invalid" 1870 "Invalid" 1869 "Invalid" 1868 "Invalid" 1867 "Invalid" 1866 "Invalid" 1865 "Invalid" 1864 "Invalid" 1863 "Invalid" 1862 "Invalid" 1861 "Invalid" 1860 "Invalid" 1859 "Invalid" 1858 "Invalid" 1857 "Invalid" 1856 "Invalid" 1855 "Invalid" 1854 "Invalid" 1853 "Invalid" 1852 "Invalid" 1851 "Invalid" 1850 "Invalid" 1849 "Invalid" 1848 "Invalid" 1847 "Invalid" 1846 "Invalid" 1845 "Invalid" 1844 "Invalid" 1843 "Invalid" 1842 "Invalid" 1841 "Invalid" 1840 "Invalid" 1839 "Invalid" 1838 "Invalid" 1837 "Invalid" 1836 "Invalid" 1835 "Invalid" 1834 "Invalid" 1833 "Invalid" 1832 "Invalid" 1831 "Invalid" 1830 "Invalid" 1829 "Invalid" 1828 "Invalid" 1827 "Invalid" 1826 "Invalid" 1825 "Invalid" 1824 "Invalid" 1823 "Invalid" 1822 "Invalid" 1821 "Invalid" 1820 "Invalid" 1819 "Invalid" 1818 "Invalid" 1817 "Invalid" 1816 "Invalid" 1815 "Invalid" 1814 "Invalid" 1813 "Invalid" 1812 "Invalid" 1811 "Invalid" 1810 "Invalid" 1809 "Invalid" 1808 "Invalid" 1807 "Invalid" 1806 "Invalid" 1805 "Invalid" 1804 "Invalid" 1803 "Invalid" 1802 "Invalid" 1801 "Invalid" ;
VAL_ 552 BCU_CellVlt027_RM 2047 "Invalid" 2046 "Invalid" 2045 "Invalid" 2044 "Invalid" 2043 "Invalid" 2042 "Invalid" 2041 "Invalid" 2040 "Invalid" 2039 "Invalid" 2038 "Invalid" 2037 "Invalid" 2036 "Invalid" 2035 "Invalid" 2034 "Invalid" 2033 "Invalid" 2032 "Invalid" 2031 "Invalid" 2030 "Invalid" 2029 "Invalid" 2028 "Invalid" 2027 "Invalid" 2026 "Invalid" 2025 "Invalid" 2024 "Invalid" 2023 "Invalid" 2022 "Invalid" 2021 "Invalid" 2020 "Invalid" 2019 "Invalid" 2018 "Invalid" 2017 "Invalid" 2016 "Invalid" 2015 "Invalid" 2014 "Invalid" 2013 "Invalid" 2012 "Invalid" 2011 "Invalid" 2010 "Invalid" 2009 "Invalid" 2008 "Invalid" 2007 "Invalid" 2006 "Invalid" 2005 "Invalid" 2004 "Invalid" 2003 "Invalid" 2002 "Invalid" 2001 "Invalid" 2000 "Invalid" 1999 "Invalid" 1998 "Invalid" 1997 "Invalid" 1996 "Invalid" 1995 "Invalid" 1994 "Invalid" 1993 "Invalid" 1992 "Invalid" 1991 "Invalid" 1990 "Invalid" 1989 "Invalid" 1988 "Invalid" 1987 "Invalid" 1986 "Invalid" 1985 "Invalid" 1984 "Invalid" 1983 "Invalid" 1982 "Invalid" 1981 "Invalid" 1980 "Invalid" 1979 "Invalid" 1978 "Invalid" 1977 "Invalid" 1976 "Invalid" 1975 "Invalid" 1974 "Invalid" 1973 "Invalid" 1972 "Invalid" 1971 "Invalid" 1970 "Invalid" 1969 "Invalid" 1968 "Invalid" 1967 "Invalid" 1966 "Invalid" 1965 "Invalid" 1964 "Invalid" 1963 "Invalid" 1962 "Invalid" 1961 "Invalid" 1960 "Invalid" 1959 "Invalid" 1958 "Invalid" 1957 "Invalid" 1956 "Invalid" 1955 "Invalid" 1954 "Invalid" 1953 "Invalid" 1952 "Invalid" 1951 "Invalid" 1950 "Invalid" 1949 "Invalid" 1948 "Invalid" 1947 "Invalid" 1946 "Invalid" 1945 "Invalid" 1944 "Invalid" 1943 "Invalid" 1942 "Invalid" 1941 "Invalid" 1940 "Invalid" 1939 "Invalid" 1938 "Invalid" 1937 "Invalid" 1936 "Invalid" 1935 "Invalid" 1934 "Invalid" 1933 "Invalid" 1932 "Invalid" 1931 "Invalid" 1930 "Invalid" 1929 "Invalid" 1928 "Invalid" 1927 "Invalid" 1926 "Invalid" 1925 "Invalid" 1924 "Invalid" 1923 "Invalid" 1922 "Invalid" 1921 "Invalid" 1920 "Invalid" 1919 "Invalid" 1918 "Invalid" 1917 "Invalid" 1916 "Invalid" 1915 "Invalid" 1914 "Invalid" 1913 "Invalid" 1912 "Invalid" 1911 "Invalid" 1910 "Invalid" 1909 "Invalid" 1908 "Invalid" 1907 "Invalid" 1906 "Invalid" 1905 "Invalid" 1904 "Invalid" 1903 "Invalid" 1902 "Invalid" 1901 "Invalid" 1900 "Invalid" 1899 "Invalid" 1898 "Invalid" 1897 "Invalid" 1896 "Invalid" 1895 "Invalid" 1894 "Invalid" 1893 "Invalid" 1892 "Invalid" 1891 "Invalid" 1890 "Invalid" 1889 "Invalid" 1888 "Invalid" 1887 "Invalid" 1886 "Invalid" 1885 "Invalid" 1884 "Invalid" 1883 "Invalid" 1882 "Invalid" 1881 "Invalid" 1880 "Invalid" 1879 "Invalid" 1878 "Invalid" 1877 "Invalid" 1876 "Invalid" 1875 "Invalid" 1874 "Invalid" 1873 "Invalid" 1872 "Invalid" 1871 "Invalid" 1870 "Invalid" 1869 "Invalid" 1868 "Invalid" 1867 "Invalid" 1866 "Invalid" 1865 "Invalid" 1864 "Invalid" 1863 "Invalid" 1862 "Invalid" 1861 "Invalid" 1860 "Invalid" 1859 "Invalid" 1858 "Invalid" 1857 "Invalid" 1856 "Invalid" 1855 "Invalid" 1854 "Invalid" 1853 "Invalid" 1852 "Invalid" 1851 "Invalid" 1850 "Invalid" 1849 "Invalid" 1848 "Invalid" 1847 "Invalid" 1846 "Invalid" 1845 "Invalid" 1844 "Invalid" 1843 "Invalid" 1842 "Invalid" 1841 "Invalid" 1840 "Invalid" 1839 "Invalid" 1838 "Invalid" 1837 "Invalid" 1836 "Invalid" 1835 "Invalid" 1834 "Invalid" 1833 "Invalid" 1832 "Invalid" 1831 "Invalid" 1830 "Invalid" 1829 "Invalid" 1828 "Invalid" 1827 "Invalid" 1826 "Invalid" 1825 "Invalid" 1824 "Invalid" 1823 "Invalid" 1822 "Invalid" 1821 "Invalid" 1820 "Invalid" 1819 "Invalid" 1818 "Invalid" 1817 "Invalid" 1816 "Invalid" 1815 "Invalid" 1814 "Invalid" 1813 "Invalid" 1812 "Invalid" 1811 "Invalid" 1810 "Invalid" 1809 "Invalid" 1808 "Invalid" 1807 "Invalid" 1806 "Invalid" 1805 "Invalid" 1804 "Invalid" 1803 "Invalid" 1802 "Invalid" 1801 "Invalid" ;
VAL_ 552 BCU_CellVlt028_RM 2047 "Invalid" 2046 "Invalid" 2045 "Invalid" 2044 "Invalid" 2043 "Invalid" 2042 "Invalid" 2041 "Invalid" 2040 "Invalid" 2039 "Invalid" 2038 "Invalid" 2037 "Invalid" 2036 "Invalid" 2035 "Invalid" 2034 "Invalid" 2033 "Invalid" 2032 "Invalid" 2031 "Invalid" 2030 "Invalid" 2029 "Invalid" 2028 "Invalid" 2027 "Invalid" 2026 "Invalid" 2025 "Invalid" 2024 "Invalid" 2023 "Invalid" 2022 "Invalid" 2021 "Invalid" 2020 "Invalid" 2019 "Invalid" 2018 "Invalid" 2017 "Invalid" 2016 "Invalid" 2015 "Invalid" 2014 "Invalid" 2013 "Invalid" 2012 "Invalid" 2011 "Invalid" 2010 "Invalid" 2009 "Invalid" 2008 "Invalid" 2007 "Invalid" 2006 "Invalid" 2005 "Invalid" 2004 "Invalid" 2003 "Invalid" 2002 "Invalid" 2001 "Invalid" 2000 "Invalid" 1999 "Invalid" 1998 "Invalid" 1997 "Invalid" 1996 "Invalid" 1995 "Invalid" 1994 "Invalid" 1993 "Invalid" 1992 "Invalid" 1991 "Invalid" 1990 "Invalid" 1989 "Invalid" 1988 "Invalid" 1987 "Invalid" 1986 "Invalid" 1985 "Invalid" 1984 "Invalid" 1983 "Invalid" 1982 "Invalid" 1981 "Invalid" 1980 "Invalid" 1979 "Invalid" 1978 "Invalid" 1977 "Invalid" 1976 "Invalid" 1975 "Invalid" 1974 "Invalid" 1973 "Invalid" 1972 "Invalid" 1971 "Invalid" 1970 "Invalid" 1969 "Invalid" 1968 "Invalid" 1967 "Invalid" 1966 "Invalid" 1965 "Invalid" 1964 "Invalid" 1963 "Invalid" 1962 "Invalid" 1961 "Invalid" 1960 "Invalid" 1959 "Invalid" 1958 "Invalid" 1957 "Invalid" 1956 "Invalid" 1955 "Invalid" 1954 "Invalid" 1953 "Invalid" 1952 "Invalid" 1951 "Invalid" 1950 "Invalid" 1949 "Invalid" 1948 "Invalid" 1947 "Invalid" 1946 "Invalid" 1945 "Invalid" 1944 "Invalid" 1943 "Invalid" 1942 "Invalid" 1941 "Invalid" 1940 "Invalid" 1939 "Invalid" 1938 "Invalid" 1937 "Invalid" 1936 "Invalid" 1935 "Invalid" 1934 "Invalid" 1933 "Invalid" 1932 "Invalid" 1931 "Invalid" 1930 "Invalid" 1929 "Invalid" 1928 "Invalid" 1927 "Invalid" 1926 "Invalid" 1925 "Invalid" 1924 "Invalid" 1923 "Invalid" 1922 "Invalid" 1921 "Invalid" 1920 "Invalid" 1919 "Invalid" 1918 "Invalid" 1917 "Invalid" 1916 "Invalid" 1915 "Invalid" 1914 "Invalid" 1913 "Invalid" 1912 "Invalid" 1911 "Invalid" 1910 "Invalid" 1909 "Invalid" 1908 "Invalid" 1907 "Invalid" 1906 "Invalid" 1905 "Invalid" 1904 "Invalid" 1903 "Invalid" 1902 "Invalid" 1901 "Invalid" 1900 "Invalid" 1899 "Invalid" 1898 "Invalid" 1897 "Invalid" 1896 "Invalid" 1895 "Invalid" 1894 "Invalid" 1893 "Invalid" 1892 "Invalid" 1891 "Invalid" 1890 "Invalid" 1889 "Invalid" 1888 "Invalid" 1887 "Invalid" 1886 "Invalid" 1885 "Invalid" 1884 "Invalid" 1883 "Invalid" 1882 "Invalid" 1881 "Invalid" 1880 "Invalid" 1879 "Invalid" 1878 "Invalid" 1877 "Invalid" 1876 "Invalid" 1875 "Invalid" 1874 "Invalid" 1873 "Invalid" 1872 "Invalid" 1871 "Invalid" 1870 "Invalid" 1869 "Invalid" 1868 "Invalid" 1867 "Invalid" 1866 "Invalid" 1865 "Invalid" 1864 "Invalid" 1863 "Invalid" 1862 "Invalid" 1861 "Invalid" 1860 "Invalid" 1859 "Invalid" 1858 "Invalid" 1857 "Invalid" 1856 "Invalid" 1855 "Invalid" 1854 "Invalid" 1853 "Invalid" 1852 "Invalid" 1851 "Invalid" 1850 "Invalid" 1849 "Invalid" 1848 "Invalid" 1847 "Invalid" 1846 "Invalid" 1845 "Invalid" 1844 "Invalid" 1843 "Invalid" 1842 "Invalid" 1841 "Invalid" 1840 "Invalid" 1839 "Invalid" 1838 "Invalid" 1837 "Invalid" 1836 "Invalid" 1835 "Invalid" 1834 "Invalid" 1833 "Invalid" 1832 "Invalid" 1831 "Invalid" 1830 "Invalid" 1829 "Invalid" 1828 "Invalid" 1827 "Invalid" 1826 "Invalid" 1825 "Invalid" 1824 "Invalid" 1823 "Invalid" 1822 "Invalid" 1821 "Invalid" 1820 "Invalid" 1819 "Invalid" 1818 "Invalid" 1817 "Invalid" 1816 "Invalid" 1815 "Invalid" 1814 "Invalid" 1813 "Invalid" 1812 "Invalid" 1811 "Invalid" 1810 "Invalid" 1809 "Invalid" 1808 "Invalid" 1807 "Invalid" 1806 "Invalid" 1805 "Invalid" 1804 "Invalid" 1803 "Invalid" 1802 "Invalid" 1801 "Invalid" ;
VAL_ 552 BCU_CellVlt029_RM 2047 "Invalid" 2046 "Invalid" 2045 "Invalid" 2044 "Invalid" 2043 "Invalid" 2042 "Invalid" 2041 "Invalid" 2040 "Invalid" 2039 "Invalid" 2038 "Invalid" 2037 "Invalid" 2036 "Invalid" 2035 "Invalid" 2034 "Invalid" 2033 "Invalid" 2032 "Invalid" 2031 "Invalid" 2030 "Invalid" 2029 "Invalid" 2028 "Invalid" 2027 "Invalid" 2026 "Invalid" 2025 "Invalid" 2024 "Invalid" 2023 "Invalid" 2022 "Invalid" 2021 "Invalid" 2020 "Invalid" 2019 "Invalid" 2018 "Invalid" 2017 "Invalid" 2016 "Invalid" 2015 "Invalid" 2014 "Invalid" 2013 "Invalid" 2012 "Invalid" 2011 "Invalid" 2010 "Invalid" 2009 "Invalid" 2008 "Invalid" 2007 "Invalid" 2006 "Invalid" 2005 "Invalid" 2004 "Invalid" 2003 "Invalid" 2002 "Invalid" 2001 "Invalid" 2000 "Invalid" 1999 "Invalid" 1998 "Invalid" 1997 "Invalid" 1996 "Invalid" 1995 "Invalid" 1994 "Invalid" 1993 "Invalid" 1992 "Invalid" 1991 "Invalid" 1990 "Invalid" 1989 "Invalid" 1988 "Invalid" 1987 "Invalid" 1986 "Invalid" 1985 "Invalid" 1984 "Invalid" 1983 "Invalid" 1982 "Invalid" 1981 "Invalid" 1980 "Invalid" 1979 "Invalid" 1978 "Invalid" 1977 "Invalid" 1976 "Invalid" 1975 "Invalid" 1974 "Invalid" 1973 "Invalid" 1972 "Invalid" 1971 "Invalid" 1970 "Invalid" 1969 "Invalid" 1968 "Invalid" 1967 "Invalid" 1966 "Invalid" 1965 "Invalid" 1964 "Invalid" 1963 "Invalid" 1962 "Invalid" 1961 "Invalid" 1960 "Invalid" 1959 "Invalid" 1958 "Invalid" 1957 "Invalid" 1956 "Invalid" 1955 "Invalid" 1954 "Invalid" 1953 "Invalid" 1952 "Invalid" 1951 "Invalid" 1950 "Invalid" 1949 "Invalid" 1948 "Invalid" 1947 "Invalid" 1946 "Invalid" 1945 "Invalid" 1944 "Invalid" 1943 "Invalid" 1942 "Invalid" 1941 "Invalid" 1940 "Invalid" 1939 "Invalid" 1938 "Invalid" 1937 "Invalid" 1936 "Invalid" 1935 "Invalid" 1934 "Invalid" 1933 "Invalid" 1932 "Invalid" 1931 "Invalid" 1930 "Invalid" 1929 "Invalid" 1928 "Invalid" 1927 "Invalid" 1926 "Invalid" 1925 "Invalid" 1924 "Invalid" 1923 "Invalid" 1922 "Invalid" 1921 "Invalid" 1920 "Invalid" 1919 "Invalid" 1918 "Invalid" 1917 "Invalid" 1916 "Invalid" 1915 "Invalid" 1914 "Invalid" 1913 "Invalid" 1912 "Invalid" 1911 "Invalid" 1910 "Invalid" 1909 "Invalid" 1908 "Invalid" 1907 "Invalid" 1906 "Invalid" 1905 "Invalid" 1904 "Invalid" 1903 "Invalid" 1902 "Invalid" 1901 "Invalid" 1900 "Invalid" 1899 "Invalid" 1898 "Invalid" 1897 "Invalid" 1896 "Invalid" 1895 "Invalid" 1894 "Invalid" 1893 "Invalid" 1892 "Invalid" 1891 "Invalid" 1890 "Invalid" 1889 "Invalid" 1888 "Invalid" 1887 "Invalid" 1886 "Invalid" 1885 "Invalid" 1884 "Invalid" 1883 "Invalid" 1882 "Invalid" 1881 "Invalid" 1880 "Invalid" 1879 "Invalid" 1878 "Invalid" 1877 "Invalid" 1876 "Invalid" 1875 "Invalid" 1874 "Invalid" 1873 "Invalid" 1872 "Invalid" 1871 "Invalid" 1870 "Invalid" 1869 "Invalid" 1868 "Invalid" 1867 "Invalid" 1866 "Invalid" 1865 "Invalid" 1864 "Invalid" 1863 "Invalid" 1862 "Invalid" 1861 "Invalid" 1860 "Invalid" 1859 "Invalid" 1858 "Invalid" 1857 "Invalid" 1856 "Invalid" 1855 "Invalid" 1854 "Invalid" 1853 "Invalid" 1852 "Invalid" 1851 "Invalid" 1850 "Invalid" 1849 "Invalid" 1848 "Invalid" 1847 "Invalid" 1846 "Invalid" 1845 "Invalid" 1844 "Invalid" 1843 "Invalid" 1842 "Invalid" 1841 "Invalid" 1840 "Invalid" 1839 "Invalid" 1838 "Invalid" 1837 "Invalid" 1836 "Invalid" 1835 "Invalid" 1834 "Invalid" 1833 "Invalid" 1832 "Invalid" 1831 "Invalid" 1830 "Invalid" 1829 "Invalid" 1828 "Invalid" 1827 "Invalid" 1826 "Invalid" 1825 "Invalid" 1824 "Invalid" 1823 "Invalid" 1822 "Invalid" 1821 "Invalid" 1820 "Invalid" 1819 "Invalid" 1818 "Invalid" 1817 "Invalid" 1816 "Invalid" 1815 "Invalid" 1814 "Invalid" 1813 "Invalid" 1812 "Invalid" 1811 "Invalid" 1810 "Invalid" 1809 "Invalid" 1808 "Invalid" 1807 "Invalid" 1806 "Invalid" 1805 "Invalid" 1804 "Invalid" 1803 "Invalid" 1802 "Invalid" 1801 "Invalid" ;
VAL_ 552 BCU_CellVlt030_RM 2047 "Invalid" 2046 "Invalid" 2045 "Invalid" 2044 "Invalid" 2043 "Invalid" 2042 "Invalid" 2041 "Invalid" 2040 "Invalid" 2039 "Invalid" 2038 "Invalid" 2037 "Invalid" 2036 "Invalid" 2035 "Invalid" 2034 "Invalid" 2033 "Invalid" 2032 "Invalid" 2031 "Invalid" 2030 "Invalid" 2029 "Invalid" 2028 "Invalid" 2027 "Invalid" 2026 "Invalid" 2025 "Invalid" 2024 "Invalid" 2023 "Invalid" 2022 "Invalid" 2021 "Invalid" 2020 "Invalid" 2019 "Invalid" 2018 "Invalid" 2017 "Invalid" 2016 "Invalid" 2015 "Invalid" 2014 "Invalid" 2013 "Invalid" 2012 "Invalid" 2011 "Invalid" 2010 "Invalid" 2009 "Invalid" 2008 "Invalid" 2007 "Invalid" 2006 "Invalid" 2005 "Invalid" 2004 "Invalid" 2003 "Invalid" 2002 "Invalid" 2001 "Invalid" 2000 "Invalid" 1999 "Invalid" 1998 "Invalid" 1997 "Invalid" 1996 "Invalid" 1995 "Invalid" 1994 "Invalid" 1993 "Invalid" 1992 "Invalid" 1991 "Invalid" 1990 "Invalid" 1989 "Invalid" 1988 "Invalid" 1987 "Invalid" 1986 "Invalid" 1985 "Invalid" 1984 "Invalid" 1983 "Invalid" 1982 "Invalid" 1981 "Invalid" 1980 "Invalid" 1979 "Invalid" 1978 "Invalid" 1977 "Invalid" 1976 "Invalid" 1975 "Invalid" 1974 "Invalid" 1973 "Invalid" 1972 "Invalid" 1971 "Invalid" 1970 "Invalid" 1969 "Invalid" 1968 "Invalid" 1967 "Invalid" 1966 "Invalid" 1965 "Invalid" 1964 "Invalid" 1963 "Invalid" 1962 "Invalid" 1961 "Invalid" 1960 "Invalid" 1959 "Invalid" 1958 "Invalid" 1957 "Invalid" 1956 "Invalid" 1955 "Invalid" 1954 "Invalid" 1953 "Invalid" 1952 "Invalid" 1951 "Invalid" 1950 "Invalid" 1949 "Invalid" 1948 "Invalid" 1947 "Invalid" 1946 "Invalid" 1945 "Invalid" 1944 "Invalid" 1943 "Invalid" 1942 "Invalid" 1941 "Invalid" 1940 "Invalid" 1939 "Invalid" 1938 "Invalid" 1937 "Invalid" 1936 "Invalid" 1935 "Invalid" 1934 "Invalid" 1933 "Invalid" 1932 "Invalid" 1931 "Invalid" 1930 "Invalid" 1929 "Invalid" 1928 "Invalid" 1927 "Invalid" 1926 "Invalid" 1925 "Invalid" 1924 "Invalid" 1923 "Invalid" 1922 "Invalid" 1921 "Invalid" 1920 "Invalid" 1919 "Invalid" 1918 "Invalid" 1917 "Invalid" 1916 "Invalid" 1915 "Invalid" 1914 "Invalid" 1913 "Invalid" 1912 "Invalid" 1911 "Invalid" 1910 "Invalid" 1909 "Invalid" 1908 "Invalid" 1907 "Invalid" 1906 "Invalid" 1905 "Invalid" 1904 "Invalid" 1903 "Invalid" 1902 "Invalid" 1901 "Invalid" 1900 "Invalid" 1899 "Invalid" 1898 "Invalid" 1897 "Invalid" 1896 "Invalid" 1895 "Invalid" 1894 "Invalid" 1893 "Invalid" 1892 "Invalid" 1891 "Invalid" 1890 "Invalid" 1889 "Invalid" 1888 "Invalid" 1887 "Invalid" 1886 "Invalid" 1885 "Invalid" 1884 "Invalid" 1883 "Invalid" 1882 "Invalid" 1881 "Invalid" 1880 "Invalid" 1879 "Invalid" 1878 "Invalid" 1877 "Invalid" 1876 "Invalid" 1875 "Invalid" 1874 "Invalid" 1873 "Invalid" 1872 "Invalid" 1871 "Invalid" 1870 "Invalid" 1869 "Invalid" 1868 "Invalid" 1867 "Invalid" 1866 "Invalid" 1865 "Invalid" 1864 "Invalid" 1863 "Invalid" 1862 "Invalid" 1861 "Invalid" 1860 "Invalid" 1859 "Invalid" 1858 "Invalid" 1857 "Invalid" 1856 "Invalid" 1855 "Invalid" 1854 "Invalid" 1853 "Invalid" 1852 "Invalid" 1851 "Invalid" 1850 "Invalid" 1849 "Invalid" 1848 "Invalid" 1847 "Invalid" 1846 "Invalid" 1845 "Invalid" 1844 "Invalid" 1843 "Invalid" 1842 "Invalid" 1841 "Invalid" 1840 "Invalid" 1839 "Invalid" 1838 "Invalid" 1837 "Invalid" 1836 "Invalid" 1835 "Invalid" 1834 "Invalid" 1833 "Invalid" 1832 "Invalid" 1831 "Invalid" 1830 "Invalid" 1829 "Invalid" 1828 "Invalid" 1827 "Invalid" 1826 "Invalid" 1825 "Invalid" 1824 "Invalid" 1823 "Invalid" 1822 "Invalid" 1821 "Invalid" 1820 "Invalid" 1819 "Invalid" 1818 "Invalid" 1817 "Invalid" 1816 "Invalid" 1815 "Invalid" 1814 "Invalid" 1813 "Invalid" 1812 "Invalid" 1811 "Invalid" 1810 "Invalid" 1809 "Invalid" 1808 "Invalid" 1807 "Invalid" 1806 "Invalid" 1805 "Invalid" 1804 "Invalid" 1803 "Invalid" 1802 "Invalid" 1801 "Invalid" ;
VAL_ 552 BCU_CellTmp006_RM 255 "Invalid" 254 "Invalid" 253 "Invalid" 252 "Invalid" 251 "Invalid" 250 "Invalid" 249 "Invalid" 248 "Invalid" 247 "Invalid" 246 "Invalid" 245 "Invalid" 244 "Invalid" 243 "Invalid" 242 "Invalid" 241 "Invalid" 240 "Invalid" 239 "Invalid" 238 "Invalid" 237 "Invalid" 236 "Invalid" 235 "Invalid" 234 "Invalid" 233 "Invalid" 232 "Invalid" 231 "Invalid" 230 "Invalid" 229 "Invalid" 228 "Invalid" 227 "Invalid" 226 "Invalid" 225 "Invalid" 224 "Invalid" 223 "Invalid" 222 "Invalid" 221 "Invalid" 220 "Invalid" 219 "Invalid" 218 "Invalid" 217 "Invalid" 216 "Invalid" 215 "Invalid" 214 "Invalid" 213 "Invalid" 212 "Invalid" 211 "Invalid" 210 "Invalid" 209 "Invalid" 208 "Invalid" 207 "Invalid" 206 "Invalid" 205 "Invalid" 204 "Invalid" 203 "Invalid" 202 "Invalid" 201 "Invalid" 200 "Invalid" 199 "Invalid" 198 "Invalid" 197 "Invalid" 196 "Invalid" 195 "Invalid" 194 "Invalid" 193 "Invalid" 192 "Invalid" 191 "Invalid" 190 "Invalid" 189 "Invalid" 188 "Invalid" 187 "Invalid" 186 "Invalid" 185 "Invalid" 184 "Invalid" 183 "Invalid" 182 "Invalid" 181 "Invalid" 180 "Invalid" 179 "Invalid" 178 "Invalid" 177 "Invalid" 176 "Invalid" 175 "Invalid" 174 "Invalid" 173 "Invalid" 172 "Invalid" 171 "Invalid" 170 "Invalid" 169 "Invalid" 168 "Invalid" 167 "Invalid" 166 "Invalid" 165 "Invalid" 164 "Invalid" 163 "Invalid" 162 "Invalid" 161 "Invalid" ;
VAL_ 553 BCU_CellVlt031_RM 2047 "Invalid" 2046 "Invalid" 2045 "Invalid" 2044 "Invalid" 2043 "Invalid" 2042 "Invalid" 2041 "Invalid" 2040 "Invalid" 2039 "Invalid" 2038 "Invalid" 2037 "Invalid" 2036 "Invalid" 2035 "Invalid" 2034 "Invalid" 2033 "Invalid" 2032 "Invalid" 2031 "Invalid" 2030 "Invalid" 2029 "Invalid" 2028 "Invalid" 2027 "Invalid" 2026 "Invalid" 2025 "Invalid" 2024 "Invalid" 2023 "Invalid" 2022 "Invalid" 2021 "Invalid" 2020 "Invalid" 2019 "Invalid" 2018 "Invalid" 2017 "Invalid" 2016 "Invalid" 2015 "Invalid" 2014 "Invalid" 2013 "Invalid" 2012 "Invalid" 2011 "Invalid" 2010 "Invalid" 2009 "Invalid" 2008 "Invalid" 2007 "Invalid" 2006 "Invalid" 2005 "Invalid" 2004 "Invalid" 2003 "Invalid" 2002 "Invalid" 2001 "Invalid" 2000 "Invalid" 1999 "Invalid" 1998 "Invalid" 1997 "Invalid" 1996 "Invalid" 1995 "Invalid" 1994 "Invalid" 1993 "Invalid" 1992 "Invalid" 1991 "Invalid" 1990 "Invalid" 1989 "Invalid" 1988 "Invalid" 1987 "Invalid" 1986 "Invalid" 1985 "Invalid" 1984 "Invalid" 1983 "Invalid" 1982 "Invalid" 1981 "Invalid" 1980 "Invalid" 1979 "Invalid" 1978 "Invalid" 1977 "Invalid" 1976 "Invalid" 1975 "Invalid" 1974 "Invalid" 1973 "Invalid" 1972 "Invalid" 1971 "Invalid" 1970 "Invalid" 1969 "Invalid" 1968 "Invalid" 1967 "Invalid" 1966 "Invalid" 1965 "Invalid" 1964 "Invalid" 1963 "Invalid" 1962 "Invalid" 1961 "Invalid" 1960 "Invalid" 1959 "Invalid" 1958 "Invalid" 1957 "Invalid" 1956 "Invalid" 1955 "Invalid" 1954 "Invalid" 1953 "Invalid" 1952 "Invalid" 1951 "Invalid" 1950 "Invalid" 1949 "Invalid" 1948 "Invalid" 1947 "Invalid" 1946 "Invalid" 1945 "Invalid" 1944 "Invalid" 1943 "Invalid" 1942 "Invalid" 1941 "Invalid" 1940 "Invalid" 1939 "Invalid" 1938 "Invalid" 1937 "Invalid" 1936 "Invalid" 1935 "Invalid" 1934 "Invalid" 1933 "Invalid" 1932 "Invalid" 1931 "Invalid" 1930 "Invalid" 1929 "Invalid" 1928 "Invalid" 1927 "Invalid" 1926 "Invalid" 1925 "Invalid" 1924 "Invalid" 1923 "Invalid" 1922 "Invalid" 1921 "Invalid" 1920 "Invalid" 1919 "Invalid" 1918 "Invalid" 1917 "Invalid" 1916 "Invalid" 1915 "Invalid" 1914 "Invalid" 1913 "Invalid" 1912 "Invalid" 1911 "Invalid" 1910 "Invalid" 1909 "Invalid" 1908 "Invalid" 1907 "Invalid" 1906 "Invalid" 1905 "Invalid" 1904 "Invalid" 1903 "Invalid" 1902 "Invalid" 1901 "Invalid" 1900 "Invalid" 1899 "Invalid" 1898 "Invalid" 1897 "Invalid" 1896 "Invalid" 1895 "Invalid" 1894 "Invalid" 1893 "Invalid" 1892 "Invalid" 1891 "Invalid" 1890 "Invalid" 1889 "Invalid" 1888 "Invalid" 1887 "Invalid" 1886 "Invalid" 1885 "Invalid" 1884 "Invalid" 1883 "Invalid" 1882 "Invalid" 1881 "Invalid" 1880 "Invalid" 1879 "Invalid" 1878 "Invalid" 1877 "Invalid" 1876 "Invalid" 1875 "Invalid" 1874 "Invalid" 1873 "Invalid" 1872 "Invalid" 1871 "Invalid" 1870 "Invalid" 1869 "Invalid" 1868 "Invalid" 1867 "Invalid" 1866 "Invalid" 1865 "Invalid" 1864 "Invalid" 1863 "Invalid" 1862 "Invalid" 1861 "Invalid" 1860 "Invalid" 1859 "Invalid" 1858 "Invalid" 1857 "Invalid" 1856 "Invalid" 1855 "Invalid" 1854 "Invalid" 1853 "Invalid" 1852 "Invalid" 1851 "Invalid" 1850 "Invalid" 1849 "Invalid" 1848 "Invalid" 1847 "Invalid" 1846 "Invalid" 1845 "Invalid" 1844 "Invalid" 1843 "Invalid" 1842 "Invalid" 1841 "Invalid" 1840 "Invalid" 1839 "Invalid" 1838 "Invalid" 1837 "Invalid" 1836 "Invalid" 1835 "Invalid" 1834 "Invalid" 1833 "Invalid" 1832 "Invalid" 1831 "Invalid" 1830 "Invalid" 1829 "Invalid" 1828 "Invalid" 1827 "Invalid" 1826 "Invalid" 1825 "Invalid" 1824 "Invalid" 1823 "Invalid" 1822 "Invalid" 1821 "Invalid" 1820 "Invalid" 1819 "Invalid" 1818 "Invalid" 1817 "Invalid" 1816 "Invalid" 1815 "Invalid" 1814 "Invalid" 1813 "Invalid" 1812 "Invalid" 1811 "Invalid" 1810 "Invalid" 1809 "Invalid" 1808 "Invalid" 1807 "Invalid" 1806 "Invalid" 1805 "Invalid" 1804 "Invalid" 1803 "Invalid" 1802 "Invalid" 1801 "Invalid" ;
VAL_ 553 BCU_CellVlt032_RM 2047 "Invalid" 2046 "Invalid" 2045 "Invalid" 2044 "Invalid" 2043 "Invalid" 2042 "Invalid" 2041 "Invalid" 2040 "Invalid" 2039 "Invalid" 2038 "Invalid" 2037 "Invalid" 2036 "Invalid" 2035 "Invalid" 2034 "Invalid" 2033 "Invalid" 2032 "Invalid" 2031 "Invalid" 2030 "Invalid" 2029 "Invalid" 2028 "Invalid" 2027 "Invalid" 2026 "Invalid" 2025 "Invalid" 2024 "Invalid" 2023 "Invalid" 2022 "Invalid" 2021 "Invalid" 2020 "Invalid" 2019 "Invalid" 2018 "Invalid" 2017 "Invalid" 2016 "Invalid" 2015 "Invalid" 2014 "Invalid" 2013 "Invalid" 2012 "Invalid" 2011 "Invalid" 2010 "Invalid" 2009 "Invalid" 2008 "Invalid" 2007 "Invalid" 2006 "Invalid" 2005 "Invalid" 2004 "Invalid" 2003 "Invalid" 2002 "Invalid" 2001 "Invalid" 2000 "Invalid" 1999 "Invalid" 1998 "Invalid" 1997 "Invalid" 1996 "Invalid" 1995 "Invalid" 1994 "Invalid" 1993 "Invalid" 1992 "Invalid" 1991 "Invalid" 1990 "Invalid" 1989 "Invalid" 1988 "Invalid" 1987 "Invalid" 1986 "Invalid" 1985 "Invalid" 1984 "Invalid" 1983 "Invalid" 1982 "Invalid" 1981 "Invalid" 1980 "Invalid" 1979 "Invalid" 1978 "Invalid" 1977 "Invalid" 1976 "Invalid" 1975 "Invalid" 1974 "Invalid" 1973 "Invalid" 1972 "Invalid" 1971 "Invalid" 1970 "Invalid" 1969 "Invalid" 1968 "Invalid" 1967 "Invalid" 1966 "Invalid" 1965 "Invalid" 1964 "Invalid" 1963 "Invalid" 1962 "Invalid" 1961 "Invalid" 1960 "Invalid" 1959 "Invalid" 1958 "Invalid" 1957 "Invalid" 1956 "Invalid" 1955 "Invalid" 1954 "Invalid" 1953 "Invalid" 1952 "Invalid" 1951 "Invalid" 1950 "Invalid" 1949 "Invalid" 1948 "Invalid" 1947 "Invalid" 1946 "Invalid" 1945 "Invalid" 1944 "Invalid" 1943 "Invalid" 1942 "Invalid" 1941 "Invalid" 1940 "Invalid" 1939 "Invalid" 1938 "Invalid" 1937 "Invalid" 1936 "Invalid" 1935 "Invalid" 1934 "Invalid" 1933 "Invalid" 1932 "Invalid" 1931 "Invalid" 1930 "Invalid" 1929 "Invalid" 1928 "Invalid" 1927 "Invalid" 1926 "Invalid" 1925 "Invalid" 1924 "Invalid" 1923 "Invalid" 1922 "Invalid" 1921 "Invalid" 1920 "Invalid" 1919 "Invalid" 1918 "Invalid" 1917 "Invalid" 1916 "Invalid" 1915 "Invalid" 1914 "Invalid" 1913 "Invalid" 1912 "Invalid" 1911 "Invalid" 1910 "Invalid" 1909 "Invalid" 1908 "Invalid" 1907 "Invalid" 1906 "Invalid" 1905 "Invalid" 1904 "Invalid" 1903 "Invalid" 1902 "Invalid" 1901 "Invalid" 1900 "Invalid" 1899 "Invalid" 1898 "Invalid" 1897 "Invalid" 1896 "Invalid" 1895 "Invalid" 1894 "Invalid" 1893 "Invalid" 1892 "Invalid" 1891 "Invalid" 1890 "Invalid" 1889 "Invalid" 1888 "Invalid" 1887 "Invalid" 1886 "Invalid" 1885 "Invalid" 1884 "Invalid" 1883 "Invalid" 1882 "Invalid" 1881 "Invalid" 1880 "Invalid" 1879 "Invalid" 1878 "Invalid" 1877 "Invalid" 1876 "Invalid" 1875 "Invalid" 1874 "Invalid" 1873 "Invalid" 1872 "Invalid" 1871 "Invalid" 1870 "Invalid" 1869 "Invalid" 1868 "Invalid" 1867 "Invalid" 1866 "Invalid" 1865 "Invalid" 1864 "Invalid" 1863 "Invalid" 1862 "Invalid" 1861 "Invalid" 1860 "Invalid" 1859 "Invalid" 1858 "Invalid" 1857 "Invalid" 1856 "Invalid" 1855 "Invalid" 1854 "Invalid" 1853 "Invalid" 1852 "Invalid" 1851 "Invalid" 1850 "Invalid" 1849 "Invalid" 1848 "Invalid" 1847 "Invalid" 1846 "Invalid" 1845 "Invalid" 1844 "Invalid" 1843 "Invalid" 1842 "Invalid" 1841 "Invalid" 1840 "Invalid" 1839 "Invalid" 1838 "Invalid" 1837 "Invalid" 1836 "Invalid" 1835 "Invalid" 1834 "Invalid" 1833 "Invalid" 1832 "Invalid" 1831 "Invalid" 1830 "Invalid" 1829 "Invalid" 1828 "Invalid" 1827 "Invalid" 1826 "Invalid" 1825 "Invalid" 1824 "Invalid" 1823 "Invalid" 1822 "Invalid" 1821 "Invalid" 1820 "Invalid" 1819 "Invalid" 1818 "Invalid" 1817 "Invalid" 1816 "Invalid" 1815 "Invalid" 1814 "Invalid" 1813 "Invalid" 1812 "Invalid" 1811 "Invalid" 1810 "Invalid" 1809 "Invalid" 1808 "Invalid" 1807 "Invalid" 1806 "Invalid" 1805 "Invalid" 1804 "Invalid" 1803 "Invalid" 1802 "Invalid" 1801 "Invalid" ;
VAL_ 553 BCU_CellVlt033_RM 2047 "Invalid" 2046 "Invalid" 2045 "Invalid" 2044 "Invalid" 2043 "Invalid" 2042 "Invalid" 2041 "Invalid" 2040 "Invalid" 2039 "Invalid" 2038 "Invalid" 2037 "Invalid" 2036 "Invalid" 2035 "Invalid" 2034 "Invalid" 2033 "Invalid" 2032 "Invalid" 2031 "Invalid" 2030 "Invalid" 2029 "Invalid" 2028 "Invalid" 2027 "Invalid" 2026 "Invalid" 2025 "Invalid" 2024 "Invalid" 2023 "Invalid" 2022 "Invalid" 2021 "Invalid" 2020 "Invalid" 2019 "Invalid" 2018 "Invalid" 2017 "Invalid" 2016 "Invalid" 2015 "Invalid" 2014 "Invalid" 2013 "Invalid" 2012 "Invalid" 2011 "Invalid" 2010 "Invalid" 2009 "Invalid" 2008 "Invalid" 2007 "Invalid" 2006 "Invalid" 2005 "Invalid" 2004 "Invalid" 2003 "Invalid" 2002 "Invalid" 2001 "Invalid" 2000 "Invalid" 1999 "Invalid" 1998 "Invalid" 1997 "Invalid" 1996 "Invalid" 1995 "Invalid" 1994 "Invalid" 1993 "Invalid" 1992 "Invalid" 1991 "Invalid" 1990 "Invalid" 1989 "Invalid" 1988 "Invalid" 1987 "Invalid" 1986 "Invalid" 1985 "Invalid" 1984 "Invalid" 1983 "Invalid" 1982 "Invalid" 1981 "Invalid" 1980 "Invalid" 1979 "Invalid" 1978 "Invalid" 1977 "Invalid" 1976 "Invalid" 1975 "Invalid" 1974 "Invalid" 1973 "Invalid" 1972 "Invalid" 1971 "Invalid" 1970 "Invalid" 1969 "Invalid" 1968 "Invalid" 1967 "Invalid" 1966 "Invalid" 1965 "Invalid" 1964 "Invalid" 1963 "Invalid" 1962 "Invalid" 1961 "Invalid" 1960 "Invalid" 1959 "Invalid" 1958 "Invalid" 1957 "Invalid" 1956 "Invalid" 1955 "Invalid" 1954 "Invalid" 1953 "Invalid" 1952 "Invalid" 1951 "Invalid" 1950 "Invalid" 1949 "Invalid" 1948 "Invalid" 1947 "Invalid" 1946 "Invalid" 1945 "Invalid" 1944 "Invalid" 1943 "Invalid" 1942 "Invalid" 1941 "Invalid" 1940 "Invalid" 1939 "Invalid" 1938 "Invalid" 1937 "Invalid" 1936 "Invalid" 1935 "Invalid" 1934 "Invalid" 1933 "Invalid" 1932 "Invalid" 1931 "Invalid" 1930 "Invalid" 1929 "Invalid" 1928 "Invalid" 1927 "Invalid" 1926 "Invalid" 1925 "Invalid" 1924 "Invalid" 1923 "Invalid" 1922 "Invalid" 1921 "Invalid" 1920 "Invalid" 1919 "Invalid" 1918 "Invalid" 1917 "Invalid" 1916 "Invalid" 1915 "Invalid" 1914 "Invalid" 1913 "Invalid" 1912 "Invalid" 1911 "Invalid" 1910 "Invalid" 1909 "Invalid" 1908 "Invalid" 1907 "Invalid" 1906 "Invalid" 1905 "Invalid" 1904 "Invalid" 1903 "Invalid" 1902 "Invalid" 1901 "Invalid" 1900 "Invalid" 1899 "Invalid" 1898 "Invalid" 1897 "Invalid" 1896 "Invalid" 1895 "Invalid" 1894 "Invalid" 1893 "Invalid" 1892 "Invalid" 1891 "Invalid" 1890 "Invalid" 1889 "Invalid" 1888 "Invalid" 1887 "Invalid" 1886 "Invalid" 1885 "Invalid" 1884 "Invalid" 1883 "Invalid" 1882 "Invalid" 1881 "Invalid" 1880 "Invalid" 1879 "Invalid" 1878 "Invalid" 1877 "Invalid" 1876 "Invalid" 1875 "Invalid" 1874 "Invalid" 1873 "Invalid" 1872 "Invalid" 1871 "Invalid" 1870 "Invalid" 1869 "Invalid" 1868 "Invalid" 1867 "Invalid" 1866 "Invalid" 1865 "Invalid" 1864 "Invalid" 1863 "Invalid" 1862 "Invalid" 1861 "Invalid" 1860 "Invalid" 1859 "Invalid" 1858 "Invalid" 1857 "Invalid" 1856 "Invalid" 1855 "Invalid" 1854 "Invalid" 1853 "Invalid" 1852 "Invalid" 1851 "Invalid" 1850 "Invalid" 1849 "Invalid" 1848 "Invalid" 1847 "Invalid" 1846 "Invalid" 1845 "Invalid" 1844 "Invalid" 1843 "Invalid" 1842 "Invalid" 1841 "Invalid" 1840 "Invalid" 1839 "Invalid" 1838 "Invalid" 1837 "Invalid" 1836 "Invalid" 1835 "Invalid" 1834 "Invalid" 1833 "Invalid" 1832 "Invalid" 1831 "Invalid" 1830 "Invalid" 1829 "Invalid" 1828 "Invalid" 1827 "Invalid" 1826 "Invalid" 1825 "Invalid" 1824 "Invalid" 1823 "Invalid" 1822 "Invalid" 1821 "Invalid" 1820 "Invalid" 1819 "Invalid" 1818 "Invalid" 1817 "Invalid" 1816 "Invalid" 1815 "Invalid" 1814 "Invalid" 1813 "Invalid" 1812 "Invalid" 1811 "Invalid" 1810 "Invalid" 1809 "Invalid" 1808 "Invalid" 1807 "Invalid" 1806 "Invalid" 1805 "Invalid" 1804 "Invalid" 1803 "Invalid" 1802 "Invalid" 1801 "Invalid" ;
VAL_ 553 BCU_CellVlt034_RM 2047 "Invalid" 2046 "Invalid" 2045 "Invalid" 2044 "Invalid" 2043 "Invalid" 2042 "Invalid" 2041 "Invalid" 2040 "Invalid" 2039 "Invalid" 2038 "Invalid" 2037 "Invalid" 2036 "Invalid" 2035 "Invalid" 2034 "Invalid" 2033 "Invalid" 2032 "Invalid" 2031 "Invalid" 2030 "Invalid" 2029 "Invalid" 2028 "Invalid" 2027 "Invalid" 2026 "Invalid" 2025 "Invalid" 2024 "Invalid" 2023 "Invalid" 2022 "Invalid" 2021 "Invalid" 2020 "Invalid" 2019 "Invalid" 2018 "Invalid" 2017 "Invalid" 2016 "Invalid" 2015 "Invalid" 2014 "Invalid" 2013 "Invalid" 2012 "Invalid" 2011 "Invalid" 2010 "Invalid" 2009 "Invalid" 2008 "Invalid" 2007 "Invalid" 2006 "Invalid" 2005 "Invalid" 2004 "Invalid" 2003 "Invalid" 2002 "Invalid" 2001 "Invalid" 2000 "Invalid" 1999 "Invalid" 1998 "Invalid" 1997 "Invalid" 1996 "Invalid" 1995 "Invalid" 1994 "Invalid" 1993 "Invalid" 1992 "Invalid" 1991 "Invalid" 1990 "Invalid" 1989 "Invalid" 1988 "Invalid" 1987 "Invalid" 1986 "Invalid" 1985 "Invalid" 1984 "Invalid" 1983 "Invalid" 1982 "Invalid" 1981 "Invalid" 1980 "Invalid" 1979 "Invalid" 1978 "Invalid" 1977 "Invalid" 1976 "Invalid" 1975 "Invalid" 1974 "Invalid" 1973 "Invalid" 1972 "Invalid" 1971 "Invalid" 1970 "Invalid" 1969 "Invalid" 1968 "Invalid" 1967 "Invalid" 1966 "Invalid" 1965 "Invalid" 1964 "Invalid" 1963 "Invalid" 1962 "Invalid" 1961 "Invalid" 1960 "Invalid" 1959 "Invalid" 1958 "Invalid" 1957 "Invalid" 1956 "Invalid" 1955 "Invalid" 1954 "Invalid" 1953 "Invalid" 1952 "Invalid" 1951 "Invalid" 1950 "Invalid" 1949 "Invalid" 1948 "Invalid" 1947 "Invalid" 1946 "Invalid" 1945 "Invalid" 1944 "Invalid" 1943 "Invalid" 1942 "Invalid" 1941 "Invalid" 1940 "Invalid" 1939 "Invalid" 1938 "Invalid" 1937 "Invalid" 1936 "Invalid" 1935 "Invalid" 1934 "Invalid" 1933 "Invalid" 1932 "Invalid" 1931 "Invalid" 1930 "Invalid" 1929 "Invalid" 1928 "Invalid" 1927 "Invalid" 1926 "Invalid" 1925 "Invalid" 1924 "Invalid" 1923 "Invalid" 1922 "Invalid" 1921 "Invalid" 1920 "Invalid" 1919 "Invalid" 1918 "Invalid" 1917 "Invalid" 1916 "Invalid" 1915 "Invalid" 1914 "Invalid" 1913 "Invalid" 1912 "Invalid" 1911 "Invalid" 1910 "Invalid" 1909 "Invalid" 1908 "Invalid" 1907 "Invalid" 1906 "Invalid" 1905 "Invalid" 1904 "Invalid" 1903 "Invalid" 1902 "Invalid" 1901 "Invalid" 1900 "Invalid" 1899 "Invalid" 1898 "Invalid" 1897 "Invalid" 1896 "Invalid" 1895 "Invalid" 1894 "Invalid" 1893 "Invalid" 1892 "Invalid" 1891 "Invalid" 1890 "Invalid" 1889 "Invalid" 1888 "Invalid" 1887 "Invalid" 1886 "Invalid" 1885 "Invalid" 1884 "Invalid" 1883 "Invalid" 1882 "Invalid" 1881 "Invalid" 1880 "Invalid" 1879 "Invalid" 1878 "Invalid" 1877 "Invalid" 1876 "Invalid" 1875 "Invalid" 1874 "Invalid" 1873 "Invalid" 1872 "Invalid" 1871 "Invalid" 1870 "Invalid" 1869 "Invalid" 1868 "Invalid" 1867 "Invalid" 1866 "Invalid" 1865 "Invalid" 1864 "Invalid" 1863 "Invalid" 1862 "Invalid" 1861 "Invalid" 1860 "Invalid" 1859 "Invalid" 1858 "Invalid" 1857 "Invalid" 1856 "Invalid" 1855 "Invalid" 1854 "Invalid" 1853 "Invalid" 1852 "Invalid" 1851 "Invalid" 1850 "Invalid" 1849 "Invalid" 1848 "Invalid" 1847 "Invalid" 1846 "Invalid" 1845 "Invalid" 1844 "Invalid" 1843 "Invalid" 1842 "Invalid" 1841 "Invalid" 1840 "Invalid" 1839 "Invalid" 1838 "Invalid" 1837 "Invalid" 1836 "Invalid" 1835 "Invalid" 1834 "Invalid" 1833 "Invalid" 1832 "Invalid" 1831 "Invalid" 1830 "Invalid" 1829 "Invalid" 1828 "Invalid" 1827 "Invalid" 1826 "Invalid" 1825 "Invalid" 1824 "Invalid" 1823 "Invalid" 1822 "Invalid" 1821 "Invalid" 1820 "Invalid" 1819 "Invalid" 1818 "Invalid" 1817 "Invalid" 1816 "Invalid" 1815 "Invalid" 1814 "Invalid" 1813 "Invalid" 1812 "Invalid" 1811 "Invalid" 1810 "Invalid" 1809 "Invalid" 1808 "Invalid" 1807 "Invalid" 1806 "Invalid" 1805 "Invalid" 1804 "Invalid" 1803 "Invalid" 1802 "Invalid" 1801 "Invalid" ;
VAL_ 553 BCU_CellVlt035_RM 2047 "Invalid" 2046 "Invalid" 2045 "Invalid" 2044 "Invalid" 2043 "Invalid" 2042 "Invalid" 2041 "Invalid" 2040 "Invalid" 2039 "Invalid" 2038 "Invalid" 2037 "Invalid" 2036 "Invalid" 2035 "Invalid" 2034 "Invalid" 2033 "Invalid" 2032 "Invalid" 2031 "Invalid" 2030 "Invalid" 2029 "Invalid" 2028 "Invalid" 2027 "Invalid" 2026 "Invalid" 2025 "Invalid" 2024 "Invalid" 2023 "Invalid" 2022 "Invalid" 2021 "Invalid" 2020 "Invalid" 2019 "Invalid" 2018 "Invalid" 2017 "Invalid" 2016 "Invalid" 2015 "Invalid" 2014 "Invalid" 2013 "Invalid" 2012 "Invalid" 2011 "Invalid" 2010 "Invalid" 2009 "Invalid" 2008 "Invalid" 2007 "Invalid" 2006 "Invalid" 2005 "Invalid" 2004 "Invalid" 2003 "Invalid" 2002 "Invalid" 2001 "Invalid" 2000 "Invalid" 1999 "Invalid" 1998 "Invalid" 1997 "Invalid" 1996 "Invalid" 1995 "Invalid" 1994 "Invalid" 1993 "Invalid" 1992 "Invalid" 1991 "Invalid" 1990 "Invalid" 1989 "Invalid" 1988 "Invalid" 1987 "Invalid" 1986 "Invalid" 1985 "Invalid" 1984 "Invalid" 1983 "Invalid" 1982 "Invalid" 1981 "Invalid" 1980 "Invalid" 1979 "Invalid" 1978 "Invalid" 1977 "Invalid" 1976 "Invalid" 1975 "Invalid" 1974 "Invalid" 1973 "Invalid" 1972 "Invalid" 1971 "Invalid" 1970 "Invalid" 1969 "Invalid" 1968 "Invalid" 1967 "Invalid" 1966 "Invalid" 1965 "Invalid" 1964 "Invalid" 1963 "Invalid" 1962 "Invalid" 1961 "Invalid" 1960 "Invalid" 1959 "Invalid" 1958 "Invalid" 1957 "Invalid" 1956 "Invalid" 1955 "Invalid" 1954 "Invalid" 1953 "Invalid" 1952 "Invalid" 1951 "Invalid" 1950 "Invalid" 1949 "Invalid" 1948 "Invalid" 1947 "Invalid" 1946 "Invalid" 1945 "Invalid" 1944 "Invalid" 1943 "Invalid" 1942 "Invalid" 1941 "Invalid" 1940 "Invalid" 1939 "Invalid" 1938 "Invalid" 1937 "Invalid" 1936 "Invalid" 1935 "Invalid" 1934 "Invalid" 1933 "Invalid" 1932 "Invalid" 1931 "Invalid" 1930 "Invalid" 1929 "Invalid" 1928 "Invalid" 1927 "Invalid" 1926 "Invalid" 1925 "Invalid" 1924 "Invalid" 1923 "Invalid" 1922 "Invalid" 1921 "Invalid" 1920 "Invalid" 1919 "Invalid" 1918 "Invalid" 1917 "Invalid" 1916 "Invalid" 1915 "Invalid" 1914 "Invalid" 1913 "Invalid" 1912 "Invalid" 1911 "Invalid" 1910 "Invalid" 1909 "Invalid" 1908 "Invalid" 1907 "Invalid" 1906 "Invalid" 1905 "Invalid" 1904 "Invalid" 1903 "Invalid" 1902 "Invalid" 1901 "Invalid" 1900 "Invalid" 1899 "Invalid" 1898 "Invalid" 1897 "Invalid" 1896 "Invalid" 1895 "Invalid" 1894 "Invalid" 1893 "Invalid" 1892 "Invalid" 1891 "Invalid" 1890 "Invalid" 1889 "Invalid" 1888 "Invalid" 1887 "Invalid" 1886 "Invalid" 1885 "Invalid" 1884 "Invalid" 1883 "Invalid" 1882 "Invalid" 1881 "Invalid" 1880 "Invalid" 1879 "Invalid" 1878 "Invalid" 1877 "Invalid" 1876 "Invalid" 1875 "Invalid" 1874 "Invalid" 1873 "Invalid" 1872 "Invalid" 1871 "Invalid" 1870 "Invalid" 1869 "Invalid" 1868 "Invalid" 1867 "Invalid" 1866 "Invalid" 1865 "Invalid" 1864 "Invalid" 1863 "Invalid" 1862 "Invalid" 1861 "Invalid" 1860 "Invalid" 1859 "Invalid" 1858 "Invalid" 1857 "Invalid" 1856 "Invalid" 1855 "Invalid" 1854 "Invalid" 1853 "Invalid" 1852 "Invalid" 1851 "Invalid" 1850 "Invalid" 1849 "Invalid" 1848 "Invalid" 1847 "Invalid" 1846 "Invalid" 1845 "Invalid" 1844 "Invalid" 1843 "Invalid" 1842 "Invalid" 1841 "Invalid" 1840 "Invalid" 1839 "Invalid" 1838 "Invalid" 1837 "Invalid" 1836 "Invalid" 1835 "Invalid" 1834 "Invalid" 1833 "Invalid" 1832 "Invalid" 1831 "Invalid" 1830 "Invalid" 1829 "Invalid" 1828 "Invalid" 1827 "Invalid" 1826 "Invalid" 1825 "Invalid" 1824 "Invalid" 1823 "Invalid" 1822 "Invalid" 1821 "Invalid" 1820 "Invalid" 1819 "Invalid" 1818 "Invalid" 1817 "Invalid" 1816 "Invalid" 1815 "Invalid" 1814 "Invalid" 1813 "Invalid" 1812 "Invalid" 1811 "Invalid" 1810 "Invalid" 1809 "Invalid" 1808 "Invalid" 1807 "Invalid" 1806 "Invalid" 1805 "Invalid" 1804 "Invalid" 1803 "Invalid" 1802 "Invalid" 1801 "Invalid" ;
VAL_ 553 BCU_CellTmp007_RM 255 "Invalid" 254 "Invalid" 253 "Invalid" 252 "Invalid" 251 "Invalid" 250 "Invalid" 249 "Invalid" 248 "Invalid" 247 "Invalid" 246 "Invalid" 245 "Invalid" 244 "Invalid" 243 "Invalid" 242 "Invalid" 241 "Invalid" 240 "Invalid" 239 "Invalid" 238 "Invalid" 237 "Invalid" 236 "Invalid" 235 "Invalid" 234 "Invalid" 233 "Invalid" 232 "Invalid" 231 "Invalid" 230 "Invalid" 229 "Invalid" 228 "Invalid" 227 "Invalid" 226 "Invalid" 225 "Invalid" 224 "Invalid" 223 "Invalid" 222 "Invalid" 221 "Invalid" 220 "Invalid" 219 "Invalid" 218 "Invalid" 217 "Invalid" 216 "Invalid" 215 "Invalid" 214 "Invalid" 213 "Invalid" 212 "Invalid" 211 "Invalid" 210 "Invalid" 209 "Invalid" 208 "Invalid" 207 "Invalid" 206 "Invalid" 205 "Invalid" 204 "Invalid" 203 "Invalid" 202 "Invalid" 201 "Invalid" 200 "Invalid" 199 "Invalid" 198 "Invalid" 197 "Invalid" 196 "Invalid" 195 "Invalid" 194 "Invalid" 193 "Invalid" 192 "Invalid" 191 "Invalid" 190 "Invalid" 189 "Invalid" 188 "Invalid" 187 "Invalid" 186 "Invalid" 185 "Invalid" 184 "Invalid" 183 "Invalid" 182 "Invalid" 181 "Invalid" 180 "Invalid" 179 "Invalid" 178 "Invalid" 177 "Invalid" 176 "Invalid" 175 "Invalid" 174 "Invalid" 173 "Invalid" 172 "Invalid" 171 "Invalid" 170 "Invalid" 169 "Invalid" 168 "Invalid" 167 "Invalid" 166 "Invalid" 165 "Invalid" 164 "Invalid" 163 "Invalid" 162 "Invalid" 161 "Invalid" ;
VAL_ 554 BCU_CellVlt036_RM 2047 "Invalid" 2046 "Invalid" 2045 "Invalid" 2044 "Invalid" 2043 "Invalid" 2042 "Invalid" 2041 "Invalid" 2040 "Invalid" 2039 "Invalid" 2038 "Invalid" 2037 "Invalid" 2036 "Invalid" 2035 "Invalid" 2034 "Invalid" 2033 "Invalid" 2032 "Invalid" 2031 "Invalid" 2030 "Invalid" 2029 "Invalid" 2028 "Invalid" 2027 "Invalid" 2026 "Invalid" 2025 "Invalid" 2024 "Invalid" 2023 "Invalid" 2022 "Invalid" 2021 "Invalid" 2020 "Invalid" 2019 "Invalid" 2018 "Invalid" 2017 "Invalid" 2016 "Invalid" 2015 "Invalid" 2014 "Invalid" 2013 "Invalid" 2012 "Invalid" 2011 "Invalid" 2010 "Invalid" 2009 "Invalid" 2008 "Invalid" 2007 "Invalid" 2006 "Invalid" 2005 "Invalid" 2004 "Invalid" 2003 "Invalid" 2002 "Invalid" 2001 "Invalid" 2000 "Invalid" 1999 "Invalid" 1998 "Invalid" 1997 "Invalid" 1996 "Invalid" 1995 "Invalid" 1994 "Invalid" 1993 "Invalid" 1992 "Invalid" 1991 "Invalid" 1990 "Invalid" 1989 "Invalid" 1988 "Invalid" 1987 "Invalid" 1986 "Invalid" 1985 "Invalid" 1984 "Invalid" 1983 "Invalid" 1982 "Invalid" 1981 "Invalid" 1980 "Invalid" 1979 "Invalid" 1978 "Invalid" 1977 "Invalid" 1976 "Invalid" 1975 "Invalid" 1974 "Invalid" 1973 "Invalid" 1972 "Invalid" 1971 "Invalid" 1970 "Invalid" 1969 "Invalid" 1968 "Invalid" 1967 "Invalid" 1966 "Invalid" 1965 "Invalid" 1964 "Invalid" 1963 "Invalid" 1962 "Invalid" 1961 "Invalid" 1960 "Invalid" 1959 "Invalid" 1958 "Invalid" 1957 "Invalid" 1956 "Invalid" 1955 "Invalid" 1954 "Invalid" 1953 "Invalid" 1952 "Invalid" 1951 "Invalid" 1950 "Invalid" 1949 "Invalid" 1948 "Invalid" 1947 "Invalid" 1946 "Invalid" 1945 "Invalid" 1944 "Invalid" 1943 "Invalid" 1942 "Invalid" 1941 "Invalid" 1940 "Invalid" 1939 "Invalid" 1938 "Invalid" 1937 "Invalid" 1936 "Invalid" 1935 "Invalid" 1934 "Invalid" 1933 "Invalid" 1932 "Invalid" 1931 "Invalid" 1930 "Invalid" 1929 "Invalid" 1928 "Invalid" 1927 "Invalid" 1926 "Invalid" 1925 "Invalid" 1924 "Invalid" 1923 "Invalid" 1922 "Invalid" 1921 "Invalid" 1920 "Invalid" 1919 "Invalid" 1918 "Invalid" 1917 "Invalid" 1916 "Invalid" 1915 "Invalid" 1914 "Invalid" 1913 "Invalid" 1912 "Invalid" 1911 "Invalid" 1910 "Invalid" 1909 "Invalid" 1908 "Invalid" 1907 "Invalid" 1906 "Invalid" 1905 "Invalid" 1904 "Invalid" 1903 "Invalid" 1902 "Invalid" 1901 "Invalid" 1900 "Invalid" 1899 "Invalid" 1898 "Invalid" 1897 "Invalid" 1896 "Invalid" 1895 "Invalid" 1894 "Invalid" 1893 "Invalid" 1892 "Invalid" 1891 "Invalid" 1890 "Invalid" 1889 "Invalid" 1888 "Invalid" 1887 "Invalid" 1886 "Invalid" 1885 "Invalid" 1884 "Invalid" 1883 "Invalid" 1882 "Invalid" 1881 "Invalid" 1880 "Invalid" 1879 "Invalid" 1878 "Invalid" 1877 "Invalid" 1876 "Invalid" 1875 "Invalid" 1874 "Invalid" 1873 "Invalid" 1872 "Invalid" 1871 "Invalid" 1870 "Invalid" 1869 "Invalid" 1868 "Invalid" 1867 "Invalid" 1866 "Invalid" 1865 "Invalid" 1864 "Invalid" 1863 "Invalid" 1862 "Invalid" 1861 "Invalid" 1860 "Invalid" 1859 "Invalid" 1858 "Invalid" 1857 "Invalid" 1856 "Invalid" 1855 "Invalid" 1854 "Invalid" 1853 "Invalid" 1852 "Invalid" 1851 "Invalid" 1850 "Invalid" 1849 "Invalid" 1848 "Invalid" 1847 "Invalid" 1846 "Invalid" 1845 "Invalid" 1844 "Invalid" 1843 "Invalid" 1842 "Invalid" 1841 "Invalid" 1840 "Invalid" 1839 "Invalid" 1838 "Invalid" 1837 "Invalid" 1836 "Invalid" 1835 "Invalid" 1834 "Invalid" 1833 "Invalid" 1832 "Invalid" 1831 "Invalid" 1830 "Invalid" 1829 "Invalid" 1828 "Invalid" 1827 "Invalid" 1826 "Invalid" 1825 "Invalid" 1824 "Invalid" 1823 "Invalid" 1822 "Invalid" 1821 "Invalid" 1820 "Invalid" 1819 "Invalid" 1818 "Invalid" 1817 "Invalid" 1816 "Invalid" 1815 "Invalid" 1814 "Invalid" 1813 "Invalid" 1812 "Invalid" 1811 "Invalid" 1810 "Invalid" 1809 "Invalid" 1808 "Invalid" 1807 "Invalid" 1806 "Invalid" 1805 "Invalid" 1804 "Invalid" 1803 "Invalid" 1802 "Invalid" 1801 "Invalid" ;
VAL_ 554 BCU_CellVlt037_RM 2047 "Invalid" 2046 "Invalid" 2045 "Invalid" 2044 "Invalid" 2043 "Invalid" 2042 "Invalid" 2041 "Invalid" 2040 "Invalid" 2039 "Invalid" 2038 "Invalid" 2037 "Invalid" 2036 "Invalid" 2035 "Invalid" 2034 "Invalid" 2033 "Invalid" 2032 "Invalid" 2031 "Invalid" 2030 "Invalid" 2029 "Invalid" 2028 "Invalid" 2027 "Invalid" 2026 "Invalid" 2025 "Invalid" 2024 "Invalid" 2023 "Invalid" 2022 "Invalid" 2021 "Invalid" 2020 "Invalid" 2019 "Invalid" 2018 "Invalid" 2017 "Invalid" 2016 "Invalid" 2015 "Invalid" 2014 "Invalid" 2013 "Invalid" 2012 "Invalid" 2011 "Invalid" 2010 "Invalid" 2009 "Invalid" 2008 "Invalid" 2007 "Invalid" 2006 "Invalid" 2005 "Invalid" 2004 "Invalid" 2003 "Invalid" 2002 "Invalid" 2001 "Invalid" 2000 "Invalid" 1999 "Invalid" 1998 "Invalid" 1997 "Invalid" 1996 "Invalid" 1995 "Invalid" 1994 "Invalid" 1993 "Invalid" 1992 "Invalid" 1991 "Invalid" 1990 "Invalid" 1989 "Invalid" 1988 "Invalid" 1987 "Invalid" 1986 "Invalid" 1985 "Invalid" 1984 "Invalid" 1983 "Invalid" 1982 "Invalid" 1981 "Invalid" 1980 "Invalid" 1979 "Invalid" 1978 "Invalid" 1977 "Invalid" 1976 "Invalid" 1975 "Invalid" 1974 "Invalid" 1973 "Invalid" 1972 "Invalid" 1971 "Invalid" 1970 "Invalid" 1969 "Invalid" 1968 "Invalid" 1967 "Invalid" 1966 "Invalid" 1965 "Invalid" 1964 "Invalid" 1963 "Invalid" 1962 "Invalid" 1961 "Invalid" 1960 "Invalid" 1959 "Invalid" 1958 "Invalid" 1957 "Invalid" 1956 "Invalid" 1955 "Invalid" 1954 "Invalid" 1953 "Invalid" 1952 "Invalid" 1951 "Invalid" 1950 "Invalid" 1949 "Invalid" 1948 "Invalid" 1947 "Invalid" 1946 "Invalid" 1945 "Invalid" 1944 "Invalid" 1943 "Invalid" 1942 "Invalid" 1941 "Invalid" 1940 "Invalid" 1939 "Invalid" 1938 "Invalid" 1937 "Invalid" 1936 "Invalid" 1935 "Invalid" 1934 "Invalid" 1933 "Invalid" 1932 "Invalid" 1931 "Invalid" 1930 "Invalid" 1929 "Invalid" 1928 "Invalid" 1927 "Invalid" 1926 "Invalid" 1925 "Invalid" 1924 "Invalid" 1923 "Invalid" 1922 "Invalid" 1921 "Invalid" 1920 "Invalid" 1919 "Invalid" 1918 "Invalid" 1917 "Invalid" 1916 "Invalid" 1915 "Invalid" 1914 "Invalid" 1913 "Invalid" 1912 "Invalid" 1911 "Invalid" 1910 "Invalid" 1909 "Invalid" 1908 "Invalid" 1907 "Invalid" 1906 "Invalid" 1905 "Invalid" 1904 "Invalid" 1903 "Invalid" 1902 "Invalid" 1901 "Invalid" 1900 "Invalid" 1899 "Invalid" 1898 "Invalid" 1897 "Invalid" 1896 "Invalid" 1895 "Invalid" 1894 "Invalid" 1893 "Invalid" 1892 "Invalid" 1891 "Invalid" 1890 "Invalid" 1889 "Invalid" 1888 "Invalid" 1887 "Invalid" 1886 "Invalid" 1885 "Invalid" 1884 "Invalid" 1883 "Invalid" 1882 "Invalid" 1881 "Invalid" 1880 "Invalid" 1879 "Invalid" 1878 "Invalid" 1877 "Invalid" 1876 "Invalid" 1875 "Invalid" 1874 "Invalid" 1873 "Invalid" 1872 "Invalid" 1871 "Invalid" 1870 "Invalid" 1869 "Invalid" 1868 "Invalid" 1867 "Invalid" 1866 "Invalid" 1865 "Invalid" 1864 "Invalid" 1863 "Invalid" 1862 "Invalid" 1861 "Invalid" 1860 "Invalid" 1859 "Invalid" 1858 "Invalid" 1857 "Invalid" 1856 "Invalid" 1855 "Invalid" 1854 "Invalid" 1853 "Invalid" 1852 "Invalid" 1851 "Invalid" 1850 "Invalid" 1849 "Invalid" 1848 "Invalid" 1847 "Invalid" 1846 "Invalid" 1845 "Invalid" 1844 "Invalid" 1843 "Invalid" 1842 "Invalid" 1841 "Invalid" 1840 "Invalid" 1839 "Invalid" 1838 "Invalid" 1837 "Invalid" 1836 "Invalid" 1835 "Invalid" 1834 "Invalid" 1833 "Invalid" 1832 "Invalid" 1831 "Invalid" 1830 "Invalid" 1829 "Invalid" 1828 "Invalid" 1827 "Invalid" 1826 "Invalid" 1825 "Invalid" 1824 "Invalid" 1823 "Invalid" 1822 "Invalid" 1821 "Invalid" 1820 "Invalid" 1819 "Invalid" 1818 "Invalid" 1817 "Invalid" 1816 "Invalid" 1815 "Invalid" 1814 "Invalid" 1813 "Invalid" 1812 "Invalid" 1811 "Invalid" 1810 "Invalid" 1809 "Invalid" 1808 "Invalid" 1807 "Invalid" 1806 "Invalid" 1805 "Invalid" 1804 "Invalid" 1803 "Invalid" 1802 "Invalid" 1801 "Invalid" ;
VAL_ 554 BCU_CellVlt038_RM 2047 "Invalid" 2046 "Invalid" 2045 "Invalid" 2044 "Invalid" 2043 "Invalid" 2042 "Invalid" 2041 "Invalid" 2040 "Invalid" 2039 "Invalid" 2038 "Invalid" 2037 "Invalid" 2036 "Invalid" 2035 "Invalid" 2034 "Invalid" 2033 "Invalid" 2032 "Invalid" 2031 "Invalid" 2030 "Invalid" 2029 "Invalid" 2028 "Invalid" 2027 "Invalid" 2026 "Invalid" 2025 "Invalid" 2024 "Invalid" 2023 "Invalid" 2022 "Invalid" 2021 "Invalid" 2020 "Invalid" 2019 "Invalid" 2018 "Invalid" 2017 "Invalid" 2016 "Invalid" 2015 "Invalid" 2014 "Invalid" 2013 "Invalid" 2012 "Invalid" 2011 "Invalid" 2010 "Invalid" 2009 "Invalid" 2008 "Invalid" 2007 "Invalid" 2006 "Invalid" 2005 "Invalid" 2004 "Invalid" 2003 "Invalid" 2002 "Invalid" 2001 "Invalid" 2000 "Invalid" 1999 "Invalid" 1998 "Invalid" 1997 "Invalid" 1996 "Invalid" 1995 "Invalid" 1994 "Invalid" 1993 "Invalid" 1992 "Invalid" 1991 "Invalid" 1990 "Invalid" 1989 "Invalid" 1988 "Invalid" 1987 "Invalid" 1986 "Invalid" 1985 "Invalid" 1984 "Invalid" 1983 "Invalid" 1982 "Invalid" 1981 "Invalid" 1980 "Invalid" 1979 "Invalid" 1978 "Invalid" 1977 "Invalid" 1976 "Invalid" 1975 "Invalid" 1974 "Invalid" 1973 "Invalid" 1972 "Invalid" 1971 "Invalid" 1970 "Invalid" 1969 "Invalid" 1968 "Invalid" 1967 "Invalid" 1966 "Invalid" 1965 "Invalid" 1964 "Invalid" 1963 "Invalid" 1962 "Invalid" 1961 "Invalid" 1960 "Invalid" 1959 "Invalid" 1958 "Invalid" 1957 "Invalid" 1956 "Invalid" 1955 "Invalid" 1954 "Invalid" 1953 "Invalid" 1952 "Invalid" 1951 "Invalid" 1950 "Invalid" 1949 "Invalid" 1948 "Invalid" 1947 "Invalid" 1946 "Invalid" 1945 "Invalid" 1944 "Invalid" 1943 "Invalid" 1942 "Invalid" 1941 "Invalid" 1940 "Invalid" 1939 "Invalid" 1938 "Invalid" 1937 "Invalid" 1936 "Invalid" 1935 "Invalid" 1934 "Invalid" 1933 "Invalid" 1932 "Invalid" 1931 "Invalid" 1930 "Invalid" 1929 "Invalid" 1928 "Invalid" 1927 "Invalid" 1926 "Invalid" 1925 "Invalid" 1924 "Invalid" 1923 "Invalid" 1922 "Invalid" 1921 "Invalid" 1920 "Invalid" 1919 "Invalid" 1918 "Invalid" 1917 "Invalid" 1916 "Invalid" 1915 "Invalid" 1914 "Invalid" 1913 "Invalid" 1912 "Invalid" 1911 "Invalid" 1910 "Invalid" 1909 "Invalid" 1908 "Invalid" 1907 "Invalid" 1906 "Invalid" 1905 "Invalid" 1904 "Invalid" 1903 "Invalid" 1902 "Invalid" 1901 "Invalid" 1900 "Invalid" 1899 "Invalid" 1898 "Invalid" 1897 "Invalid" 1896 "Invalid" 1895 "Invalid" 1894 "Invalid" 1893 "Invalid" 1892 "Invalid" 1891 "Invalid" 1890 "Invalid" 1889 "Invalid" 1888 "Invalid" 1887 "Invalid" 1886 "Invalid" 1885 "Invalid" 1884 "Invalid" 1883 "Invalid" 1882 "Invalid" 1881 "Invalid" 1880 "Invalid" 1879 "Invalid" 1878 "Invalid" 1877 "Invalid" 1876 "Invalid" 1875 "Invalid" 1874 "Invalid" 1873 "Invalid" 1872 "Invalid" 1871 "Invalid" 1870 "Invalid" 1869 "Invalid" 1868 "Invalid" 1867 "Invalid" 1866 "Invalid" 1865 "Invalid" 1864 "Invalid" 1863 "Invalid" 1862 "Invalid" 1861 "Invalid" 1860 "Invalid" 1859 "Invalid" 1858 "Invalid" 1857 "Invalid" 1856 "Invalid" 1855 "Invalid" 1854 "Invalid" 1853 "Invalid" 1852 "Invalid" 1851 "Invalid" 1850 "Invalid" 1849 "Invalid" 1848 "Invalid" 1847 "Invalid" 1846 "Invalid" 1845 "Invalid" 1844 "Invalid" 1843 "Invalid" 1842 "Invalid" 1841 "Invalid" 1840 "Invalid" 1839 "Invalid" 1838 "Invalid" 1837 "Invalid" 1836 "Invalid" 1835 "Invalid" 1834 "Invalid" 1833 "Invalid" 1832 "Invalid" 1831 "Invalid" 1830 "Invalid" 1829 "Invalid" 1828 "Invalid" 1827 "Invalid" 1826 "Invalid" 1825 "Invalid" 1824 "Invalid" 1823 "Invalid" 1822 "Invalid" 1821 "Invalid" 1820 "Invalid" 1819 "Invalid" 1818 "Invalid" 1817 "Invalid" 1816 "Invalid" 1815 "Invalid" 1814 "Invalid" 1813 "Invalid" 1812 "Invalid" 1811 "Invalid" 1810 "Invalid" 1809 "Invalid" 1808 "Invalid" 1807 "Invalid" 1806 "Invalid" 1805 "Invalid" 1804 "Invalid" 1803 "Invalid" 1802 "Invalid" 1801 "Invalid" ;
VAL_ 554 BCU_CellVlt039_RM 2047 "Invalid" 2046 "Invalid" 2045 "Invalid" 2044 "Invalid" 2043 "Invalid" 2042 "Invalid" 2041 "Invalid" 2040 "Invalid" 2039 "Invalid" 2038 "Invalid" 2037 "Invalid" 2036 "Invalid" 2035 "Invalid" 2034 "Invalid" 2033 "Invalid" 2032 "Invalid" 2031 "Invalid" 2030 "Invalid" 2029 "Invalid" 2028 "Invalid" 2027 "Invalid" 2026 "Invalid" 2025 "Invalid" 2024 "Invalid" 2023 "Invalid" 2022 "Invalid" 2021 "Invalid" 2020 "Invalid" 2019 "Invalid" 2018 "Invalid" 2017 "Invalid" 2016 "Invalid" 2015 "Invalid" 2014 "Invalid" 2013 "Invalid" 2012 "Invalid" 2011 "Invalid" 2010 "Invalid" 2009 "Invalid" 2008 "Invalid" 2007 "Invalid" 2006 "Invalid" 2005 "Invalid" 2004 "Invalid" 2003 "Invalid" 2002 "Invalid" 2001 "Invalid" 2000 "Invalid" 1999 "Invalid" 1998 "Invalid" 1997 "Invalid" 1996 "Invalid" 1995 "Invalid" 1994 "Invalid" 1993 "Invalid" 1992 "Invalid" 1991 "Invalid" 1990 "Invalid" 1989 "Invalid" 1988 "Invalid" 1987 "Invalid" 1986 "Invalid" 1985 "Invalid" 1984 "Invalid" 1983 "Invalid" 1982 "Invalid" 1981 "Invalid" 1980 "Invalid" 1979 "Invalid" 1978 "Invalid" 1977 "Invalid" 1976 "Invalid" 1975 "Invalid" 1974 "Invalid" 1973 "Invalid" 1972 "Invalid" 1971 "Invalid" 1970 "Invalid" 1969 "Invalid" 1968 "Invalid" 1967 "Invalid" 1966 "Invalid" 1965 "Invalid" 1964 "Invalid" 1963 "Invalid" 1962 "Invalid" 1961 "Invalid" 1960 "Invalid" 1959 "Invalid" 1958 "Invalid" 1957 "Invalid" 1956 "Invalid" 1955 "Invalid" 1954 "Invalid" 1953 "Invalid" 1952 "Invalid" 1951 "Invalid" 1950 "Invalid" 1949 "Invalid" 1948 "Invalid" 1947 "Invalid" 1946 "Invalid" 1945 "Invalid" 1944 "Invalid" 1943 "Invalid" 1942 "Invalid" 1941 "Invalid" 1940 "Invalid" 1939 "Invalid" 1938 "Invalid" 1937 "Invalid" 1936 "Invalid" 1935 "Invalid" 1934 "Invalid" 1933 "Invalid" 1932 "Invalid" 1931 "Invalid" 1930 "Invalid" 1929 "Invalid" 1928 "Invalid" 1927 "Invalid" 1926 "Invalid" 1925 "Invalid" 1924 "Invalid" 1923 "Invalid" 1922 "Invalid" 1921 "Invalid" 1920 "Invalid" 1919 "Invalid" 1918 "Invalid" 1917 "Invalid" 1916 "Invalid" 1915 "Invalid" 1914 "Invalid" 1913 "Invalid" 1912 "Invalid" 1911 "Invalid" 1910 "Invalid" 1909 "Invalid" 1908 "Invalid" 1907 "Invalid" 1906 "Invalid" 1905 "Invalid" 1904 "Invalid" 1903 "Invalid" 1902 "Invalid" 1901 "Invalid" 1900 "Invalid" 1899 "Invalid" 1898 "Invalid" 1897 "Invalid" 1896 "Invalid" 1895 "Invalid" 1894 "Invalid" 1893 "Invalid" 1892 "Invalid" 1891 "Invalid" 1890 "Invalid" 1889 "Invalid" 1888 "Invalid" 1887 "Invalid" 1886 "Invalid" 1885 "Invalid" 1884 "Invalid" 1883 "Invalid" 1882 "Invalid" 1881 "Invalid" 1880 "Invalid" 1879 "Invalid" 1878 "Invalid" 1877 "Invalid" 1876 "Invalid" 1875 "Invalid" 1874 "Invalid" 1873 "Invalid" 1872 "Invalid" 1871 "Invalid" 1870 "Invalid" 1869 "Invalid" 1868 "Invalid" 1867 "Invalid" 1866 "Invalid" 1865 "Invalid" 1864 "Invalid" 1863 "Invalid" 1862 "Invalid" 1861 "Invalid" 1860 "Invalid" 1859 "Invalid" 1858 "Invalid" 1857 "Invalid" 1856 "Invalid" 1855 "Invalid" 1854 "Invalid" 1853 "Invalid" 1852 "Invalid" 1851 "Invalid" 1850 "Invalid" 1849 "Invalid" 1848 "Invalid" 1847 "Invalid" 1846 "Invalid" 1845 "Invalid" 1844 "Invalid" 1843 "Invalid" 1842 "Invalid" 1841 "Invalid" 1840 "Invalid" 1839 "Invalid" 1838 "Invalid" 1837 "Invalid" 1836 "Invalid" 1835 "Invalid" 1834 "Invalid" 1833 "Invalid" 1832 "Invalid" 1831 "Invalid" 1830 "Invalid" 1829 "Invalid" 1828 "Invalid" 1827 "Invalid" 1826 "Invalid" 1825 "Invalid" 1824 "Invalid" 1823 "Invalid" 1822 "Invalid" 1821 "Invalid" 1820 "Invalid" 1819 "Invalid" 1818 "Invalid" 1817 "Invalid" 1816 "Invalid" 1815 "Invalid" 1814 "Invalid" 1813 "Invalid" 1812 "Invalid" 1811 "Invalid" 1810 "Invalid" 1809 "Invalid" 1808 "Invalid" 1807 "Invalid" 1806 "Invalid" 1805 "Invalid" 1804 "Invalid" 1803 "Invalid" 1802 "Invalid" 1801 "Invalid" ;
VAL_ 554 BCU_CellVlt040_RM 2047 "Invalid" 2046 "Invalid" 2045 "Invalid" 2044 "Invalid" 2043 "Invalid" 2042 "Invalid" 2041 "Invalid" 2040 "Invalid" 2039 "Invalid" 2038 "Invalid" 2037 "Invalid" 2036 "Invalid" 2035 "Invalid" 2034 "Invalid" 2033 "Invalid" 2032 "Invalid" 2031 "Invalid" 2030 "Invalid" 2029 "Invalid" 2028 "Invalid" 2027 "Invalid" 2026 "Invalid" 2025 "Invalid" 2024 "Invalid" 2023 "Invalid" 2022 "Invalid" 2021 "Invalid" 2020 "Invalid" 2019 "Invalid" 2018 "Invalid" 2017 "Invalid" 2016 "Invalid" 2015 "Invalid" 2014 "Invalid" 2013 "Invalid" 2012 "Invalid" 2011 "Invalid" 2010 "Invalid" 2009 "Invalid" 2008 "Invalid" 2007 "Invalid" 2006 "Invalid" 2005 "Invalid" 2004 "Invalid" 2003 "Invalid" 2002 "Invalid" 2001 "Invalid" 2000 "Invalid" 1999 "Invalid" 1998 "Invalid" 1997 "Invalid" 1996 "Invalid" 1995 "Invalid" 1994 "Invalid" 1993 "Invalid" 1992 "Invalid" 1991 "Invalid" 1990 "Invalid" 1989 "Invalid" 1988 "Invalid" 1987 "Invalid" 1986 "Invalid" 1985 "Invalid" 1984 "Invalid" 1983 "Invalid" 1982 "Invalid" 1981 "Invalid" 1980 "Invalid" 1979 "Invalid" 1978 "Invalid" 1977 "Invalid" 1976 "Invalid" 1975 "Invalid" 1974 "Invalid" 1973 "Invalid" 1972 "Invalid" 1971 "Invalid" 1970 "Invalid" 1969 "Invalid" 1968 "Invalid" 1967 "Invalid" 1966 "Invalid" 1965 "Invalid" 1964 "Invalid" 1963 "Invalid" 1962 "Invalid" 1961 "Invalid" 1960 "Invalid" 1959 "Invalid" 1958 "Invalid" 1957 "Invalid" 1956 "Invalid" 1955 "Invalid" 1954 "Invalid" 1953 "Invalid" 1952 "Invalid" 1951 "Invalid" 1950 "Invalid" 1949 "Invalid" 1948 "Invalid" 1947 "Invalid" 1946 "Invalid" 1945 "Invalid" 1944 "Invalid" 1943 "Invalid" 1942 "Invalid" 1941 "Invalid" 1940 "Invalid" 1939 "Invalid" 1938 "Invalid" 1937 "Invalid" 1936 "Invalid" 1935 "Invalid" 1934 "Invalid" 1933 "Invalid" 1932 "Invalid" 1931 "Invalid" 1930 "Invalid" 1929 "Invalid" 1928 "Invalid" 1927 "Invalid" 1926 "Invalid" 1925 "Invalid" 1924 "Invalid" 1923 "Invalid" 1922 "Invalid" 1921 "Invalid" 1920 "Invalid" 1919 "Invalid" 1918 "Invalid" 1917 "Invalid" 1916 "Invalid" 1915 "Invalid" 1914 "Invalid" 1913 "Invalid" 1912 "Invalid" 1911 "Invalid" 1910 "Invalid" 1909 "Invalid" 1908 "Invalid" 1907 "Invalid" 1906 "Invalid" 1905 "Invalid" 1904 "Invalid" 1903 "Invalid" 1902 "Invalid" 1901 "Invalid" 1900 "Invalid" 1899 "Invalid" 1898 "Invalid" 1897 "Invalid" 1896 "Invalid" 1895 "Invalid" 1894 "Invalid" 1893 "Invalid" 1892 "Invalid" 1891 "Invalid" 1890 "Invalid" 1889 "Invalid" 1888 "Invalid" 1887 "Invalid" 1886 "Invalid" 1885 "Invalid" 1884 "Invalid" 1883 "Invalid" 1882 "Invalid" 1881 "Invalid" 1880 "Invalid" 1879 "Invalid" 1878 "Invalid" 1877 "Invalid" 1876 "Invalid" 1875 "Invalid" 1874 "Invalid" 1873 "Invalid" 1872 "Invalid" 1871 "Invalid" 1870 "Invalid" 1869 "Invalid" 1868 "Invalid" 1867 "Invalid" 1866 "Invalid" 1865 "Invalid" 1864 "Invalid" 1863 "Invalid" 1862 "Invalid" 1861 "Invalid" 1860 "Invalid" 1859 "Invalid" 1858 "Invalid" 1857 "Invalid" 1856 "Invalid" 1855 "Invalid" 1854 "Invalid" 1853 "Invalid" 1852 "Invalid" 1851 "Invalid" 1850 "Invalid" 1849 "Invalid" 1848 "Invalid" 1847 "Invalid" 1846 "Invalid" 1845 "Invalid" 1844 "Invalid" 1843 "Invalid" 1842 "Invalid" 1841 "Invalid" 1840 "Invalid" 1839 "Invalid" 1838 "Invalid" 1837 "Invalid" 1836 "Invalid" 1835 "Invalid" 1834 "Invalid" 1833 "Invalid" 1832 "Invalid" 1831 "Invalid" 1830 "Invalid" 1829 "Invalid" 1828 "Invalid" 1827 "Invalid" 1826 "Invalid" 1825 "Invalid" 1824 "Invalid" 1823 "Invalid" 1822 "Invalid" 1821 "Invalid" 1820 "Invalid" 1819 "Invalid" 1818 "Invalid" 1817 "Invalid" 1816 "Invalid" 1815 "Invalid" 1814 "Invalid" 1813 "Invalid" 1812 "Invalid" 1811 "Invalid" 1810 "Invalid" 1809 "Invalid" 1808 "Invalid" 1807 "Invalid" 1806 "Invalid" 1805 "Invalid" 1804 "Invalid" 1803 "Invalid" 1802 "Invalid" 1801 "Invalid" ;
VAL_ 554 BCU_CellTmp008_RM 255 "Invalid" 254 "Invalid" 253 "Invalid" 252 "Invalid" 251 "Invalid" 250 "Invalid" 249 "Invalid" 248 "Invalid" 247 "Invalid" 246 "Invalid" 245 "Invalid" 244 "Invalid" 243 "Invalid" 242 "Invalid" 241 "Invalid" 240 "Invalid" 239 "Invalid" 238 "Invalid" 237 "Invalid" 236 "Invalid" 235 "Invalid" 234 "Invalid" 233 "Invalid" 232 "Invalid" 231 "Invalid" 230 "Invalid" 229 "Invalid" 228 "Invalid" 227 "Invalid" 226 "Invalid" 225 "Invalid" 224 "Invalid" 223 "Invalid" 222 "Invalid" 221 "Invalid" 220 "Invalid" 219 "Invalid" 218 "Invalid" 217 "Invalid" 216 "Invalid" 215 "Invalid" 214 "Invalid" 213 "Invalid" 212 "Invalid" 211 "Invalid" 210 "Invalid" 209 "Invalid" 208 "Invalid" 207 "Invalid" 206 "Invalid" 205 "Invalid" 204 "Invalid" 203 "Invalid" 202 "Invalid" 201 "Invalid" 200 "Invalid" 199 "Invalid" 198 "Invalid" 197 "Invalid" 196 "Invalid" 195 "Invalid" 194 "Invalid" 193 "Invalid" 192 "Invalid" 191 "Invalid" 190 "Invalid" 189 "Invalid" 188 "Invalid" 187 "Invalid" 186 "Invalid" 185 "Invalid" 184 "Invalid" 183 "Invalid" 182 "Invalid" 181 "Invalid" 180 "Invalid" 179 "Invalid" 178 "Invalid" 177 "Invalid" 176 "Invalid" 175 "Invalid" 174 "Invalid" 173 "Invalid" 172 "Invalid" 171 "Invalid" 170 "Invalid" 169 "Invalid" 168 "Invalid" 167 "Invalid" 166 "Invalid" 165 "Invalid" 164 "Invalid" 163 "Invalid" 162 "Invalid" 161 "Invalid" ;
VAL_ 555 BCU_CellVlt041_RM 2047 "Invalid" 2046 "Invalid" 2045 "Invalid" 2044 "Invalid" 2043 "Invalid" 2042 "Invalid" 2041 "Invalid" 2040 "Invalid" 2039 "Invalid" 2038 "Invalid" 2037 "Invalid" 2036 "Invalid" 2035 "Invalid" 2034 "Invalid" 2033 "Invalid" 2032 "Invalid" 2031 "Invalid" 2030 "Invalid" 2029 "Invalid" 2028 "Invalid" 2027 "Invalid" 2026 "Invalid" 2025 "Invalid" 2024 "Invalid" 2023 "Invalid" 2022 "Invalid" 2021 "Invalid" 2020 "Invalid" 2019 "Invalid" 2018 "Invalid" 2017 "Invalid" 2016 "Invalid" 2015 "Invalid" 2014 "Invalid" 2013 "Invalid" 2012 "Invalid" 2011 "Invalid" 2010 "Invalid" 2009 "Invalid" 2008 "Invalid" 2007 "Invalid" 2006 "Invalid" 2005 "Invalid" 2004 "Invalid" 2003 "Invalid" 2002 "Invalid" 2001 "Invalid" 2000 "Invalid" 1999 "Invalid" 1998 "Invalid" 1997 "Invalid" 1996 "Invalid" 1995 "Invalid" 1994 "Invalid" 1993 "Invalid" 1992 "Invalid" 1991 "Invalid" 1990 "Invalid" 1989 "Invalid" 1988 "Invalid" 1987 "Invalid" 1986 "Invalid" 1985 "Invalid" 1984 "Invalid" 1983 "Invalid" 1982 "Invalid" 1981 "Invalid" 1980 "Invalid" 1979 "Invalid" 1978 "Invalid" 1977 "Invalid" 1976 "Invalid" 1975 "Invalid" 1974 "Invalid" 1973 "Invalid" 1972 "Invalid" 1971 "Invalid" 1970 "Invalid" 1969 "Invalid" 1968 "Invalid" 1967 "Invalid" 1966 "Invalid" 1965 "Invalid" 1964 "Invalid" 1963 "Invalid" 1962 "Invalid" 1961 "Invalid" 1960 "Invalid" 1959 "Invalid" 1958 "Invalid" 1957 "Invalid" 1956 "Invalid" 1955 "Invalid" 1954 "Invalid" 1953 "Invalid" 1952 "Invalid" 1951 "Invalid" 1950 "Invalid" 1949 "Invalid" 1948 "Invalid" 1947 "Invalid" 1946 "Invalid" 1945 "Invalid" 1944 "Invalid" 1943 "Invalid" 1942 "Invalid" 1941 "Invalid" 1940 "Invalid" 1939 "Invalid" 1938 "Invalid" 1937 "Invalid" 1936 "Invalid" 1935 "Invalid" 1934 "Invalid" 1933 "Invalid" 1932 "Invalid" 1931 "Invalid" 1930 "Invalid" 1929 "Invalid" 1928 "Invalid" 1927 "Invalid" 1926 "Invalid" 1925 "Invalid" 1924 "Invalid" 1923 "Invalid" 1922 "Invalid" 1921 "Invalid" 1920 "Invalid" 1919 "Invalid" 1918 "Invalid" 1917 "Invalid" 1916 "Invalid" 1915 "Invalid" 1914 "Invalid" 1913 "Invalid" 1912 "Invalid" 1911 "Invalid" 1910 "Invalid" 1909 "Invalid" 1908 "Invalid" 1907 "Invalid" 1906 "Invalid" 1905 "Invalid" 1904 "Invalid" 1903 "Invalid" 1902 "Invalid" 1901 "Invalid" 1900 "Invalid" 1899 "Invalid" 1898 "Invalid" 1897 "Invalid" 1896 "Invalid" 1895 "Invalid" 1894 "Invalid" 1893 "Invalid" 1892 "Invalid" 1891 "Invalid" 1890 "Invalid" 1889 "Invalid" 1888 "Invalid" 1887 "Invalid" 1886 "Invalid" 1885 "Invalid" 1884 "Invalid" 1883 "Invalid" 1882 "Invalid" 1881 "Invalid" 1880 "Invalid" 1879 "Invalid" 1878 "Invalid" 1877 "Invalid" 1876 "Invalid" 1875 "Invalid" 1874 "Invalid" 1873 "Invalid" 1872 "Invalid" 1871 "Invalid" 1870 "Invalid" 1869 "Invalid" 1868 "Invalid" 1867 "Invalid" 1866 "Invalid" 1865 "Invalid" 1864 "Invalid" 1863 "Invalid" 1862 "Invalid" 1861 "Invalid" 1860 "Invalid" 1859 "Invalid" 1858 "Invalid" 1857 "Invalid" 1856 "Invalid" 1855 "Invalid" 1854 "Invalid" 1853 "Invalid" 1852 "Invalid" 1851 "Invalid" 1850 "Invalid" 1849 "Invalid" 1848 "Invalid" 1847 "Invalid" 1846 "Invalid" 1845 "Invalid" 1844 "Invalid" 1843 "Invalid" 1842 "Invalid" 1841 "Invalid" 1840 "Invalid" 1839 "Invalid" 1838 "Invalid" 1837 "Invalid" 1836 "Invalid" 1835 "Invalid" 1834 "Invalid" 1833 "Invalid" 1832 "Invalid" 1831 "Invalid" 1830 "Invalid" 1829 "Invalid" 1828 "Invalid" 1827 "Invalid" 1826 "Invalid" 1825 "Invalid" 1824 "Invalid" 1823 "Invalid" 1822 "Invalid" 1821 "Invalid" 1820 "Invalid" 1819 "Invalid" 1818 "Invalid" 1817 "Invalid" 1816 "Invalid" 1815 "Invalid" 1814 "Invalid" 1813 "Invalid" 1812 "Invalid" 1811 "Invalid" 1810 "Invalid" 1809 "Invalid" 1808 "Invalid" 1807 "Invalid" 1806 "Invalid" 1805 "Invalid" 1804 "Invalid" 1803 "Invalid" 1802 "Invalid" 1801 "Invalid" ;
VAL_ 555 BCU_CellVlt042_RM 2047 "Invalid" 2046 "Invalid" 2045 "Invalid" 2044 "Invalid" 2043 "Invalid" 2042 "Invalid" 2041 "Invalid" 2040 "Invalid" 2039 "Invalid" 2038 "Invalid" 2037 "Invalid" 2036 "Invalid" 2035 "Invalid" 2034 "Invalid" 2033 "Invalid" 2032 "Invalid" 2031 "Invalid" 2030 "Invalid" 2029 "Invalid" 2028 "Invalid" 2027 "Invalid" 2026 "Invalid" 2025 "Invalid" 2024 "Invalid" 2023 "Invalid" 2022 "Invalid" 2021 "Invalid" 2020 "Invalid" 2019 "Invalid" 2018 "Invalid" 2017 "Invalid" 2016 "Invalid" 2015 "Invalid" 2014 "Invalid" 2013 "Invalid" 2012 "Invalid" 2011 "Invalid" 2010 "Invalid" 2009 "Invalid" 2008 "Invalid" 2007 "Invalid" 2006 "Invalid" 2005 "Invalid" 2004 "Invalid" 2003 "Invalid" 2002 "Invalid" 2001 "Invalid" 2000 "Invalid" 1999 "Invalid" 1998 "Invalid" 1997 "Invalid" 1996 "Invalid" 1995 "Invalid" 1994 "Invalid" 1993 "Invalid" 1992 "Invalid" 1991 "Invalid" 1990 "Invalid" 1989 "Invalid" 1988 "Invalid" 1987 "Invalid" 1986 "Invalid" 1985 "Invalid" 1984 "Invalid" 1983 "Invalid" 1982 "Invalid" 1981 "Invalid" 1980 "Invalid" 1979 "Invalid" 1978 "Invalid" 1977 "Invalid" 1976 "Invalid" 1975 "Invalid" 1974 "Invalid" 1973 "Invalid" 1972 "Invalid" 1971 "Invalid" 1970 "Invalid" 1969 "Invalid" 1968 "Invalid" 1967 "Invalid" 1966 "Invalid" 1965 "Invalid" 1964 "Invalid" 1963 "Invalid" 1962 "Invalid" 1961 "Invalid" 1960 "Invalid" 1959 "Invalid" 1958 "Invalid" 1957 "Invalid" 1956 "Invalid" 1955 "Invalid" 1954 "Invalid" 1953 "Invalid" 1952 "Invalid" 1951 "Invalid" 1950 "Invalid" 1949 "Invalid" 1948 "Invalid" 1947 "Invalid" 1946 "Invalid" 1945 "Invalid" 1944 "Invalid" 1943 "Invalid" 1942 "Invalid" 1941 "Invalid" 1940 "Invalid" 1939 "Invalid" 1938 "Invalid" 1937 "Invalid" 1936 "Invalid" 1935 "Invalid" 1934 "Invalid" 1933 "Invalid" 1932 "Invalid" 1931 "Invalid" 1930 "Invalid" 1929 "Invalid" 1928 "Invalid" 1927 "Invalid" 1926 "Invalid" 1925 "Invalid" 1924 "Invalid" 1923 "Invalid" 1922 "Invalid" 1921 "Invalid" 1920 "Invalid" 1919 "Invalid" 1918 "Invalid" 1917 "Invalid" 1916 "Invalid" 1915 "Invalid" 1914 "Invalid" 1913 "Invalid" 1912 "Invalid" 1911 "Invalid" 1910 "Invalid" 1909 "Invalid" 1908 "Invalid" 1907 "Invalid" 1906 "Invalid" 1905 "Invalid" 1904 "Invalid" 1903 "Invalid" 1902 "Invalid" 1901 "Invalid" 1900 "Invalid" 1899 "Invalid" 1898 "Invalid" 1897 "Invalid" 1896 "Invalid" 1895 "Invalid" 1894 "Invalid" 1893 "Invalid" 1892 "Invalid" 1891 "Invalid" 1890 "Invalid" 1889 "Invalid" 1888 "Invalid" 1887 "Invalid" 1886 "Invalid" 1885 "Invalid" 1884 "Invalid" 1883 "Invalid" 1882 "Invalid" 1881 "Invalid" 1880 "Invalid" 1879 "Invalid" 1878 "Invalid" 1877 "Invalid" 1876 "Invalid" 1875 "Invalid" 1874 "Invalid" 1873 "Invalid" 1872 "Invalid" 1871 "Invalid" 1870 "Invalid" 1869 "Invalid" 1868 "Invalid" 1867 "Invalid" 1866 "Invalid" 1865 "Invalid" 1864 "Invalid" 1863 "Invalid" 1862 "Invalid" 1861 "Invalid" 1860 "Invalid" 1859 "Invalid" 1858 "Invalid" 1857 "Invalid" 1856 "Invalid" 1855 "Invalid" 1854 "Invalid" 1853 "Invalid" 1852 "Invalid" 1851 "Invalid" 1850 "Invalid" 1849 "Invalid" 1848 "Invalid" 1847 "Invalid" 1846 "Invalid" 1845 "Invalid" 1844 "Invalid" 1843 "Invalid" 1842 "Invalid" 1841 "Invalid" 1840 "Invalid" 1839 "Invalid" 1838 "Invalid" 1837 "Invalid" 1836 "Invalid" 1835 "Invalid" 1834 "Invalid" 1833 "Invalid" 1832 "Invalid" 1831 "Invalid" 1830 "Invalid" 1829 "Invalid" 1828 "Invalid" 1827 "Invalid" 1826 "Invalid" 1825 "Invalid" 1824 "Invalid" 1823 "Invalid" 1822 "Invalid" 1821 "Invalid" 1820 "Invalid" 1819 "Invalid" 1818 "Invalid" 1817 "Invalid" 1816 "Invalid" 1815 "Invalid" 1814 "Invalid" 1813 "Invalid" 1812 "Invalid" 1811 "Invalid" 1810 "Invalid" 1809 "Invalid" 1808 "Invalid" 1807 "Invalid" 1806 "Invalid" 1805 "Invalid" 1804 "Invalid" 1803 "Invalid" 1802 "Invalid" 1801 "Invalid" ;
VAL_ 555 BCU_CellVlt043_RM 2047 "Invalid" 2046 "Invalid" 2045 "Invalid" 2044 "Invalid" 2043 "Invalid" 2042 "Invalid" 2041 "Invalid" 2040 "Invalid" 2039 "Invalid" 2038 "Invalid" 2037 "Invalid" 2036 "Invalid" 2035 "Invalid" 2034 "Invalid" 2033 "Invalid" 2032 "Invalid" 2031 "Invalid" 2030 "Invalid" 2029 "Invalid" 2028 "Invalid" 2027 "Invalid" 2026 "Invalid" 2025 "Invalid" 2024 "Invalid" 2023 "Invalid" 2022 "Invalid" 2021 "Invalid" 2020 "Invalid" 2019 "Invalid" 2018 "Invalid" 2017 "Invalid" 2016 "Invalid" 2015 "Invalid" 2014 "Invalid" 2013 "Invalid" 2012 "Invalid" 2011 "Invalid" 2010 "Invalid" 2009 "Invalid" 2008 "Invalid" 2007 "Invalid" 2006 "Invalid" 2005 "Invalid" 2004 "Invalid" 2003 "Invalid" 2002 "Invalid" 2001 "Invalid" 2000 "Invalid" 1999 "Invalid" 1998 "Invalid" 1997 "Invalid" 1996 "Invalid" 1995 "Invalid" 1994 "Invalid" 1993 "Invalid" 1992 "Invalid" 1991 "Invalid" 1990 "Invalid" 1989 "Invalid" 1988 "Invalid" 1987 "Invalid" 1986 "Invalid" 1985 "Invalid" 1984 "Invalid" 1983 "Invalid" 1982 "Invalid" 1981 "Invalid" 1980 "Invalid" 1979 "Invalid" 1978 "Invalid" 1977 "Invalid" 1976 "Invalid" 1975 "Invalid" 1974 "Invalid" 1973 "Invalid" 1972 "Invalid" 1971 "Invalid" 1970 "Invalid" 1969 "Invalid" 1968 "Invalid" 1967 "Invalid" 1966 "Invalid" 1965 "Invalid" 1964 "Invalid" 1963 "Invalid" 1962 "Invalid" 1961 "Invalid" 1960 "Invalid" 1959 "Invalid" 1958 "Invalid" 1957 "Invalid" 1956 "Invalid" 1955 "Invalid" 1954 "Invalid" 1953 "Invalid" 1952 "Invalid" 1951 "Invalid" 1950 "Invalid" 1949 "Invalid" 1948 "Invalid" 1947 "Invalid" 1946 "Invalid" 1945 "Invalid" 1944 "Invalid" 1943 "Invalid" 1942 "Invalid" 1941 "Invalid" 1940 "Invalid" 1939 "Invalid" 1938 "Invalid" 1937 "Invalid" 1936 "Invalid" 1935 "Invalid" 1934 "Invalid" 1933 "Invalid" 1932 "Invalid" 1931 "Invalid" 1930 "Invalid" 1929 "Invalid" 1928 "Invalid" 1927 "Invalid" 1926 "Invalid" 1925 "Invalid" 1924 "Invalid" 1923 "Invalid" 1922 "Invalid" 1921 "Invalid" 1920 "Invalid" 1919 "Invalid" 1918 "Invalid" 1917 "Invalid" 1916 "Invalid" 1915 "Invalid" 1914 "Invalid" 1913 "Invalid" 1912 "Invalid" 1911 "Invalid" 1910 "Invalid" 1909 "Invalid" 1908 "Invalid" 1907 "Invalid" 1906 "Invalid" 1905 "Invalid" 1904 "Invalid" 1903 "Invalid" 1902 "Invalid" 1901 "Invalid" 1900 "Invalid" 1899 "Invalid" 1898 "Invalid" 1897 "Invalid" 1896 "Invalid" 1895 "Invalid" 1894 "Invalid" 1893 "Invalid" 1892 "Invalid" 1891 "Invalid" 1890 "Invalid" 1889 "Invalid" 1888 "Invalid" 1887 "Invalid" 1886 "Invalid" 1885 "Invalid" 1884 "Invalid" 1883 "Invalid" 1882 "Invalid" 1881 "Invalid" 1880 "Invalid" 1879 "Invalid" 1878 "Invalid" 1877 "Invalid" 1876 "Invalid" 1875 "Invalid" 1874 "Invalid" 1873 "Invalid" 1872 "Invalid" 1871 "Invalid" 1870 "Invalid" 1869 "Invalid" 1868 "Invalid" 1867 "Invalid" 1866 "Invalid" 1865 "Invalid" 1864 "Invalid" 1863 "Invalid" 1862 "Invalid" 1861 "Invalid" 1860 "Invalid" 1859 "Invalid" 1858 "Invalid" 1857 "Invalid" 1856 "Invalid" 1855 "Invalid" 1854 "Invalid" 1853 "Invalid" 1852 "Invalid" 1851 "Invalid" 1850 "Invalid" 1849 "Invalid" 1848 "Invalid" 1847 "Invalid" 1846 "Invalid" 1845 "Invalid" 1844 "Invalid" 1843 "Invalid" 1842 "Invalid" 1841 "Invalid" 1840 "Invalid" 1839 "Invalid" 1838 "Invalid" 1837 "Invalid" 1836 "Invalid" 1835 "Invalid" 1834 "Invalid" 1833 "Invalid" 1832 "Invalid" 1831 "Invalid" 1830 "Invalid" 1829 "Invalid" 1828 "Invalid" 1827 "Invalid" 1826 "Invalid" 1825 "Invalid" 1824 "Invalid" 1823 "Invalid" 1822 "Invalid" 1821 "Invalid" 1820 "Invalid" 1819 "Invalid" 1818 "Invalid" 1817 "Invalid" 1816 "Invalid" 1815 "Invalid" 1814 "Invalid" 1813 "Invalid" 1812 "Invalid" 1811 "Invalid" 1810 "Invalid" 1809 "Invalid" 1808 "Invalid" 1807 "Invalid" 1806 "Invalid" 1805 "Invalid" 1804 "Invalid" 1803 "Invalid" 1802 "Invalid" 1801 "Invalid" ;
VAL_ 555 BCU_CellVlt044_RM 2047 "Invalid" 2046 "Invalid" 2045 "Invalid" 2044 "Invalid" 2043 "Invalid" 2042 "Invalid" 2041 "Invalid" 2040 "Invalid" 2039 "Invalid" 2038 "Invalid" 2037 "Invalid" 2036 "Invalid" 2035 "Invalid" 2034 "Invalid" 2033 "Invalid" 2032 "Invalid" 2031 "Invalid" 2030 "Invalid" 2029 "Invalid" 2028 "Invalid" 2027 "Invalid" 2026 "Invalid" 2025 "Invalid" 2024 "Invalid" 2023 "Invalid" 2022 "Invalid" 2021 "Invalid" 2020 "Invalid" 2019 "Invalid" 2018 "Invalid" 2017 "Invalid" 2016 "Invalid" 2015 "Invalid" 2014 "Invalid" 2013 "Invalid" 2012 "Invalid" 2011 "Invalid" 2010 "Invalid" 2009 "Invalid" 2008 "Invalid" 2007 "Invalid" 2006 "Invalid" 2005 "Invalid" 2004 "Invalid" 2003 "Invalid" 2002 "Invalid" 2001 "Invalid" 2000 "Invalid" 1999 "Invalid" 1998 "Invalid" 1997 "Invalid" 1996 "Invalid" 1995 "Invalid" 1994 "Invalid" 1993 "Invalid" 1992 "Invalid" 1991 "Invalid" 1990 "Invalid" 1989 "Invalid" 1988 "Invalid" 1987 "Invalid" 1986 "Invalid" 1985 "Invalid" 1984 "Invalid" 1983 "Invalid" 1982 "Invalid" 1981 "Invalid" 1980 "Invalid" 1979 "Invalid" 1978 "Invalid" 1977 "Invalid" 1976 "Invalid" 1975 "Invalid" 1974 "Invalid" 1973 "Invalid" 1972 "Invalid" 1971 "Invalid" 1970 "Invalid" 1969 "Invalid" 1968 "Invalid" 1967 "Invalid" 1966 "Invalid" 1965 "Invalid" 1964 "Invalid" 1963 "Invalid" 1962 "Invalid" 1961 "Invalid" 1960 "Invalid" 1959 "Invalid" 1958 "Invalid" 1957 "Invalid" 1956 "Invalid" 1955 "Invalid" 1954 "Invalid" 1953 "Invalid" 1952 "Invalid" 1951 "Invalid" 1950 "Invalid" 1949 "Invalid" 1948 "Invalid" 1947 "Invalid" 1946 "Invalid" 1945 "Invalid" 1944 "Invalid" 1943 "Invalid" 1942 "Invalid" 1941 "Invalid" 1940 "Invalid" 1939 "Invalid" 1938 "Invalid" 1937 "Invalid" 1936 "Invalid" 1935 "Invalid" 1934 "Invalid" 1933 "Invalid" 1932 "Invalid" 1931 "Invalid" 1930 "Invalid" 1929 "Invalid" 1928 "Invalid" 1927 "Invalid" 1926 "Invalid" 1925 "Invalid" 1924 "Invalid" 1923 "Invalid" 1922 "Invalid" 1921 "Invalid" 1920 "Invalid" 1919 "Invalid" 1918 "Invalid" 1917 "Invalid" 1916 "Invalid" 1915 "Invalid" 1914 "Invalid" 1913 "Invalid" 1912 "Invalid" 1911 "Invalid" 1910 "Invalid" 1909 "Invalid" 1908 "Invalid" 1907 "Invalid" 1906 "Invalid" 1905 "Invalid" 1904 "Invalid" 1903 "Invalid" 1902 "Invalid" 1901 "Invalid" 1900 "Invalid" 1899 "Invalid" 1898 "Invalid" 1897 "Invalid" 1896 "Invalid" 1895 "Invalid" 1894 "Invalid" 1893 "Invalid" 1892 "Invalid" 1891 "Invalid" 1890 "Invalid" 1889 "Invalid" 1888 "Invalid" 1887 "Invalid" 1886 "Invalid" 1885 "Invalid" 1884 "Invalid" 1883 "Invalid" 1882 "Invalid" 1881 "Invalid" 1880 "Invalid" 1879 "Invalid" 1878 "Invalid" 1877 "Invalid" 1876 "Invalid" 1875 "Invalid" 1874 "Invalid" 1873 "Invalid" 1872 "Invalid" 1871 "Invalid" 1870 "Invalid" 1869 "Invalid" 1868 "Invalid" 1867 "Invalid" 1866 "Invalid" 1865 "Invalid" 1864 "Invalid" 1863 "Invalid" 1862 "Invalid" 1861 "Invalid" 1860 "Invalid" 1859 "Invalid" 1858 "Invalid" 1857 "Invalid" 1856 "Invalid" 1855 "Invalid" 1854 "Invalid" 1853 "Invalid" 1852 "Invalid" 1851 "Invalid" 1850 "Invalid" 1849 "Invalid" 1848 "Invalid" 1847 "Invalid" 1846 "Invalid" 1845 "Invalid" 1844 "Invalid" 1843 "Invalid" 1842 "Invalid" 1841 "Invalid" 1840 "Invalid" 1839 "Invalid" 1838 "Invalid" 1837 "Invalid" 1836 "Invalid" 1835 "Invalid" 1834 "Invalid" 1833 "Invalid" 1832 "Invalid" 1831 "Invalid" 1830 "Invalid" 1829 "Invalid" 1828 "Invalid" 1827 "Invalid" 1826 "Invalid" 1825 "Invalid" 1824 "Invalid" 1823 "Invalid" 1822 "Invalid" 1821 "Invalid" 1820 "Invalid" 1819 "Invalid" 1818 "Invalid" 1817 "Invalid" 1816 "Invalid" 1815 "Invalid" 1814 "Invalid" 1813 "Invalid" 1812 "Invalid" 1811 "Invalid" 1810 "Invalid" 1809 "Invalid" 1808 "Invalid" 1807 "Invalid" 1806 "Invalid" 1805 "Invalid" 1804 "Invalid" 1803 "Invalid" 1802 "Invalid" 1801 "Invalid" ;
VAL_ 555 BCU_CellVlt045_RM 2047 "Invalid" 2046 "Invalid" 2045 "Invalid" 2044 "Invalid" 2043 "Invalid" 2042 "Invalid" 2041 "Invalid" 2040 "Invalid" 2039 "Invalid" 2038 "Invalid" 2037 "Invalid" 2036 "Invalid" 2035 "Invalid" 2034 "Invalid" 2033 "Invalid" 2032 "Invalid" 2031 "Invalid" 2030 "Invalid" 2029 "Invalid" 2028 "Invalid" 2027 "Invalid" 2026 "Invalid" 2025 "Invalid" 2024 "Invalid" 2023 "Invalid" 2022 "Invalid" 2021 "Invalid" 2020 "Invalid" 2019 "Invalid" 2018 "Invalid" 2017 "Invalid" 2016 "Invalid" 2015 "Invalid" 2014 "Invalid" 2013 "Invalid" 2012 "Invalid" 2011 "Invalid" 2010 "Invalid" 2009 "Invalid" 2008 "Invalid" 2007 "Invalid" 2006 "Invalid" 2005 "Invalid" 2004 "Invalid" 2003 "Invalid" 2002 "Invalid" 2001 "Invalid" 2000 "Invalid" 1999 "Invalid" 1998 "Invalid" 1997 "Invalid" 1996 "Invalid" 1995 "Invalid" 1994 "Invalid" 1993 "Invalid" 1992 "Invalid" 1991 "Invalid" 1990 "Invalid" 1989 "Invalid" 1988 "Invalid" 1987 "Invalid" 1986 "Invalid" 1985 "Invalid" 1984 "Invalid" 1983 "Invalid" 1982 "Invalid" 1981 "Invalid" 1980 "Invalid" 1979 "Invalid" 1978 "Invalid" 1977 "Invalid" 1976 "Invalid" 1975 "Invalid" 1974 "Invalid" 1973 "Invalid" 1972 "Invalid" 1971 "Invalid" 1970 "Invalid" 1969 "Invalid" 1968 "Invalid" 1967 "Invalid" 1966 "Invalid" 1965 "Invalid" 1964 "Invalid" 1963 "Invalid" 1962 "Invalid" 1961 "Invalid" 1960 "Invalid" 1959 "Invalid" 1958 "Invalid" 1957 "Invalid" 1956 "Invalid" 1955 "Invalid" 1954 "Invalid" 1953 "Invalid" 1952 "Invalid" 1951 "Invalid" 1950 "Invalid" 1949 "Invalid" 1948 "Invalid" 1947 "Invalid" 1946 "Invalid" 1945 "Invalid" 1944 "Invalid" 1943 "Invalid" 1942 "Invalid" 1941 "Invalid" 1940 "Invalid" 1939 "Invalid" 1938 "Invalid" 1937 "Invalid" 1936 "Invalid" 1935 "Invalid" 1934 "Invalid" 1933 "Invalid" 1932 "Invalid" 1931 "Invalid" 1930 "Invalid" 1929 "Invalid" 1928 "Invalid" 1927 "Invalid" 1926 "Invalid" 1925 "Invalid" 1924 "Invalid" 1923 "Invalid" 1922 "Invalid" 1921 "Invalid" 1920 "Invalid" 1919 "Invalid" 1918 "Invalid" 1917 "Invalid" 1916 "Invalid" 1915 "Invalid" 1914 "Invalid" 1913 "Invalid" 1912 "Invalid" 1911 "Invalid" 1910 "Invalid" 1909 "Invalid" 1908 "Invalid" 1907 "Invalid" 1906 "Invalid" 1905 "Invalid" 1904 "Invalid" 1903 "Invalid" 1902 "Invalid" 1901 "Invalid" 1900 "Invalid" 1899 "Invalid" 1898 "Invalid" 1897 "Invalid" 1896 "Invalid" 1895 "Invalid" 1894 "Invalid" 1893 "Invalid" 1892 "Invalid" 1891 "Invalid" 1890 "Invalid" 1889 "Invalid" 1888 "Invalid" 1887 "Invalid" 1886 "Invalid" 1885 "Invalid" 1884 "Invalid" 1883 "Invalid" 1882 "Invalid" 1881 "Invalid" 1880 "Invalid" 1879 "Invalid" 1878 "Invalid" 1877 "Invalid" 1876 "Invalid" 1875 "Invalid" 1874 "Invalid" 1873 "Invalid" 1872 "Invalid" 1871 "Invalid" 1870 "Invalid" 1869 "Invalid" 1868 "Invalid" 1867 "Invalid" 1866 "Invalid" 1865 "Invalid" 1864 "Invalid" 1863 "Invalid" 1862 "Invalid" 1861 "Invalid" 1860 "Invalid" 1859 "Invalid" 1858 "Invalid" 1857 "Invalid" 1856 "Invalid" 1855 "Invalid" 1854 "Invalid" 1853 "Invalid" 1852 "Invalid" 1851 "Invalid" 1850 "Invalid" 1849 "Invalid" 1848 "Invalid" 1847 "Invalid" 1846 "Invalid" 1845 "Invalid" 1844 "Invalid" 1843 "Invalid" 1842 "Invalid" 1841 "Invalid" 1840 "Invalid" 1839 "Invalid" 1838 "Invalid" 1837 "Invalid" 1836 "Invalid" 1835 "Invalid" 1834 "Invalid" 1833 "Invalid" 1832 "Invalid" 1831 "Invalid" 1830 "Invalid" 1829 "Invalid" 1828 "Invalid" 1827 "Invalid" 1826 "Invalid" 1825 "Invalid" 1824 "Invalid" 1823 "Invalid" 1822 "Invalid" 1821 "Invalid" 1820 "Invalid" 1819 "Invalid" 1818 "Invalid" 1817 "Invalid" 1816 "Invalid" 1815 "Invalid" 1814 "Invalid" 1813 "Invalid" 1812 "Invalid" 1811 "Invalid" 1810 "Invalid" 1809 "Invalid" 1808 "Invalid" 1807 "Invalid" 1806 "Invalid" 1805 "Invalid" 1804 "Invalid" 1803 "Invalid" 1802 "Invalid" 1801 "Invalid" ;
VAL_ 555 BCU_CellTmp009_RM 255 "Invalid" 254 "Invalid" 253 "Invalid" 252 "Invalid" 251 "Invalid" 250 "Invalid" 249 "Invalid" 248 "Invalid" 247 "Invalid" 246 "Invalid" 245 "Invalid" 244 "Invalid" 243 "Invalid" 242 "Invalid" 241 "Invalid" 240 "Invalid" 239 "Invalid" 238 "Invalid" 237 "Invalid" 236 "Invalid" 235 "Invalid" 234 "Invalid" 233 "Invalid" 232 "Invalid" 231 "Invalid" 230 "Invalid" 229 "Invalid" 228 "Invalid" 227 "Invalid" 226 "Invalid" 225 "Invalid" 224 "Invalid" 223 "Invalid" 222 "Invalid" 221 "Invalid" 220 "Invalid" 219 "Invalid" 218 "Invalid" 217 "Invalid" 216 "Invalid" 215 "Invalid" 214 "Invalid" 213 "Invalid" 212 "Invalid" 211 "Invalid" 210 "Invalid" 209 "Invalid" 208 "Invalid" 207 "Invalid" 206 "Invalid" 205 "Invalid" 204 "Invalid" 203 "Invalid" 202 "Invalid" 201 "Invalid" 200 "Invalid" 199 "Invalid" 198 "Invalid" 197 "Invalid" 196 "Invalid" 195 "Invalid" 194 "Invalid" 193 "Invalid" 192 "Invalid" 191 "Invalid" 190 "Invalid" 189 "Invalid" 188 "Invalid" 187 "Invalid" 186 "Invalid" 185 "Invalid" 184 "Invalid" 183 "Invalid" 182 "Invalid" 181 "Invalid" 180 "Invalid" 179 "Invalid" 178 "Invalid" 177 "Invalid" 176 "Invalid" 175 "Invalid" 174 "Invalid" 173 "Invalid" 172 "Invalid" 171 "Invalid" 170 "Invalid" 169 "Invalid" 168 "Invalid" 167 "Invalid" 166 "Invalid" 165 "Invalid" 164 "Invalid" 163 "Invalid" 162 "Invalid" 161 "Invalid" ;
VAL_ 15 ACU_CrshActv 7 "Reserved" 6 "Reserved" 5 "Reserved" 4 "Rear Side" 3 "Right Hand Side" 2 "Left Hand Side" 1 "Front First Level" 0 "No Crash" ;
